VERSION ""

NS_ :

BS_:
BU_: Turbocharger OnBoardDataLogger OffBoardDiagnosticTool2 OffBoardDiagnosticTool1 FileServer ParkingBrakeController SeatControl2 FanDriveController SteeringColumnUnit CommunicationUnitRadio CommunicationUnitSatellite CommunicationUnitCellular PropulsionBatteryCharger ChassisController2 ChassisController1 EngineValveControl AuxiliaryHeater2 AuxiliaryHeater1 ClutchUnit RampControl InformationSystem1 SuspensionSystemController2 OilSensor VehicleDynamicStability ExhaustEmissionController TransmissionDisplay2 TransmissionDisplay1 ClimateControl2 WaterPumpController RearAxleSteeringController LightingOperatorControl SeatController1 IgnitionController2 IgnitionController1 TirePressureController CabController2 CabController1 PneumaticSystemController SuspensionSystemController1 HydraulicPumpController EnduranceBrakingSystem RetarderExhaustEngine2 OnBoardDiagnosticUnit HeadwayController RetarderExhaustEngine1 CabDisplay1 ManagementComputer VirtualTerminal OffVehicleGateway PowerTakeOffFront HitchControl AuxiliaryValveControl BodyController TractorTrailerBridge1 StarterSystem ElectricalSystem VehicleSecurity VehicleNavigation AerodynamicControl ElectricalChargingSystem ClimateControl1 TripRecorder InstrumentCluster SuspensionDriveAxle2 SuspensionDriveAxle1 SuspensionSteerAxle SteeringController FuelSystem CruiseControl RetarderDriveline RetarderEngine BrakesDriveAxle2 BrakesDriveAxle1 BrakesSystemController BrakesSteerAxle AxleDrive2 AxleDrive1 AxleSteering PowerTakeOff ShiftConsoleSecondary ShiftConsolePrimary Transmission2 Transmission1 Engine2 Engine1 Guidance Unnamed9933

BO_ 2566768382 CSA: 8 Vector__XXX
   SG_ EngStartEnableDevice2Config : 12|4@1+ (1,0) [0|15] "" Vector__XXX
   SG_ EngStartEnableDevice1Config : 8|4@1+ (1,0) [0|15] "" Vector__XXX
   SG_ EngStartEnableDevice2 : 2|2@1+ (1,0) [0|3] "" Vector__XXX
   SG_ EngStartEnableDevice1 : 0|2@1+ (1,0) [0|3] "" Vector__XXX

BO_ 2566811902 CVW: 8 Vector__XXX
   SG_ PoweredVehicleWeight : 0|16@1+ (10,0) [0|642550] "kg" Vector__XXX
   SG_ GrossCombinationVehicleWeight : 16|16@1+ (10,0) [0|642550] "kg" Vector__XXX

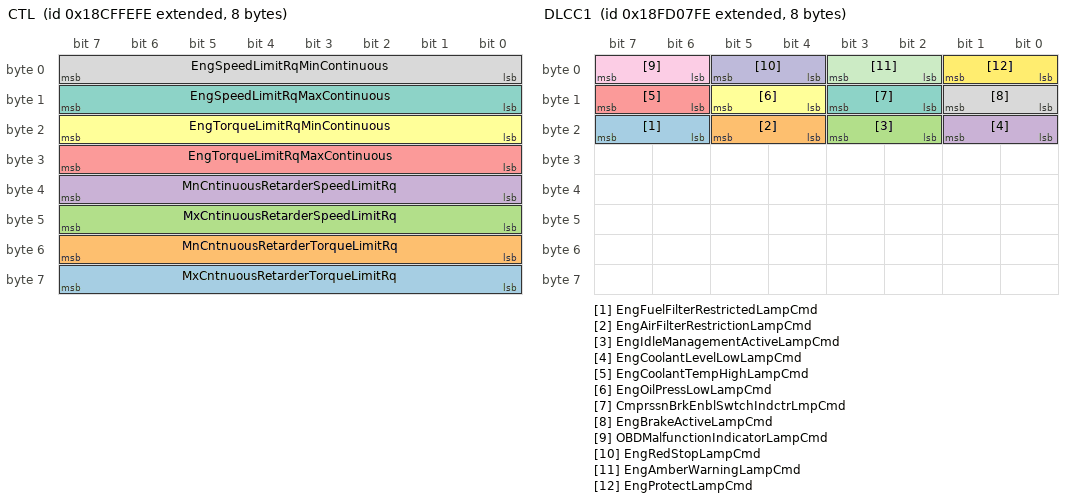
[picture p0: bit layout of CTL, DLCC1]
BO_ 2563768062 CTL: 8 Vector__XXX
   SG_ MxCntnuousRetarderTorqueLimitRq : 56|8@1+ (1,-125) [-125|125] "%" Vector__XXX
   SG_ MnCntnuousRetarderTorqueLimitRq : 48|8@1+ (1,-125) [-125|125] "%" Vector__XXX
   SG_ MxCntinuousRetarderSpeedLimitRq : 40|8@1+ (32,0) [0|8000] "rpm" Vector__XXX
   SG_ MnCntinuousRetarderSpeedLimitRq : 32|8@1+ (32,0) [0|8000] "rpm" Vector__XXX
   SG_ EngTorqueLimitRqMaxContinuous : 24|8@1+ (1,-125) [-125|125] "%" Vector__XXX
   SG_ EngTorqueLimitRqMinContinuous : 16|8@1+ (1,-125) [-125|125] "%" Vector__XXX
   SG_ EngSpeedLimitRqMaxContinuous : 8|8@1+ (32,0) [0|8000] "rpm" Vector__XXX
   SG_ EngSpeedLimitRqMinContinuous : 0|8@1+ (32,0) [0|8000] "rpm" Vector__XXX

BO_ 2633924862 CT6: 8 Vector__XXX
   SG_ EngAverageCombustionTime : 16|16@1+ (0.01,0) [0|642.55] "ms" Vector__XXX
   SG_ EngDesiredCombustionTime : 0|16@1+ (0.01,0) [0|642.55] "ms" Vector__XXX

BO_ 2633924606 CT5: 8 Vector__XXX
   SG_ EngCyl20CombustionTime : 48|16@1+ (0.01,0) [0|642.55] "ms" Vector__XXX
   SG_ EngCyl19CombustionTime : 32|16@1+ (0.01,0) [0|642.55] "ms" Vector__XXX
   SG_ EngCyl18CombustionTime : 16|16@1+ (0.01,0) [0|642.55] "ms" Vector__XXX
   SG_ EngCyl17CombustionTime : 0|16@1+ (0.01,0) [0|642.55] "ms" Vector__XXX

BO_ 2633924350 CT4: 8 Vector__XXX
   SG_ EngCyl16CombustionTime : 48|16@1+ (0.01,0) [0|642.55] "ms" Vector__XXX
   SG_ EngCyl15CombustionTime : 32|16@1+ (0.01,0) [0|642.55] "ms" Vector__XXX
   SG_ EngCyl14CombustionTime : 16|16@1+ (0.01,0) [0|642.55] "ms" Vector__XXX
   SG_ EngCyl13CombustionTime : 0|16@1+ (0.01,0) [0|642.55] "ms" Vector__XXX

BO_ 2633924094 CT3: 8 Vector__XXX
   SG_ EngCyl12CombustionTime : 48|16@1+ (0.01,0) [0|642.55] "ms" Vector__XXX
   SG_ EngCyl11CombustionTime : 32|16@1+ (0.01,0) [0|642.55] "ms" Vector__XXX
   SG_ EngCyl10CombustionTime : 16|16@1+ (0.01,0) [0|642.55] "ms" Vector__XXX
   SG_ EngCyl9CombustionTime : 0|16@1+ (0.01,0) [0|642.55] "ms" Vector__XXX

BO_ 2633923838 CT2: 8 Vector__XXX
   SG_ EngCyl8CombustionTime : 48|16@1+ (0.01,0) [0|642.55] "ms" Vector__XXX
   SG_ EngCyl7CombustionTime : 32|16@1+ (0.01,0) [0|642.55] "ms" Vector__XXX
   SG_ EngCyl6CombustionTime : 16|16@1+ (0.01,0) [0|642.55] "ms" Vector__XXX
   SG_ EngCyl5CombustionTime : 0|16@1+ (0.01,0) [0|642.55] "ms" Vector__XXX

BO_ 2633923582 CT1: 8 Vector__XXX
   SG_ EngCyl4CombustionTime : 48|16@1+ (0.01,0) [0|642.55] "ms" Vector__XXX
   SG_ EngCyl3CombustionTime : 32|16@1+ (0.01,0) [0|642.55] "ms" Vector__XXX
   SG_ EngCyl2CombustionTime : 16|16@1+ (0.01,0) [0|642.55] "ms" Vector__XXX
   SG_ EngCyl1CombustionTime : 0|16@1+ (0.01,0) [0|642.55] "ms" Vector__XXX

BO_ 2633878014 CMI: 8 Vector__XXX
   SG_ TotalCountOfConfigChangesMade : 0|16@1+ (1,0) [0|64255] "counts" Vector__XXX

BO_ 2566771966 CM3: 8 Vector__XXX
   SG_ TransOilLevelRq : 16|2@1+ (1,0) [0|3] "" Vector__XXX
   SG_ FifthWheelReleaseCtrl : 8|2@1+ (1,0) [0|3] "" Vector__XXX
   SG_ FfthWhlRlaseCtrlSecurityLockout : 10|2@1+ (1,0) [0|3] "" Vector__XXX
   SG_ TransferCaseSelectorSwitch : 0|3@1+ (1,0) [0|7] "" Vector__XXX

BO_ 2564882174 CM1: 8 Vector__XXX
   SG_ DslPrtcltFltrRgnrtonForceSwitch : 42|2@1+ (1,0) [0|3] "" Vector__XXX
   SG_ DslPrtcltFltrRgnrtnInhbitSwitch : 40|2@1+ (1,0) [0|3] "" Vector__XXX
   SG_ SelectedMaxVehicleSpeedLimit : 56|8@1+ (1,0) [0|250] "" Vector__XXX
   SG_ RqCabZoneHeating : 54|2@1+ (1,0) [0|3] "" Vector__XXX
   SG_ RqEngZoneHeating : 52|2@1+ (1,0) [0|3] "" Vector__XXX
   SG_ AuxHeaterModeRq : 48|4@1+ (1,0) [0|15] "" Vector__XXX
   SG_ EngAutomaticStartEnableSwitch : 46|2@1+ (1,0) [0|3] "" Vector__XXX
   SG_ AtmaticGearShiftingEnableSwitch : 44|2@1+ (1,0) [0|3] "" Vector__XXX
   SG_ VhclLmtngSpdGvernorEnableSwitch : 38|2@1+ (1,0) [0|3] "" Vector__XXX
   SG_ VhclLmtngSpdGvrnrIncrmentSwitch : 36|2@1+ (1,0) [0|3] "" Vector__XXX
   SG_ VhclLmtngSpdGvrnrDcrementSwitch : 34|2@1+ (1,0) [0|3] "" Vector__XXX
   SG_ SeatBeltSwitch : 30|2@1+ (1,0) [0|3] "" Vector__XXX
   SG_ OperatorSeatDirectionSwitch : 28|2@1+ (1,0) [0|3] "" Vector__XXX
   SG_ BatteryMainSwitchHoldRq : 26|2@1+ (1,0) [0|3] "" Vector__XXX
   SG_ AuxHeaterCoolantPumpRq : 24|2@1+ (1,0) [0|3] "" Vector__XXX
   SG_ CabInteriorTempCmd : 8|16@1+ (0.03125,-273) [-273|1734.97] "deg C" Vector__XXX
   SG_ RqedPercentFanSpeed : 0|8@1+ (0.4,0) [0|100] "%" Vector__XXX

BO_ 2563833598 CL: 8 Vector__XXX
   SG_ IlluminationBrightnessPercent : 0|8@1+ (0.4,0) [0|100] "%" Vector__XXX

BO_ 2566843390 CI: 8 Vector__XXX
   SG_ UnitNumber : 24|8@1+ (1,0) [0|255] "" Vector__XXX
   SG_ SerialNumber : 16|8@1+ (1,0) [0|255] "" Vector__XXX
   SG_ Model : 8|8@1+ (1,0) [0|255] "" Vector__XXX
   SG_ Make : 0|8@1+ (1,0) [0|255] "" Vector__XXX

BO_ 2566844926 CCVS: 8 Vector__XXX
   SG_ ParkBrakeReleaseInhibitRq : 6|2@1+ (1,0) [0|3] "" Vector__XXX
   SG_ PTOGovernorState : 48|5@1+ (1,0) [0|31] "" Vector__XXX
   SG_ EngShutdownOverrideSwitch : 62|2@1+ (1,0) [0|3] "" Vector__XXX
   SG_ EngTestModeSwitch : 60|2@1+ (1,0) [0|3] "" Vector__XXX
   SG_ EngIdleDecrementSwitch : 58|2@1+ (1,0) [0|3] "" Vector__XXX
   SG_ EngIdleIncrementSwitch : 56|2@1+ (1,0) [0|3] "" Vector__XXX
   SG_ CruiseCtrlStates : 53|3@1+ (1,0) [0|7] "" Vector__XXX
   SG_ CruiseCtrlSetSpeed : 40|8@1+ (1,0) [0|250] "km/h" Vector__XXX
   SG_ CruiseCtrlAccelerateSwitch : 38|2@1+ (1,0) [0|3] "" Vector__XXX
   SG_ CruiseCtrlResumeSwitch : 36|2@1+ (1,0) [0|3] "" Vector__XXX
   SG_ CruiseCtrlCoastSwitch : 34|2@1+ (1,0) [0|3] "" Vector__XXX
   SG_ CruiseCtrlSetSwitch : 32|2@1+ (1,0) [0|3] "" Vector__XXX
   SG_ ClutchSwitch : 30|2@1+ (1,0) [0|3] "" Vector__XXX
   SG_ BrakeSwitch : 28|2@1+ (1,0) [0|3] "" Vector__XXX
   SG_ CruiseCtrlEnableSwitch : 26|2@1+ (1,0) [0|3] "" Vector__XXX
   SG_ CruiseCtrlActive : 24|2@1+ (1,0) [0|3] "" Vector__XXX
   SG_ WheelBasedVehicleSpeed : 8|16@1+ (0.00390625,0) [0|250.996] "km/h" Vector__XXX
   SG_ CruiseCtrlPauseSwitch : 4|2@1+ (1,0) [0|3] "" Vector__XXX
   SG_ ParkingBrakeSwitch : 2|2@1+ (1,0) [0|3] "" Vector__XXX
   SG_ TwoSpeedAxleSwitch : 0|2@1+ (1,0) [0|3] "" Vector__XXX

BO_ 2566843902 CCSS: 8 Vector__XXX
   SG_ CruiseCtrlLowSetLimitSpeed : 16|8@1+ (1,0) [0|250] "km/h" Vector__XXX
   SG_ CruiseCtrlHighSetLimitSpeed : 8|8@1+ (1,0) [0|250] "km/h" Vector__XXX
   SG_ MaxVehicleSpeedLimit : 0|8@1+ (1,0) [0|250] "km/h" Vector__XXX

BO_ 2566809598 CCC: 8 Vector__XXX
   SG_ AuxHeaterMaxOutputPower : 0|16@1+ (2,0) [0|128510] "W" Vector__XXX

BO_ 2633940222 CBI: 16 Vector__XXX
   SG_ TripServiceBrakeApps : 96|32@1+ (1,0) [0|4.22786e+09] "appl" Vector__XXX
   SG_ TripServiceBrakeDistance : 64|32@1+ (0.125,0) [0|5.26385e+08] "km" Vector__XXX
   SG_ TripCompressionBrakeDistance : 32|32@1+ (0.125,0) [0|5.26385e+08] "km" Vector__XXX
   SG_ TotalCompressionBrakeDistance : 0|32@1+ (0.125,0) [0|5.26385e+08] "km" Vector__XXX

BO_ 2566775294 CACI: 8 Vector__XXX
   SG_ CbA_CRfrgrntCmprssorOutletPress : 0|8@1+ (16,0) [0|4000] "kPa" Vector__XXX

BO_ 2566803710 BT1: 8 Vector__XXX
   SG_ Battery2Temp : 8|8@1+ (1,-40) [-40|210] "deg C" Vector__XXX
   SG_ Battery1Temp : 0|8@1+ (1,-40) [-40|210] "deg C" Vector__XXX

BO_ 2566719486 DLCC1: 8 Vector__XXX
   SG_ EngFuelFilterRestrictedLampCmd : 22|2@1+ (1,0) [0|3] "" Vector__XXX
   SG_ EngAirFilterRestrictionLampCmd : 20|2@1+ (1,0) [0|3] "" Vector__XXX
   SG_ EngIdleManagementActiveLampCmd : 18|2@1+ (1,0) [0|3] "" Vector__XXX
   SG_ EngCoolantLevelLowLampCmd : 16|2@1+ (1,0) [0|3] "" Vector__XXX
   SG_ EngCoolantTempHighLampCmd : 14|2@1+ (1,0) [0|3] "" Vector__XXX
   SG_ EngOilPressLowLampCmd : 12|2@1+ (1,0) [0|3] "" Vector__XXX
   SG_ CmprssnBrkEnblSwtchIndctrLmpCmd : 10|2@1+ (1,0) [0|3] "" Vector__XXX
   SG_ EngBrakeActiveLampCmd : 8|2@1+ (1,0) [0|3] "" Vector__XXX
   SG_ OBDMalfunctionIndicatorLampCmd : 6|2@1+ (1,0) [0|3] "" Vector__XXX
   SG_ EngRedStopLampCmd : 4|2@1+ (1,0) [0|3] "" Vector__XXX
   SG_ EngAmberWarningLampCmd : 2|2@1+ (1,0) [0|3] "" Vector__XXX
   SG_ EngProtectLampCmd : 0|2@1+ (1,0) [0|3] "" Vector__XXX

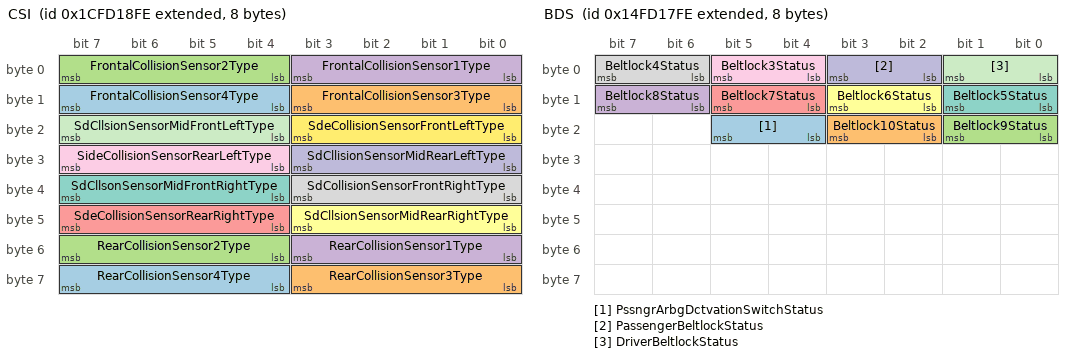
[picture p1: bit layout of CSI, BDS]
BO_ 2633832702 CSI: 8 Vector__XXX
   SG_ RearCollisionSensor4Type : 60|4@1+ (1,0) [0|15] "" Vector__XXX
   SG_ RearCollisionSensor3Type : 56|4@1+ (1,0) [0|15] "" Vector__XXX
   SG_ RearCollisionSensor2Type : 52|4@1+ (1,0) [0|15] "" Vector__XXX
   SG_ RearCollisionSensor1Type : 48|4@1+ (1,0) [0|15] "" Vector__XXX
   SG_ SdeCollisionSensorRearRightType : 44|4@1+ (1,0) [0|15] "" Vector__XXX
   SG_ SdCllsionSensorMidRearRightType : 40|4@1+ (1,0) [0|15] "" Vector__XXX
   SG_ SdCllsonSensorMidFrontRightType : 36|4@1+ (1,0) [0|15] "" Vector__XXX
   SG_ SdCollisionSensorFrontRightType : 32|4@1+ (1,0) [0|15] "" Vector__XXX
   SG_ SideCollisionSensorRearLeftType : 28|4@1+ (1,0) [0|15] "" Vector__XXX
   SG_ SdCllisionSensorMidRearLeftType : 24|4@1+ (1,0) [0|15] "" Vector__XXX
   SG_ SdCllsionSensorMidFrontLeftType : 20|4@1+ (1,0) [0|15] "" Vector__XXX
   SG_ SdeCollisionSensorFrontLeftType : 16|4@1+ (1,0) [0|15] "" Vector__XXX
   SG_ FrontalCollisionSensor4Type : 12|4@1+ (1,0) [0|15] "" Vector__XXX
   SG_ FrontalCollisionSensor3Type : 8|4@1+ (1,0) [0|15] "" Vector__XXX
   SG_ FrontalCollisionSensor2Type : 4|4@1+ (1,0) [0|15] "" Vector__XXX
   SG_ FrontalCollisionSensor1Type : 0|4@1+ (1,0) [0|15] "" Vector__XXX

BO_ 2163223550 CN: 8 Vector__XXX
   SG_ CrashChecksum : 60|4@1+ (1,0) [0|15] "" Vector__XXX
   SG_ CrashCounter : 56|4@1+ (1,0) [0|15] "" Vector__XXX
   SG_ CrashType : 0|5@1+ (5,0) [0|0] "" Vector__XXX

BO_ 2566714878 CAC2P: 8 Vector__XXX
   SG_ EngChrgArClr2PrcoolerEfficiency : 32|8@1+ (0.4,0) [0|100] "%" Vector__XXX
   SG_ EngChrgArClr2PrcoolerOutletTemp : 16|16@1+ (0.03125,-273) [-273|1734.97] "deg C" Vector__XXX
   SG_ EngChrgArClr2PrcoolerIntakeTemp : 0|16@1+ (0.03125,-273) [-273|1734.97] "deg C" Vector__XXX

BO_ 2566714622 CAC2: 8 Vector__XXX
   SG_ EngChargeAirCooler2Efficiency : 48|8@1+ (0.4,0) [0|100] "%" Vector__XXX
   SG_ EngChrgAirCooler2AmbientAirTemp : 32|16@1+ (0.03125,-273) [-273|1734.97] "deg C" Vector__XXX
   SG_ EngChargeAirCooler2OutletTemp : 16|16@1+ (0.03125,-273) [-273|1734.97] "deg C" Vector__XXX
   SG_ EngChargeAirCooler2IntakeTemp : 0|16@1+ (0.03125,-273) [-273|1734.97] "deg C" Vector__XXX

BO_ 2566715390 CAC1P: 8 Vector__XXX
   SG_ EngChrgArClr1PrcoolerEfficiency : 32|8@1+ (0.4,0) [0|100] "%" Vector__XXX
   SG_ EngChrgArClr1PrcoolerOutletTemp : 16|16@1+ (0.03125,-273) [-273|1734.97] "deg C" Vector__XXX
   SG_ EngChrgArClr1PrcoolerIntakeTemp : 0|16@1+ (0.03125,-273) [-273|1734.97] "deg C" Vector__XXX

BO_ 2566715134 CAC1: 8 Vector__XXX
   SG_ EngChargeAirCooler1Efficiency : 32|8@1+ (0.4,0) [0|100] "%" Vector__XXX
   SG_ EngChrgAirCooler1AmbientAirTemp : 16|16@1+ (0.03125,-273) [-273|1734.97] "deg C" Vector__XXX
   SG_ EngChargeAirCooler1IntakeTemp : 0|16@1+ (0.03125,-273) [-273|1734.97] "deg C" Vector__XXX

BO_ 2365400830 BJM9: 8 Vector__XXX
   SG_ Joystick9Button9PressedStatus : 62|2@1+ (1,0) [0|3] "" Vector__XXX
   SG_ Joystick9Button10PressedStatus : 60|2@1+ (1,0) [0|3] "" Vector__XXX
   SG_ Joystick9Button11PressedStatus : 58|2@1+ (1,0) [0|3] "" Vector__XXX
   SG_ Joystick9Button12PressedStatus : 56|2@1+ (1,0) [0|3] "" Vector__XXX
   SG_ Joystick9Button5PressedStatus : 54|2@1+ (1,0) [0|3] "" Vector__XXX
   SG_ Joystick9Button6PressedStatus : 52|2@1+ (1,0) [0|3] "" Vector__XXX
   SG_ Joystick9Button7PressedStatus : 50|2@1+ (1,0) [0|3] "" Vector__XXX
   SG_ Joystick9Button8PressedStatus : 48|2@1+ (1,0) [0|3] "" Vector__XXX
   SG_ Joystick9Button1PressedStatus : 46|2@1+ (1,0) [0|3] "" Vector__XXX
   SG_ Joystick9Button2PressedStatus : 44|2@1+ (1,0) [0|3] "" Vector__XXX
   SG_ Joystick9Button3PressedStatus : 42|2@1+ (1,0) [0|3] "" Vector__XXX
   SG_ Joystick9Button4PressedStatus : 40|2@1+ (1,0) [0|3] "" Vector__XXX
   SG_ Joystick9XAxisDetentPosStatus : 38|2@1+ (1,0) [0|3] "" Vector__XXX
   SG_ Joystick9YAxisDetentPosStatus : 36|2@1+ (1,0) [0|3] "" Vector__XXX
   SG_ Joystick9YAxisPos : 22|10@1+ (0.1,0) [0|102] "%" Vector__XXX
   SG_ Jystck9YAxsLvrFrwrdPstvPsStatus : 20|2@1+ (1,0) [0|3] "" Vector__XXX
   SG_ Jystck9YAxsLvrBckNgtvePosStatus : 18|2@1+ (1,0) [0|3] "" Vector__XXX
   SG_ Joystick9YAxisNeutralPosStatus : 16|2@1+ (1,0) [0|3] "" Vector__XXX
   SG_ Joystick9XAxisPos : 6|10@1+ (0.1,0) [0|102] "%" Vector__XXX
   SG_ Jystck9XAxsLvrRghtPstvPosStatus : 4|2@1+ (1,0) [0|3] "" Vector__XXX
   SG_ Jystck9XAxsLvrLftNgtvePosStatus : 2|2@1+ (1,0) [0|3] "" Vector__XXX
   SG_ Joystick9XAxisNeutralPosStatus : 0|2@1+ (1,0) [0|3] "" Vector__XXX

BO_ 2365401342 BJM8: 8 Vector__XXX
   SG_ Joystick8Button9PressedStatus : 62|2@1+ (1,0) [0|3] "" Vector__XXX
   SG_ Joystick8Button10PressedStatus : 60|2@1+ (1,0) [0|3] "" Vector__XXX
   SG_ Joystick8Button11PressedStatus : 58|2@1+ (1,0) [0|3] "" Vector__XXX
   SG_ Joystick8Button12PressedStatus : 56|2@1+ (1,0) [0|3] "" Vector__XXX
   SG_ Joystick8Button5PressedStatus : 54|2@1+ (1,0) [0|3] "" Vector__XXX
   SG_ Joystick8Button6PressedStatus : 52|2@1+ (1,0) [0|3] "" Vector__XXX
   SG_ Joystick8Button7PressedStatus : 50|2@1+ (1,0) [0|3] "" Vector__XXX
   SG_ Joystick8Button8PressedStatus : 48|2@1+ (1,0) [0|3] "" Vector__XXX
   SG_ Joystick8Button1PressedStatus : 46|2@1+ (1,0) [0|3] "" Vector__XXX
   SG_ Joystick8Button2PressedStatus : 44|2@1+ (1,0) [0|3] "" Vector__XXX
   SG_ Joystick8Button3PressedStatus : 42|2@1+ (1,0) [0|3] "" Vector__XXX
   SG_ Joystick8Button4PressedStatus : 40|2@1+ (1,0) [0|3] "" Vector__XXX
   SG_ Joystick8XAxisDetentPosStatus : 38|2@1+ (1,0) [0|3] "" Vector__XXX
   SG_ Joystick8YAxisDetentPosStatus : 36|2@1+ (1,0) [0|3] "" Vector__XXX
   SG_ Joystick8YAxisPos : 22|10@1+ (0.1,0) [0|102] "%" Vector__XXX
   SG_ Jystck8YAxsLvrFrwrdPstvPsStatus : 20|2@1+ (1,0) [0|3] "" Vector__XXX
   SG_ Jystck8YAxsLvrBckNgtvePosStatus : 18|2@1+ (1,0) [0|3] "" Vector__XXX
   SG_ Joystick8YAxisNeutralPosStatus : 16|2@1+ (1,0) [0|3] "" Vector__XXX
   SG_ Joystick8XAxisPos : 6|10@1+ (0.1,0) [0|102] "%" Vector__XXX
   SG_ Jystck8XAxsLvrRghtPstvPosStatus : 4|2@1+ (1,0) [0|3] "" Vector__XXX
   SG_ Jystck8XAxsLvrLftNgtvePosStatus : 2|2@1+ (1,0) [0|3] "" Vector__XXX
   SG_ Joystick8XAxisNeutralPosStatus : 0|2@1+ (1,0) [0|3] "" Vector__XXX

BO_ 2365401854 BJM7: 8 Vector__XXX
   SG_ Joystick7Button9PressedStatus : 62|2@1+ (1,0) [0|3] "" Vector__XXX
   SG_ Joystick7Button10PressedStatus : 60|2@1+ (1,0) [0|3] "" Vector__XXX
   SG_ Joystick7Button11PressedStatus : 58|2@1+ (1,0) [0|3] "" Vector__XXX
   SG_ Joystick7Button12PressedStatus : 56|2@1+ (1,0) [0|3] "" Vector__XXX
   SG_ Joystick7Button5PressedStatus : 54|2@1+ (1,0) [0|3] "" Vector__XXX
   SG_ Joystick7Button6PressedStatus : 52|2@1+ (1,0) [0|3] "" Vector__XXX
   SG_ Joystick7Button7PressedStatus : 50|2@1+ (1,0) [0|3] "" Vector__XXX
   SG_ Joystick7Button8PressedStatus : 48|2@1+ (1,0) [0|3] "" Vector__XXX
   SG_ Joystick7Button1PressedStatus : 46|2@1+ (1,0) [0|3] "" Vector__XXX
   SG_ Joystick7Button2PressedStatus : 44|2@1+ (1,0) [0|3] "" Vector__XXX
   SG_ Joystick7Button3PressedStatus : 42|2@1+ (1,0) [0|3] "" Vector__XXX
   SG_ Joystick7Button4PressedStatus : 40|2@1+ (1,0) [0|3] "" Vector__XXX
   SG_ Joystick7XAxisDetentPosStatus : 38|2@1+ (1,0) [0|3] "" Vector__XXX
   SG_ Joystick7YAxisDetentPosStatus : 36|2@1+ (1,0) [0|3] "" Vector__XXX
   SG_ Joystick7YAxisPos : 22|10@1+ (0.1,0) [0|102] "%" Vector__XXX
   SG_ Jystck7YAxsLvrFrwrdPstvPsStatus : 20|2@1+ (1,0) [0|3] "" Vector__XXX
   SG_ Jystck7YAxsLvrBckNgtvePosStatus : 18|2@1+ (1,0) [0|3] "" Vector__XXX
   SG_ Joystick7YAxisNeutralPosStatus : 16|2@1+ (1,0) [0|3] "" Vector__XXX
   SG_ Joystick7XAxisPos : 6|10@1+ (0.1,0) [0|102] "%" Vector__XXX
   SG_ Jystck7XAxsLvrRghtPstvPosStatus : 4|2@1+ (1,0) [0|3] "" Vector__XXX
   SG_ Jystck7XAxsLvrLftNgtvePosStatus : 2|2@1+ (1,0) [0|3] "" Vector__XXX
   SG_ Joystick7XAxisNeutralPosStatus : 0|2@1+ (1,0) [0|3] "" Vector__XXX

BO_ 2365402366 BJM6: 8 Vector__XXX
   SG_ Joystick6Button9PressedStatus : 62|2@1+ (1,0) [0|3] "" Vector__XXX
   SG_ Joystick6Button10PressedStatus : 60|2@1+ (1,0) [0|3] "" Vector__XXX
   SG_ Joystick6Button11PressedStatus : 58|2@1+ (1,0) [0|3] "" Vector__XXX
   SG_ Joystick6Button12PressedStatus : 56|2@1+ (1,0) [0|3] "" Vector__XXX
   SG_ Joystick6Button5PressedStatus : 54|2@1+ (1,0) [0|3] "" Vector__XXX
   SG_ Joystick6Button6PressedStatus : 52|2@1+ (1,0) [0|3] "" Vector__XXX
   SG_ Joystick6Button7PressedStatus : 50|2@1+ (1,0) [0|3] "" Vector__XXX
   SG_ Joystick6Button8PressedStatus : 48|2@1+ (1,0) [0|3] "" Vector__XXX
   SG_ Joystick6Button1PressedStatus : 46|2@1+ (1,0) [0|3] "" Vector__XXX
   SG_ Joystick6Button2PressedStatus : 44|2@1+ (1,0) [0|3] "" Vector__XXX
   SG_ Joystick6Button3PressedStatus : 42|2@1+ (1,0) [0|3] "" Vector__XXX
   SG_ Joystick6Button4PressedStatus : 40|2@1+ (1,0) [0|3] "" Vector__XXX
   SG_ Joystick6XAxisDetentPosStatus : 38|2@1+ (1,0) [0|3] "" Vector__XXX
   SG_ Joystick6YAxisDetentPosStatus : 36|2@1+ (1,0) [0|3] "" Vector__XXX
   SG_ Joystick6YAxisPos : 22|10@1+ (0.1,0) [0|102] "%" Vector__XXX
   SG_ Jystck6YAxsLvrFrwrdPstvPsStatus : 20|2@1+ (1,0) [0|3] "" Vector__XXX
   SG_ Jystck6YAxsLvrBckNgtvePosStatus : 18|2@1+ (1,0) [0|3] "" Vector__XXX
   SG_ Joystick6YAxisNeutralPosStatus : 16|2@1+ (1,0) [0|3] "" Vector__XXX
   SG_ Joystick6XAxisPos : 6|10@1+ (0.1,0) [0|102] "%" Vector__XXX
   SG_ Jystck6XAxsLvrRghtPstvPosStatus : 4|2@1+ (1,0) [0|3] "" Vector__XXX
   SG_ Jystck6XAxsLvrLftNgtvePosStatus : 2|2@1+ (1,0) [0|3] "" Vector__XXX
   SG_ Joystick6XAxisNeutralPosStatus : 0|2@1+ (1,0) [0|3] "" Vector__XXX

BO_ 2365402878 BJM5: 8 Vector__XXX
   SG_ Joystick5Button9PressedStatus : 62|2@1+ (1,0) [0|3] "" Vector__XXX
   SG_ Joystick5Button10PressedStatus : 60|2@1+ (1,0) [0|3] "" Vector__XXX
   SG_ Joystick5Button11PressedStatus : 58|2@1+ (1,0) [0|3] "" Vector__XXX
   SG_ Joystick5Button12PressedStatus : 56|2@1+ (1,0) [0|3] "" Vector__XXX
   SG_ Joystick5Button5PressedStatus : 54|2@1+ (1,0) [0|3] "" Vector__XXX
   SG_ Joystick5Button6PressedStatus : 52|2@1+ (1,0) [0|3] "" Vector__XXX
   SG_ Joystick5Button7PressedStatus : 50|2@1+ (1,0) [0|3] "" Vector__XXX
   SG_ Joystick5Button8PressedStatus : 48|2@1+ (1,0) [0|3] "" Vector__XXX
   SG_ Joystick5Button1PressedStatus : 46|2@1+ (1,0) [0|3] "" Vector__XXX
   SG_ Joystick5Button2PressedStatus : 44|2@1+ (1,0) [0|3] "" Vector__XXX
   SG_ Joystick5Button3PressedStatus : 42|2@1+ (1,0) [0|3] "" Vector__XXX
   SG_ Joystick5Button4PressedStatus : 40|2@1+ (1,0) [0|3] "" Vector__XXX
   SG_ Joystick5XAxisDetentPosStatus : 38|2@1+ (1,0) [0|3] "" Vector__XXX
   SG_ Joystick5YAxisDetentPosStatus : 36|2@1+ (1,0) [0|3] "" Vector__XXX
   SG_ Joystick5YAxisPos : 22|10@1+ (0.1,0) [0|102] "%" Vector__XXX
   SG_ Jystck5YAxsLvrFrwrdPstvPsStatus : 20|2@1+ (1,0) [0|3] "" Vector__XXX
   SG_ Jystck5YAxsLvrBckNgtvePosStatus : 18|2@1+ (1,0) [0|3] "" Vector__XXX
   SG_ Joystick5YAxisNeutralPosStatus : 16|2@1+ (1,0) [0|3] "" Vector__XXX
   SG_ Joystick5XAxisPos : 6|10@1+ (0.1,0) [0|102] "%" Vector__XXX
   SG_ Jystck5XAxsLvrRghtPstvPosStatus : 4|2@1+ (1,0) [0|3] "" Vector__XXX
   SG_ Jystck5XAxsLvrLftNgtvePosStatus : 2|2@1+ (1,0) [0|3] "" Vector__XXX
   SG_ Joystick5XAxisNeutralPosStatus : 0|2@1+ (1,0) [0|3] "" Vector__XXX

BO_ 2365403390 BJM4: 8 Vector__XXX
   SG_ Joystick4Button9PressedStatus : 62|2@1+ (1,0) [0|3] "" Vector__XXX
   SG_ Joystick4Button10PressedStatus : 60|2@1+ (1,0) [0|3] "" Vector__XXX
   SG_ Joystick4Button11PressedStatus : 58|2@1+ (1,0) [0|3] "" Vector__XXX
   SG_ Joystick4Button12PressedStatus : 56|2@1+ (1,0) [0|3] "" Vector__XXX
   SG_ Joystick4Button5PressedStatus : 54|2@1+ (1,0) [0|3] "" Vector__XXX
   SG_ Joystick4Button6PressedStatus : 52|2@1+ (1,0) [0|3] "" Vector__XXX
   SG_ Joystick4Button7PressedStatus : 50|2@1+ (1,0) [0|3] "" Vector__XXX
   SG_ Joystick4Button8PressedStatus : 48|2@1+ (1,0) [0|3] "" Vector__XXX
   SG_ Joystick4Button1PressedStatus : 46|2@1+ (1,0) [0|3] "" Vector__XXX
   SG_ Joystick4Button2PressedStatus : 44|2@1+ (1,0) [0|3] "" Vector__XXX
   SG_ Joystick4Button3PressedStatus : 42|2@1+ (1,0) [0|3] "" Vector__XXX
   SG_ Joystick4Button4PressedStatus : 40|2@1+ (1,0) [0|3] "" Vector__XXX
   SG_ Joystick4XAxisDetentPosStatus : 38|2@1+ (1,0) [0|3] "" Vector__XXX
   SG_ Joystick4YAxisDetentPosStatus : 36|2@1+ (1,0) [0|3] "" Vector__XXX
   SG_ Joystick4YAxisPos : 22|10@1+ (0.1,0) [0|102] "%" Vector__XXX
   SG_ Jystck4YAxsLvrFrwrdPstvPsStatus : 20|2@1+ (1,0) [0|3] "" Vector__XXX
   SG_ Jystck4YAxsLvrBckNgtvePosStatus : 18|2@1+ (1,0) [0|3] "" Vector__XXX
   SG_ Joystick4YAxisNeutralPosStatus : 16|2@1+ (1,0) [0|3] "" Vector__XXX
   SG_ Joystick4XAxisPos : 6|10@1+ (0.1,0) [0|102] "%" Vector__XXX
   SG_ Jystck4XAxsLvrRghtPstvPosStatus : 4|2@1+ (1,0) [0|3] "" Vector__XXX
   SG_ Jystck4XAxsLvrLftNgtvePosStatus : 2|2@1+ (1,0) [0|3] "" Vector__XXX
   SG_ Joystick4XAxisNeutralPosStatus : 0|2@1+ (1,0) [0|3] "" Vector__XXX

BO_ 2365400318 BJM10: 8 Vector__XXX
   SG_ Joystick10Button9PressedStatus : 62|2@1+ (1,0) [0|3] "" Vector__XXX
   SG_ Joystick10Button10PressedStatus : 60|2@1+ (1,0) [0|3] "" Vector__XXX
   SG_ Joystick10Button11PressedStatus : 58|2@1+ (1,0) [0|3] "" Vector__XXX
   SG_ Joystick10Button12PressedStatus : 56|2@1+ (1,0) [0|3] "" Vector__XXX
   SG_ Joystick10Button5PressedStatus : 54|2@1+ (1,0) [0|3] "" Vector__XXX
   SG_ Joystick10Button6PressedStatus : 52|2@1+ (1,0) [0|3] "" Vector__XXX
   SG_ Joystick10Button7PressedStatus : 50|2@1+ (1,0) [0|3] "" Vector__XXX
   SG_ Joystick10Button8PressedStatus : 48|2@1+ (1,0) [0|3] "" Vector__XXX
   SG_ Joystick10Button1PressedStatus : 46|2@1+ (1,0) [0|3] "" Vector__XXX
   SG_ Joystick10Button2PressedStatus : 44|2@1+ (1,0) [0|3] "" Vector__XXX
   SG_ Joystick10Button3PressedStatus : 42|2@1+ (1,0) [0|3] "" Vector__XXX
   SG_ Joystick10Button4PressedStatus : 40|2@1+ (1,0) [0|3] "" Vector__XXX
   SG_ Joystick10XAxisDetentPosStatus : 38|2@1+ (1,0) [0|3] "" Vector__XXX
   SG_ Joystick10YAxisDetentPosStatus : 36|2@1+ (1,0) [0|3] "" Vector__XXX
   SG_ Joystick10YAxisPos : 22|10@1+ (0.1,0) [0|102] "%" Vector__XXX
   SG_ Jystck10YAxsLvrFrwrdPstvPsSttus : 20|2@1+ (1,0) [0|3] "" Vector__XXX
   SG_ Jystck10YAxsLvrBckNgtvPosStatus : 18|2@1+ (1,0) [0|3] "" Vector__XXX
   SG_ Joystick10YAxisNeutralPosStatus : 16|2@1+ (1,0) [0|3] "" Vector__XXX
   SG_ Joystick10XAxisPos : 6|10@1+ (0.1,0) [0|102] "%" Vector__XXX
   SG_ Jystck10XAxsLvrRghtPstvPsStatus : 4|2@1+ (1,0) [0|3] "" Vector__XXX
   SG_ Jystck10XAxsLvrLftNgtvPosStatus : 2|2@1+ (1,0) [0|3] "" Vector__XXX
   SG_ Joystick10XAxisNeutralPosStatus : 0|2@1+ (1,0) [0|3] "" Vector__XXX

BO_ 2499614718 BDS: 8 Vector__XXX
   SG_ PssngrArbgDctvationSwitchStatus : 20|2@1+ (1,0) [0|3] "" Vector__XXX
   SG_ Beltlock10Status : 18|2@1+ (1,0) [0|3] "" Vector__XXX
   SG_ Beltlock9Status : 16|2@1+ (1,0) [0|3] "" Vector__XXX
   SG_ Beltlock8Status : 14|2@1+ (1,0) [0|3] "" Vector__XXX
   SG_ Beltlock7Status : 12|2@1+ (1,0) [0|3] "" Vector__XXX
   SG_ Beltlock6Status : 10|2@1+ (1,0) [0|3] "" Vector__XXX
   SG_ Beltlock5Status : 8|2@1+ (1,0) [0|3] "" Vector__XXX
   SG_ Beltlock4Status : 6|2@1+ (1,0) [0|3] "" Vector__XXX
   SG_ Beltlock3Status : 4|2@1+ (1,0) [0|3] "" Vector__XXX
   SG_ PassengerBeltlockStatus : 2|2@1+ (1,0) [0|3] "" Vector__XXX
   SG_ DriverBeltlockStatus : 0|2@1+ (1,0) [0|3] "" Vector__XXX

BO_ 2566722814 BCH2: 8 Vector__XXX
   SG_ BatteryCharger2OutputCurrent : 24|16@1+ (0.05,-1600) [-1600|1612.75] "A" Vector__XXX
   SG_ BatteryCharger2OutputVoltage : 8|16@1+ (0.05,0) [0|3212.75] "V" Vector__XXX
   SG_ BatteryCharger2PowerLineState : 4|2@1+ (1,0) [0|3] "" Vector__XXX
   SG_ BatteryCharger2State : 0|4@1+ (1,0) [0|15] "" Vector__XXX

BO_ 2566723070 BCH1: 8 Vector__XXX
   SG_ BatteryCharger1OutputCurrent : 24|16@1+ (0.05,-1600) [-1600|1612.75] "A" Vector__XXX
   SG_ BatteryCharger1OutputVoltage : 8|16@1+ (0.05,0) [0|3212.75] "V" Vector__XXX
   SG_ BatteryCharger1PowerLineState : 4|2@1+ (1,0) [0|3] "" Vector__XXX
   SG_ BatteryCharger1State : 0|4@1+ (1,0) [0|15] "" Vector__XXX

BO_ 2566725118 ATDT2: 8 Vector__XXX
   SG_ Aftrtrtmnt2ThrWyCtlystDffGsTemp : 16|16@1+ (0.03125,-273) [-273|1734.97] "deg C" Vector__XXX
   SG_ Aftrtrtmnt1ThrWyCtlystDffGsTemp : 0|16@1+ (0.03125,-273) [-273|1734.97] "deg C" Vector__XXX

BO_ 2566725374 ATDT1: 8 Vector__XXX
   SG_ Aftrtrtmnt2GsOxdtnCtlystDffGsTmp : 16|16@1+ (0.03125,-273) [-273|1734.97] "deg C" Vector__XXX
   SG_ Aftrtrtmnt1GsOxdtnCtlystDffGsTmp : 0|16@1+ (0.03125,-273) [-273|1734.97] "deg C" Vector__XXX

BO_ 2566712830 AT2WUDOC: 8 Vector__XXX
   SG_ Aftrtrtmnt2WrmUpDslOxdtnCtlystOt : 16|16@1+ (0.03125,-273) [-273|1734.97] "deg C" Vector__XXX
   SG_ Aftrtrtmnt2WrmUpDslOxdtnCtlystIn : 0|16@1+ (0.03125,-273) [-273|1734.97] "deg C" Vector__XXX

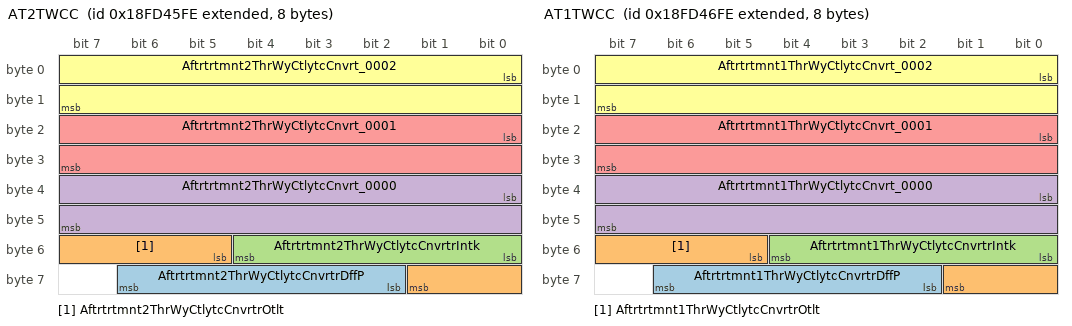
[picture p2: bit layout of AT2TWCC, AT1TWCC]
BO_ 2566735358 AT2TWCC: 8 Vector__XXX
   SG_ Aftrtrtmnt2ThrWyCtlytcCnvrtrDffP : 58|5@1+ (1,0) [0|31] "" Vector__XXX
   SG_ Aftrtrtmnt2ThrWyCtlytcCnvrtrOtlt : 53|5@1+ (1,0) [0|31] "" Vector__XXX
   SG_ Aftrtrtmnt2ThrWyCtlytcCnvrtrIntk : 48|5@1+ (1,0) [0|31] "" Vector__XXX
   SG_ Aftrtrtmnt2ThrWyCtlytcCnvrt_0000 : 32|16@1+ (0.1,0) [0|6425.5] "kPa" Vector__XXX
   SG_ Aftrtrtmnt2ThrWyCtlytcCnvrt_0001 : 16|16@1+ (0.03125,-273) [-273|1734.97] "deg C" Vector__XXX
   SG_ Aftrtrtmnt2ThrWyCtlytcCnvrt_0002 : 0|16@1+ (0.03125,-273) [-273|1734.97] "deg C" Vector__XXX

BO_ 2365393662 AT2OGC2: 8 Vector__XXX
   SG_ Aftrtrtmnt2OtltGsNOxSnsrNH3Crrct : 24|8@1+ (0.5,0) [0|125] "%" Vector__XXX
   SG_ Aftrtrtmnt2OtltGsNOxSnsrNO2Crrct : 16|8@1+ (0.5,0) [0|125] "%" Vector__XXX
   SG_ Aftrtrtmnt2OtltGsNOxSnsrCrrctnOf : 8|8@1+ (0.5,0) [0|125] "%/bar" Vector__XXX
   SG_ Aftrtrtmnt2OtltGsNOxSnsrCrr_0000 : 0|8@1+ (0.5,0) [0|125] "%/bar" Vector__XXX

BO_ 2365393918 AT2OGC1: 8 Vector__XXX
   SG_ Aftrtrtmnt2OtltGsNOxSnsrNwPrtDvt : 32|8@1+ (1,-125) [-125|125] "ppm" Vector__XXX
   SG_ Aftrtrtmnt2OtltGsNOxSnsrNwP_0000 : 16|16@1+ (0.1,-100) [-100|100] "%" Vector__XXX
   SG_ Aftrtrtmnt2OtltGsNOxSnsrHtrRtio : 0|16@1+ (0.001,0) [0|64.255] "" Vector__XXX

BO_ 2365394174 AT2IGC2: 8 Vector__XXX
   SG_ Aftrtrtmnt2IntkGsNOxSnsrNH3Crrct : 24|8@1+ (0.5,0) [0|125] "%" Vector__XXX
   SG_ Aftrtrtmnt2IntkGsNOxSnsrNO2Crrct : 16|8@1+ (0.5,0) [0|125] "%" Vector__XXX
   SG_ Aftrtrtmnt2IntkGsNOxSnsrCrrctnOf : 8|8@1+ (0.5,0) [0|125] "%/bar" Vector__XXX
   SG_ Aftrtrtmnt2IntkGsNOxSnsrCrr_0000 : 0|8@1+ (0.5,0) [0|125] "%/bar" Vector__XXX

BO_ 2365394430 AT2IGC1: 8 Vector__XXX
   SG_ Aftrtrtmnt2IntkGsNOxSnsrNwPrtDvt : 32|8@1+ (1,-125) [-125|125] "ppm" Vector__XXX
   SG_ Aftrtrtmnt2IntkGsNOxSnsrNwP_0000 : 16|16@1+ (0.1,-100) [-100|100] "%" Vector__XXX
   SG_ Aftrtrtmnt2IntkGsNOxSnsrHtrRtio : 0|16@1+ (0.001,0) [0|64.255] "" Vector__XXX

BO_ 2566735102 AT2FC2: 8 Vector__XXX
   SG_ Aftertreatment2FuelPress2Ctrl : 24|16@1+ (0.0025,0) [0|160.637] "%" Vector__XXX
   SG_ Aftrtrtmnt2FlFlwDvrterValveCtrl : 18|2@1+ (1,0) [0|3] "" Vector__XXX
   SG_ Aftrtreatment2FuelPumpRelayCtrl : 16|2@1+ (1,0) [0|3] "" Vector__XXX
   SG_ Aftertreatment2FuelPress2 : 0|16@1+ (0.1,0) [0|6425.5] "kPa" Vector__XXX

BO_ 2157313790 AT2DPFSSC: 8 Vector__XXX
   SG_ Aftrtrtmnt2DslPrtcltFltrStStndrd : 16|16@1+ (0.0025,0) [0|160.637] "%" Vector__XXX
   SG_ Aftrtrtmnt2DslPrtcltFltrStMnClbO : 0|16@1+ (0.0025,0) [0|160.637] "%" Vector__XXX

BO_ 2566724350 AT1WUDOC: 8 Vector__XXX
   SG_ Aftrtrtmnt1WrmUpDslOxdtnCtlystOt : 16|16@1+ (0.03125,-273) [-273|1734.97] "deg C" Vector__XXX
   SG_ Aftrtrtmnt1WrmUpDslOxdtnCtlystIn : 0|16@1+ (0.03125,-273) [-273|1734.97] "deg C" Vector__XXX

BO_ 2566735614 AT1TWCC: 8 Vector__XXX
   SG_ Aftrtrtmnt1ThrWyCtlytcCnvrtrDffP : 58|5@1+ (1,0) [0|31] "" Vector__XXX
   SG_ Aftrtrtmnt1ThrWyCtlytcCnvrtrOtlt : 53|5@1+ (1,0) [0|31] "" Vector__XXX
   SG_ Aftrtrtmnt1ThrWyCtlytcCnvrtrIntk : 48|5@1+ (1,0) [0|31] "" Vector__XXX
   SG_ Aftrtrtmnt1ThrWyCtlytcCnvrt_0000 : 32|16@1+ (0.1,0) [0|6425.5] "kPa" Vector__XXX
   SG_ Aftrtrtmnt1ThrWyCtlytcCnvrt_0001 : 16|16@1+ (0.03125,-273) [-273|1734.97] "deg C" Vector__XXX
   SG_ Aftrtrtmnt1ThrWyCtlytcCnvrt_0002 : 0|16@1+ (0.03125,-273) [-273|1734.97] "deg C" Vector__XXX

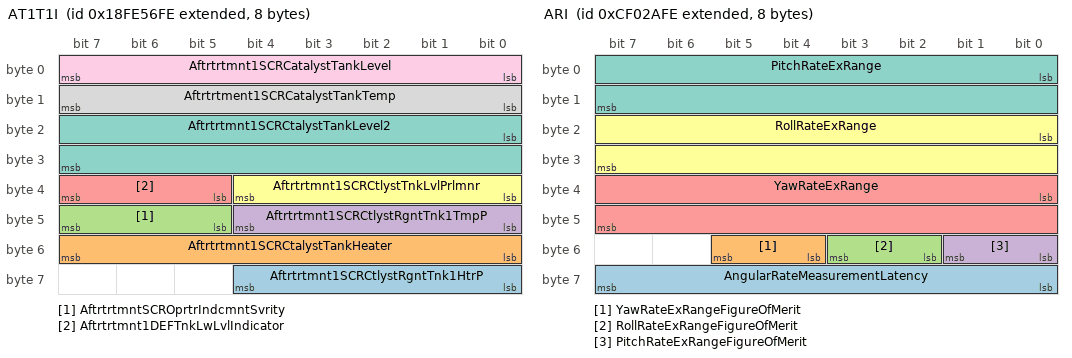
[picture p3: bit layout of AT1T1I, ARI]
BO_ 2566805246 AT1T1I: 8 Vector__XXX
   SG_ Aftrtrtmnt1SCRCtlystRgntTnk1HtrP : 56|5@1+ (1,0) [0|31] "" Vector__XXX
   SG_ Aftrtrtmnt1SCRCtalystTankHeater : 48|8@1+ (0.4,0) [0|100] "%" Vector__XXX
   SG_ AftrtrtmntSCROprtrIndcmntSvrity : 45|3@1+ (1,0) [0|7] "" Vector__XXX
   SG_ Aftrtrtmnt1SCRCtlystRgntTnk1TmpP : 40|5@1+ (1,0) [0|31] "" Vector__XXX
   SG_ Aftrtrtmnt1DEFTnkLwLvlIndicator : 37|3@1+ (1,0) [0|7] "" Vector__XXX
   SG_ Aftrtrtmnt1SCRCtlystTnkLvlPrlmnr : 32|5@1+ (1,0) [0|31] "" Vector__XXX
   SG_ Aftrtrtmnt1SCRCtalystTankLevel2 : 16|16@1+ (0.1,0) [0|6425.5] "mm" Vector__XXX
   SG_ Aftrtrtment1SCRCatalystTankTemp : 8|8@1+ (1,-40) [-40|210] "deg C" Vector__XXX
   SG_ Aftrtrtmnt1SCRCatalystTankLevel : 0|8@1+ (0.4,0) [0|100] "%" Vector__XXX

BO_ 2365394686 AT1OGC2: 8 Vector__XXX
   SG_ Aftrtrtmnt1OtltGsNOxSnsrNH3Crrct : 24|8@1+ (0.5,0) [0|125] "%" Vector__XXX
   SG_ Aftrtrtmnt1OtltGsNOxSnsrNO2Crrct : 16|8@1+ (0.5,0) [0|125] "%" Vector__XXX
   SG_ Aftrtrtmnt1OtltGsNOxSnsrCrrctnOf : 8|8@1+ (0.5,0) [0|125] "%/bar" Vector__XXX
   SG_ Aftrtrtmnt1OtltGsNOxSnsrCrr_0000 : 0|8@1+ (0.5,0) [0|125] "%/bar" Vector__XXX

BO_ 2365394942 AT1OGC1: 8 Vector__XXX
   SG_ Aftrtrtmnt1OtltGsNOxSnsrNwPrtDvt : 32|8@1+ (1,-125) [-125|125] "ppm" Vector__XXX
   SG_ Aftrtrtmnt1OtltGsNOxSnsrNwP_0000 : 16|16@1+ (0.1,-100) [-100|100] "%" Vector__XXX
   SG_ Aftrtrtmnt1OtltGsNOxSnsrHtrRtio : 0|16@1+ (0.001,0) [0|64.255] "" Vector__XXX

BO_ 2365395198 AT1IGC2: 8 Vector__XXX
   SG_ Aftrtrtmnt1IntkGsNOxSnsrNH3Crrct : 24|8@1+ (0.5,0) [0|125] "%" Vector__XXX
   SG_ Aftrtrtmnt1IntkGsNOxSnsrNO2Crrct : 16|8@1+ (0.5,0) [0|125] "%" Vector__XXX
   SG_ Aftrtrtmnt1IntkGsNOxSnsrCrrctnOf : 8|8@1+ (0.5,0) [0|125] "%/bar" Vector__XXX
   SG_ Aftrtrtmnt1IntkGsNOxSnsrCrr_0000 : 0|8@1+ (0.5,0) [0|125] "%/bar" Vector__XXX

BO_ 2365395454 AT1IGC1: 8 Vector__XXX
   SG_ Aftrtrtmnt1IntkGsNOxSnsrNwPrtDvt : 32|8@1+ (1,-125) [-125|125] "ppm" Vector__XXX
   SG_ Aftrtrtmnt1IntkGsNOxSnsrNwP_0000 : 16|16@1+ (0.1,-100) [-100|100] "%" Vector__XXX
   SG_ Aftrtrtmnt1IntkGsNOxSnsrHtrRtio : 0|16@1+ (0.001,0) [0|64.255] "" Vector__XXX

BO_ 2157248254 AT1DPFSSC: 8 Vector__XXX
   SG_ Aftrtrtmnt1DslPrtcltFltrStStndrd : 16|16@1+ (0.0025,0) [0|160.637] "%" Vector__XXX
   SG_ Aftrtrtmnt1DslPrtcltFltrStMnClbO : 0|16@1+ (0.0025,0) [0|160.637] "%" Vector__XXX

BO_ 2566711806 ARMSWIMC: 8 Vector__XXX
   SG_ ArmrestSwitchMatrix2Switch2 : 6|2@1+ (1,0) [0|3] "" Vector__XXX
   SG_ ArmrestSwitchMatrix2Switch1 : 4|2@1+ (1,0) [0|3] "" Vector__XXX
   SG_ ArmrestSwitchMatrixSwitch2 : 2|2@1+ (1,0) [0|3] "" Vector__XXX
   SG_ ArmrestSwitchMatrixSwitch1 : 0|2@1+ (1,0) [0|3] "" Vector__XXX

BO_ 2364549886 ARI: 8 Vector__XXX
   SG_ AngularRateMeasurementLatency : 56|8@1+ (0.5,0) [0|125] "ms" Vector__XXX
   SG_ YawRateExRangeFigureOfMerit : 52|2@1+ (1,0) [0|3] "" Vector__XXX
   SG_ RollRateExRangeFigureOfMerit : 50|2@1+ (1,0) [0|3] "" Vector__XXX
   SG_ PitchRateExRangeFigureOfMerit : 48|2@1+ (1,0) [0|3] "" Vector__XXX
   SG_ YawRateExRange : 32|16@1+ (0.0078125,-250) [-250|250.992] "deg/sec" Vector__XXX
   SG_ RollRateExRange : 16|16@1+ (0.0078125,-250) [-250|250.992] "deg/sec" Vector__XXX
   SG_ PitchRateExRange : 0|16@1+ (0.0078125,-250) [-250|250.992] "deg/sec" Vector__XXX

BO_ 2566712318 AFT2NAI: 8 Vector__XXX
   SG_ Aftrtrtmnt2NOxAdsrbrDSOxRgnrtnSt : 2|2@1+ (1,0) [0|3] "" Vector__XXX
   SG_ Aftrtrtmnt2NOxAdsrbrDNOxRgnrtnSt : 0|2@1+ (1,0) [0|3] "" Vector__XXX

BO_ 2566712574 AFT1NAI: 8 Vector__XXX
   SG_ Aftrtrtmnt1NOxAdsrbrDSOxRgnrtnSt : 2|2@1+ (1,0) [0|3] "" Vector__XXX
   SG_ Aftrtrtmnt1NOxAdsrbrDNOxRgnrtnSt : 0|2@1+ (1,0) [0|3] "" Vector__XXX

BO_ 2164078590 A2SCRSI: 8 Vector__XXX
   SG_ Aftrtrtmnt2SCRCtlystCnvrsnEffcnc : 32|8@1+ (0.4,0) [0|100] "%" Vector__XXX
   SG_ Aftrtrtmnt2SCRCmddCtlystRgntCnsm : 16|16@1+ (0.05,0) [0|3212.75] "L/h" Vector__XXX
   SG_ Aftrtrtmnt2SCRAvrgCtlystRgntCnsm : 0|16@1+ (0.05,0) [0|3212.75] "L/h" Vector__XXX

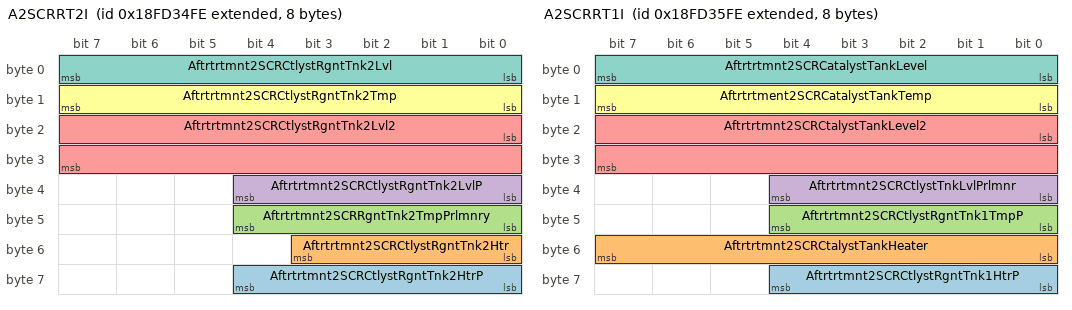
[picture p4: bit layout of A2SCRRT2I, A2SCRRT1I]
BO_ 2566731006 A2SCRRT2I: 8 Vector__XXX
   SG_ Aftrtrtmnt2SCRCtlystRgntTnk2HtrP : 56|5@1+ (1,0) [0|31] "" Vector__XXX
   SG_ Aftrtrtmnt2SCRCtlystRgntTnk2Htr : 48|4@1+ (1,0) [0|15] "" Vector__XXX
   SG_ Aftrtrtmnt2SCRRgntTnk2TmpPrlmnry : 40|5@1+ (1,0) [0|31] "" Vector__XXX
   SG_ Aftrtrtmnt2SCRCtlystRgntTnk2LvlP : 32|5@1+ (1,0) [0|31] "" Vector__XXX
   SG_ Aftrtrtmnt2SCRCtlystRgntTnk2Lvl2 : 16|16@1+ (0.1,0) [0|6425.5] "mm" Vector__XXX
   SG_ Aftrtrtmnt2SCRCtlystRgntTnk2Tmp : 8|8@1+ (1,-40) [-40|210] "deg C" Vector__XXX
   SG_ Aftrtrtmnt2SCRCtlystRgntTnk2Lvl : 0|8@1+ (0.4,0) [0|100] "%" Vector__XXX

BO_ 2566731262 A2SCRRT1I: 8 Vector__XXX
   SG_ Aftrtrtmnt2SCRCtlystRgntTnk1HtrP : 56|5@1+ (1,0) [0|31] "" Vector__XXX
   SG_ Aftrtrtmnt2SCRCtalystTankHeater : 48|8@1+ (0.4,0) [0|100] "%" Vector__XXX
   SG_ Aftrtrtmnt2SCRCtlystRgntTnk1TmpP : 40|5@1+ (1,0) [0|31] "" Vector__XXX
   SG_ Aftrtrtmnt2SCRCtlystTnkLvlPrlmnr : 32|5@1+ (1,0) [0|31] "" Vector__XXX
   SG_ Aftrtrtmnt2SCRCtalystTankLevel2 : 16|16@1+ (0.1,0) [0|6425.5] "mm" Vector__XXX
   SG_ Aftrtrtment2SCRCatalystTankTemp : 8|8@1+ (1,-40) [-40|210] "deg C" Vector__XXX
   SG_ Aftrtrtmnt2SCRCatalystTankLevel : 0|8@1+ (0.4,0) [0|100] "%" Vector__XXX

BO_ 2566730750 A2SCRRSI: 8 Vector__XXX
   SG_ Aftrtrtmnt2SCRCtlystRgntTnkDrnVl : 48|8@1+ (0.4,0) [0|100] "%" Vector__XXX
   SG_ Aftrtrtmnt2SCRCtlystRgntPmpStte : 40|2@1+ (1,0) [0|3] "" Vector__XXX
   SG_ Aftrtrtmnt2SCRCtlystRgntTnkFllVl : 32|8@1+ (0.4,0) [0|100] "%" Vector__XXX
   SG_ Aftrtrtmnt2SCRCtlystRgntRtrnVlv : 24|8@1+ (0.4,0) [0|100] "%" Vector__XXX
   SG_ Aftrtrtmnt2SCRCtlystRgntPmpDrvPr : 16|8@1+ (0.4,0) [0|100] "%" Vector__XXX
   SG_ Aftrtrtmnt2SCRCtlystRgntPmpMtrSp : 0|16@1+ (0.5,0) [0|32127.5] "rpm" Vector__XXX

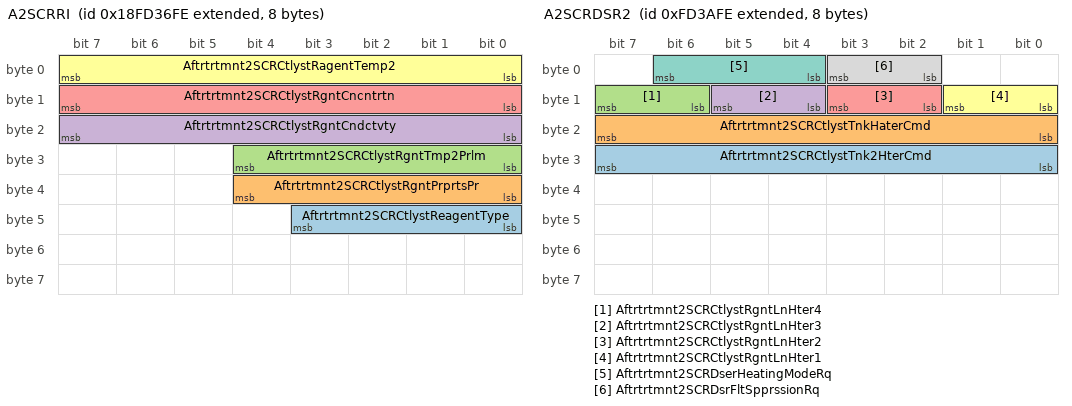
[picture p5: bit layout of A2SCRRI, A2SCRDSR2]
BO_ 2566731518 A2SCRRI: 8 Vector__XXX
   SG_ Aftrtrtmnt2SCRCtlystReagentType : 40|4@1+ (1,0) [0|15] "" Vector__XXX
   SG_ Aftrtrtmnt2SCRCtlystRgntPrprtsPr : 32|5@1+ (1,0) [0|31] "" Vector__XXX
   SG_ Aftrtrtmnt2SCRCtlystRgntTmp2Prlm : 24|5@1+ (1,0) [0|31] "" Vector__XXX
   SG_ Aftrtrtmnt2SCRCtlystRgntCndctvty : 16|8@1+ (5,0) [0|1250] "microSiemens/mm" Vector__XXX
   SG_ Aftrtrtmnt2SCRCtlystRgntCncntrtn : 8|8@1+ (0.25,0) [0|62.5] "%" Vector__XXX
   SG_ Aftrtrtmnt2SCRCtlystRagentTemp2 : 0|8@1+ (1,-40) [-40|210] "deg C" Vector__XXX

BO_ 2566732030 A2SCREGT: 8 Vector__XXX
   SG_ Aftrtrtmnt2SCRCtlystOtltGsTmpPrl : 40|5@1+ (1,0) [0|31] "" Vector__XXX
   SG_ Aftrtrtmnt2SCRCtlystOtltGasTemp : 24|16@1+ (0.03125,-273) [-273|1734.97] "deg C" Vector__XXX
   SG_ Aftrtrtmnt2SCRCtlystIntkGsTmpPrl : 16|5@1+ (1,0) [0|31] "" Vector__XXX
   SG_ Aftrtrtmnt2SCRCtlystIntkGasTemp : 0|16@1+ (0.03125,-273) [-273|1734.97] "deg C" Vector__XXX

BO_ 2566732286 A2SCREGP: 8 Vector__XXX
   SG_ Aftrtrtmnt2SCRCtlystExhstGsDffPr : 16|5@1+ (1,0) [0|31] "" Vector__XXX
   SG_ Aftrtrtmnt2SCRCtlystExhstGs_0000 : 0|16@1+ (0.1,0) [0|6425.5] "kPa" Vector__XXX

BO_ 2164079358 A2SCRDSR2: 8 Vector__XXX
   SG_ Aftrtrtmnt2SCRCtlystTnk2HterCmd : 24|8@1+ (0.4,0) [0|100] "%" Vector__XXX
   SG_ Aftrtrtmnt2SCRCtlystTnkHaterCmd : 16|8@1+ (0.4,0) [0|100] "%" Vector__XXX
   SG_ Aftrtrtmnt2SCRCtlystRgntLnHter4 : 14|2@1+ (1,0) [0|3] "" Vector__XXX
   SG_ Aftrtrtmnt2SCRCtlystRgntLnHter3 : 12|2@1+ (1,0) [0|3] "" Vector__XXX
   SG_ Aftrtrtmnt2SCRCtlystRgntLnHter2 : 10|2@1+ (1,0) [0|3] "" Vector__XXX
   SG_ Aftrtrtmnt2SCRCtlystRgntLnHter1 : 8|2@1+ (1,0) [0|3] "" Vector__XXX
   SG_ Aftrtrtmnt2SCRDserHeatingModeRq : 4|3@1+ (1,0) [0|7] "" Vector__XXX
   SG_ Aftrtrtmnt2SCRDsrFltSpprssionRq : 2|2@1+ (1,0) [0|3] "" Vector__XXX

BO_ 2364549118 A2SCRDSR1: 8 Vector__XXX
   SG_ Aftrtrtmnt2SCRRqdRgntQnttyFrIntg : 24|16@1+ (0.1,0) [0|6425.5] "g" Vector__XXX
   SG_ Aftrtratment2SCRSystemRqedState : 16|4@1+ (1,0) [0|15] "" Vector__XXX
   SG_ Aftrtrtmnt2SCRRqdDsngRgntQntity : 0|16@1+ (0.3,0) [0|19276.5] "g/h" Vector__XXX

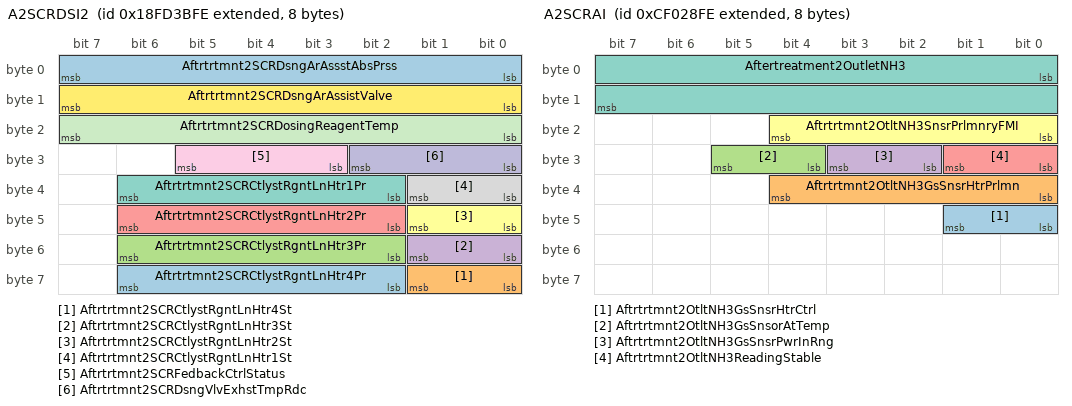
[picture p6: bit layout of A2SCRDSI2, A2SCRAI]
BO_ 2566732798 A2SCRDSI2: 8 Vector__XXX
   SG_ Aftrtrtmnt2SCRCtlystRgntLnHtr4Pr : 58|5@1+ (1,0) [0|31] "" Vector__XXX
   SG_ Aftrtrtmnt2SCRCtlystRgntLnHtr4St : 56|2@1+ (1,0) [0|3] "" Vector__XXX
   SG_ Aftrtrtmnt2SCRCtlystRgntLnHtr3Pr : 50|5@1+ (1,0) [0|31] "" Vector__XXX
   SG_ Aftrtrtmnt2SCRCtlystRgntLnHtr3St : 48|2@1+ (1,0) [0|3] "" Vector__XXX
   SG_ Aftrtrtmnt2SCRCtlystRgntLnHtr2Pr : 42|5@1+ (1,0) [0|31] "" Vector__XXX
   SG_ Aftrtrtmnt2SCRCtlystRgntLnHtr2St : 40|2@1+ (1,0) [0|3] "" Vector__XXX
   SG_ Aftrtrtmnt2SCRCtlystRgntLnHtr1Pr : 34|5@1+ (1,0) [0|31] "" Vector__XXX
   SG_ Aftrtrtmnt2SCRCtlystRgntLnHtr1St : 32|2@1+ (1,0) [0|3] "" Vector__XXX
   SG_ Aftrtrtmnt2SCRFedbackCtrlStatus : 27|3@1+ (1,0) [0|7] "" Vector__XXX
   SG_ Aftrtrtmnt2SCRDsngVlvExhstTmpRdc : 24|3@1+ (1,0) [0|7] "" Vector__XXX
   SG_ Aftrtrtmnt2SCRDosingReagentTemp : 16|8@1+ (1,-40) [-40|210] "deg C" Vector__XXX
   SG_ Aftrtrtmnt2SCRDsngArAssistValve : 8|8@1+ (0.4,0) [0|100] "%" Vector__XXX
   SG_ Aftrtrtmnt2SCRDsngArAssstAbsPrss : 0|8@1+ (8,0) [0|2000] "kPa" Vector__XXX

BO_ 2364548862 A2SCRDSI1: 8 Vector__XXX
   SG_ Aftrtrtmnt2SCRDsngRgentAbsPress : 40|8@1+ (8,0) [0|2000] "kPa" Vector__XXX
   SG_ Aftrtrtmnt2SCRActlRgntQnttyOfInt : 24|16@1+ (0.1,0) [0|6425.5] "g" Vector__XXX
   SG_ Aftertreatment2SCRSystemState : 16|4@1+ (1,0) [0|15] "" Vector__XXX
   SG_ Aftrtrtmnt2SCRActlDsngRgntQntty : 0|16@1+ (0.3,0) [0|19276.5] "g/h" Vector__XXX

BO_ 2364549374 A2SCRAI: 8 Vector__XXX
   SG_ Aftrtrtmnt2OtltNH3GsSnsrHtrCtrl : 40|2@1+ (1,0) [0|3] "" Vector__XXX
   SG_ Aftrtrtmnt2OtltNH3GsSnsrHtrPrlmn : 32|5@1+ (1,0) [0|31] "" Vector__XXX
   SG_ Aftrtrtmnt2OtltNH3GsSnsorAtTemp : 28|2@1+ (1,0) [0|3] "" Vector__XXX
   SG_ Aftrtrtmnt2OtltNH3GsSnsrPwrInRng : 26|2@1+ (1,0) [0|3] "" Vector__XXX
   SG_ Aftrtrtmnt2OtltNH3ReadingStable : 24|2@1+ (1,0) [0|3] "" Vector__XXX
   SG_ Aftrtrtmnt2OtltNH3SnsrPrlmnryFMI : 16|5@1+ (1,0) [0|31] "" Vector__XXX
   SG_ Aftertreatment2OutletNH3 : 0|16@1+ (0.3,0) [0|19276.5] "g/h" Vector__XXX

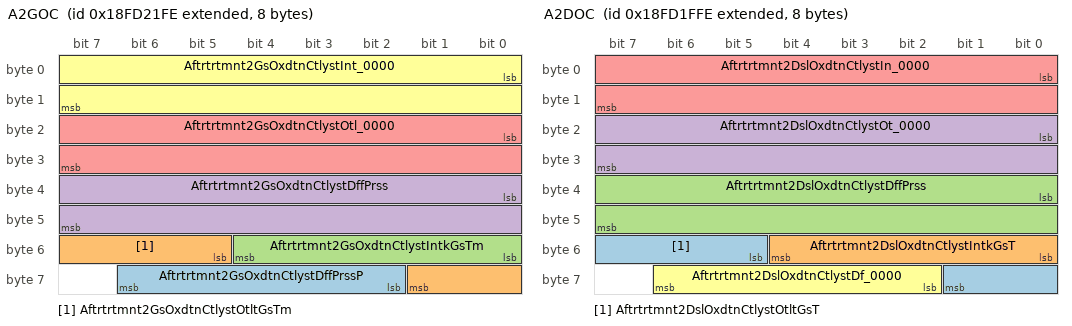
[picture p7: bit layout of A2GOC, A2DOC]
BO_ 2566726142 A2GOC: 8 Vector__XXX
   SG_ Aftrtrtmnt2GsOxdtnCtlystDffPrssP : 58|5@1+ (1,0) [0|31] "" Vector__XXX
   SG_ Aftrtrtmnt2GsOxdtnCtlystOtltGsTm : 53|5@1+ (1,0) [0|31] "" Vector__XXX
   SG_ Aftrtrtmnt2GsOxdtnCtlystIntkGsTm : 48|5@1+ (1,0) [0|31] "" Vector__XXX
   SG_ Aftrtrtmnt2GsOxdtnCtlystDffPrss : 32|16@1+ (0.1,0) [0|6425.5] "kPa" Vector__XXX
   SG_ Aftrtrtmnt2GsOxdtnCtlystOtl_0000 : 16|16@1+ (0.03125,-273) [-273|1734.97] "deg C" Vector__XXX
   SG_ Aftrtrtmnt2GsOxdtnCtlystInt_0000 : 0|16@1+ (0.03125,-273) [-273|1734.97] "deg C" Vector__XXX

BO_ 2566725630 A2DOC: 8 Vector__XXX
   SG_ Aftrtrtmnt2DslOxdtnCtlystOtltGsT : 53|5@1+ (1,0) [0|31] "" Vector__XXX
   SG_ Aftrtrtmnt2DslOxdtnCtlystIntkGsT : 48|5@1+ (1,0) [0|31] "" Vector__XXX
   SG_ Aftrtrtmnt2DslOxdtnCtlystDffPrss : 32|16@1+ (0.5,0) [0|32127.5] "kPa" Vector__XXX
   SG_ Aftrtrtmnt2DslOxdtnCtlystOt_0000 : 16|16@1+ (0.03125,-273) [-273|1734.97] "deg C" Vector__XXX
   SG_ Aftrtrtmnt2DslOxdtnCtlystIn_0000 : 0|16@1+ (0.03125,-273) [-273|1734.97] "deg C" Vector__XXX
   SG_ Aftrtrtmnt2DslOxdtnCtlystDf_0000 : 58|5@1+ (1,0) [0|31] "" Vector__XXX

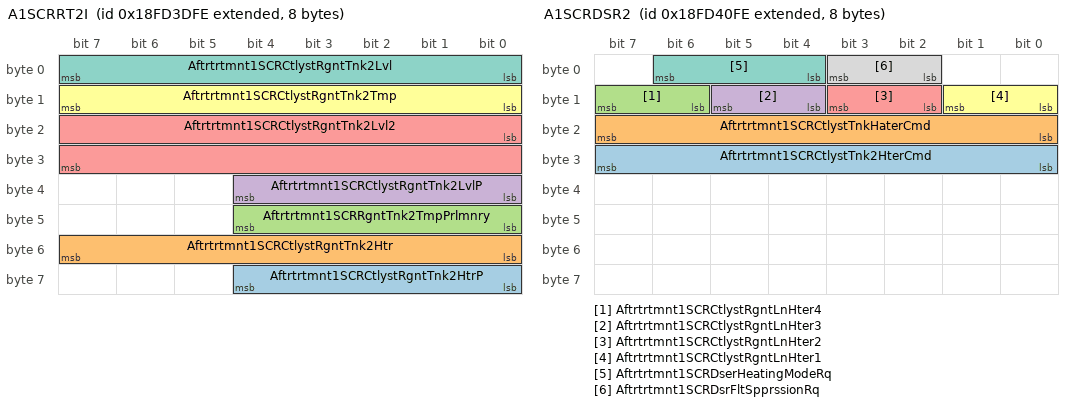
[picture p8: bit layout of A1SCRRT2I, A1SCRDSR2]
BO_ 2566733310 A1SCRRT2I: 8 Vector__XXX
   SG_ Aftrtrtmnt1SCRCtlystRgntTnk2HtrP : 56|5@1+ (1,0) [0|31] "" Vector__XXX
   SG_ Aftrtrtmnt1SCRCtlystRgntTnk2Htr : 48|8@1+ (0.4,0) [0|100] "%" Vector__XXX
   SG_ Aftrtrtmnt1SCRRgntTnk2TmpPrlmnry : 40|5@1+ (1,0) [0|31] "" Vector__XXX
   SG_ Aftrtrtmnt1SCRCtlystRgntTnk2LvlP : 32|5@1+ (1,0) [0|31] "" Vector__XXX
   SG_ Aftrtrtmnt1SCRCtlystRgntTnk2Lvl2 : 16|16@1+ (0.1,0) [0|6425.5] "mm" Vector__XXX
   SG_ Aftrtrtmnt1SCRCtlystRgntTnk2Tmp : 8|8@1+ (1,-40) [-40|210] "deg C" Vector__XXX
   SG_ Aftrtrtmnt1SCRCtlystRgntTnk2Lvl : 0|8@1+ (0.4,0) [0|100] "%" Vector__XXX

BO_ 2566733054 A1SCRRSI: 8 Vector__XXX
   SG_ Aftrtrtmnt1SCRCtlystRgntTnkDrnVl : 48|8@1+ (0.4,0) [0|100] "%" Vector__XXX
   SG_ Aftrtrtmnt1SCRCtlystRgntPmpStte : 40|2@1+ (1,0) [0|3] "" Vector__XXX
   SG_ Aftrtrtmnt1SCRCtlystRgntTnkFllVl : 32|8@1+ (0.4,0) [0|100] "%" Vector__XXX
   SG_ Aftrtrtmnt1SCRCtlystRgntRtrnVlv : 24|8@1+ (0.4,0) [0|100] "%" Vector__XXX
   SG_ Aftrtrtmnt1SCRCtlystRgntPmpDrvPr : 16|8@1+ (0.4,0) [0|100] "%" Vector__XXX
   SG_ Aftrtrtmnt1SCRCtlystRgntPmpMtrSp : 0|16@1+ (0.5,0) [0|32127.5] "rpm" Vector__XXX

BO_ 2499624702 A1SCREGT: 8 Vector__XXX
   SG_ Aftrtrtmnt1SCRCtlystOtltGsTmpPrl : 40|5@1+ (1,0) [0|31] "" Vector__XXX
   SG_ Aftrtrtmnt1SCRCtlystOtltGasTemp : 24|16@1+ (0.03125,-273) [-273|1734.97] "deg C" Vector__XXX
   SG_ Aftrtrtmnt1SCRCtlystIntkGsTmpPrl : 16|5@1+ (1,0) [0|31] "" Vector__XXX
   SG_ Aftrtrtmnt1SCRCtlystIntkGasTemp : 0|16@1+ (0.03125,-273) [-273|1734.97] "deg C" Vector__XXX

BO_ 2566733822 A1SCREGP: 8 Vector__XXX
   SG_ Aftrtrtmnt1SCRCtlystExhstGsDffPr : 16|5@1+ (1,0) [0|31] "" Vector__XXX
   SG_ Aftrtrtmnt1SCRCtlystExhstGs_0000 : 0|16@1+ (0.1,0) [0|6425.5] "kPa" Vector__XXX

BO_ 2566734078 A1SCRDSR2: 8 Vector__XXX
   SG_ Aftrtrtmnt1SCRCtlystTnk2HterCmd : 24|8@1+ (0.4,0) [0|100] "%" Vector__XXX
   SG_ Aftrtrtmnt1SCRCtlystTnkHaterCmd : 16|8@1+ (0.4,0) [0|100] "%" Vector__XXX
   SG_ Aftrtrtmnt1SCRCtlystRgntLnHter4 : 14|2@1+ (1,0) [0|3] "" Vector__XXX
   SG_ Aftrtrtmnt1SCRCtlystRgntLnHter3 : 12|2@1+ (1,0) [0|3] "" Vector__XXX
   SG_ Aftrtrtmnt1SCRCtlystRgntLnHter2 : 10|2@1+ (1,0) [0|3] "" Vector__XXX
   SG_ Aftrtrtmnt1SCRCtlystRgntLnHter1 : 8|2@1+ (1,0) [0|3] "" Vector__XXX
   SG_ Aftrtrtmnt1SCRDserHeatingModeRq : 4|3@1+ (1,0) [0|7] "" Vector__XXX
   SG_ Aftrtrtmnt1SCRDsrFltSpprssionRq : 2|2@1+ (1,0) [0|3] "" Vector__XXX

BO_ 2364548350 A1SCRDSR1: 8 Vector__XXX
   SG_ Aftrtrtmnt1SCRRqdRgntQnttyFrIntg : 24|16@1+ (0.1,0) [0|6425.5] "g" Vector__XXX
   SG_ Aftrtratment1SCRSystemRqedState : 16|4@1+ (1,0) [0|15] "" Vector__XXX
   SG_ Aftrtrtmnt1SCRRqdDsngRgntQntity : 0|16@1+ (0.3,0) [0|19276.5] "g/h" Vector__XXX

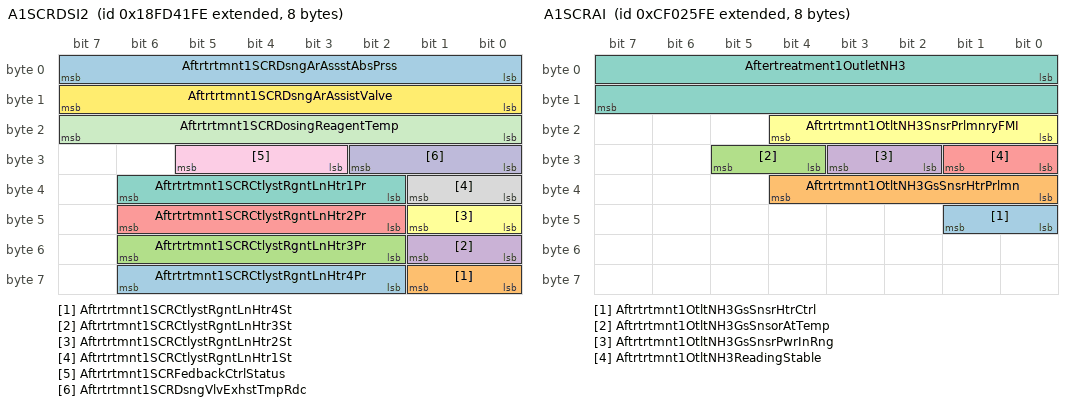
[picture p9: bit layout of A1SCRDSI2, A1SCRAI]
BO_ 2566734334 A1SCRDSI2: 8 Vector__XXX
   SG_ Aftrtrtmnt1SCRCtlystRgntLnHtr4Pr : 58|5@1+ (1,0) [0|31] "" Vector__XXX
   SG_ Aftrtrtmnt1SCRCtlystRgntLnHtr4St : 56|2@1+ (1,0) [0|3] "" Vector__XXX
   SG_ Aftrtrtmnt1SCRCtlystRgntLnHtr3Pr : 50|5@1+ (1,0) [0|31] "" Vector__XXX
   SG_ Aftrtrtmnt1SCRCtlystRgntLnHtr3St : 48|2@1+ (1,0) [0|3] "" Vector__XXX
   SG_ Aftrtrtmnt1SCRCtlystRgntLnHtr2Pr : 42|5@1+ (1,0) [0|31] "" Vector__XXX
   SG_ Aftrtrtmnt1SCRCtlystRgntLnHtr2St : 40|2@1+ (1,0) [0|3] "" Vector__XXX
   SG_ Aftrtrtmnt1SCRCtlystRgntLnHtr1Pr : 34|5@1+ (1,0) [0|31] "" Vector__XXX
   SG_ Aftrtrtmnt1SCRCtlystRgntLnHtr1St : 32|2@1+ (1,0) [0|3] "" Vector__XXX
   SG_ Aftrtrtmnt1SCRFedbackCtrlStatus : 27|3@1+ (1,0) [0|7] "" Vector__XXX
   SG_ Aftrtrtmnt1SCRDsngVlvExhstTmpRdc : 24|3@1+ (1,0) [0|7] "" Vector__XXX
   SG_ Aftrtrtmnt1SCRDosingReagentTemp : 16|8@1+ (1,-40) [-40|210] "deg C" Vector__XXX
   SG_ Aftrtrtmnt1SCRDsngArAssistValve : 8|8@1+ (0.4,0) [0|100] "%" Vector__XXX
   SG_ Aftrtrtmnt1SCRDsngArAssstAbsPrss : 0|8@1+ (8,0) [0|2000] "kPa" Vector__XXX

BO_ 2364548094 A1SCRDSI1: 8 Vector__XXX
   SG_ Aftrtrtmnt1SCRDsngRgentAbsPress : 40|8@1+ (8,0) [0|2000] "kPa" Vector__XXX
   SG_ Aftrtrtmnt1SCRActlRgntQnttyOfInt : 24|16@1+ (0.1,0) [0|6425.5] "g" Vector__XXX
   SG_ Aftertreatment1SCRSystemState : 16|4@1+ (1,0) [0|15] "" Vector__XXX
   SG_ Aftrtrtmnt1SCRActlDsngRgntQntty : 0|16@1+ (0.3,0) [0|19276.5] "g/h" Vector__XXX

BO_ 2364548606 A1SCRAI: 8 Vector__XXX
   SG_ Aftrtrtmnt1OtltNH3GsSnsrHtrCtrl : 40|2@1+ (1,0) [0|3] "" Vector__XXX
   SG_ Aftrtrtmnt1OtltNH3GsSnsrHtrPrlmn : 32|5@1+ (1,0) [0|31] "" Vector__XXX
   SG_ Aftrtrtmnt1OtltNH3GsSnsorAtTemp : 28|2@1+ (1,0) [0|3] "" Vector__XXX
   SG_ Aftrtrtmnt1OtltNH3GsSnsrPwrInRng : 26|2@1+ (1,0) [0|3] "" Vector__XXX
   SG_ Aftrtrtmnt1OtltNH3ReadingStable : 24|2@1+ (1,0) [0|3] "" Vector__XXX
   SG_ Aftrtrtmnt1OtltNH3SnsrPrlmnryFMI : 16|5@1+ (1,0) [0|31] "" Vector__XXX
   SG_ Aftertreatment1OutletNH3 : 0|16@1+ (0.3,0) [0|19276.5] "g/h" Vector__XXX

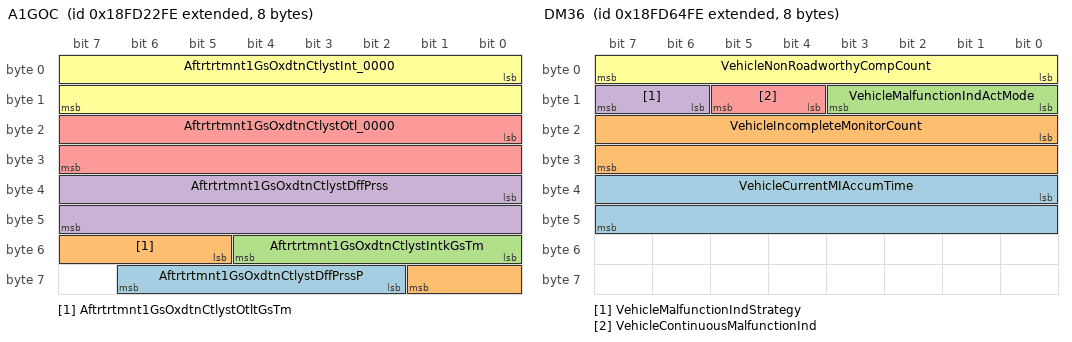
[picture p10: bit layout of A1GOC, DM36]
BO_ 2566726398 A1GOC: 8 Vector__XXX
   SG_ Aftrtrtmnt1GsOxdtnCtlystDffPrssP : 58|5@1+ (1,0) [0|31] "" Vector__XXX
   SG_ Aftrtrtmnt1GsOxdtnCtlystOtltGsTm : 53|5@1+ (1,0) [0|31] "" Vector__XXX
   SG_ Aftrtrtmnt1GsOxdtnCtlystIntkGsTm : 48|5@1+ (1,0) [0|31] "" Vector__XXX
   SG_ Aftrtrtmnt1GsOxdtnCtlystDffPrss : 32|16@1+ (0.1,0) [0|6425.5] "kPa" Vector__XXX
   SG_ Aftrtrtmnt1GsOxdtnCtlystOtl_0000 : 16|16@1+ (0.03125,-273) [-273|1734.97] "deg C" Vector__XXX
   SG_ Aftrtrtmnt1GsOxdtnCtlystInt_0000 : 0|16@1+ (0.03125,-273) [-273|1734.97] "deg C" Vector__XXX

BO_ 2566742270 DM40: 8 Vector__XXX
   SG_ FailureSpecificB1Counter : 24|16@1+ (0.1,0) [0|6425.5] "hr" Vector__XXX
   SG_ FailureModeIdentifier1 : 16|5@1+ (1,0) [0|0] "" Vector__XXX
   SG_ SPN1High : 21|3@1+ (1,0) [0|7] "" Vector__XXX
   SG_ SPN1 : 0|16@1+ (1,0) [0|65536] "" Vector__XXX

BO_ 2566742526 DM39: 8 Vector__XXX
   SG_ SysGreatestB1Counter : 32|16@1+ (0.1,0) [0|6425.5] "hr" Vector__XXX
   SG_ SysCumulativeContinuousMITime : 0|32@1+ (0.05,0) [0|2.10554e+08] "hr" Vector__XXX

BO_ 2566742782 DM38: 8 Vector__XXX
   SG_ RegulationDescription : 0|8@1+ (1,0) [0|255] "" Vector__XXX

BO_ 2566743038 DM37: 8 Vector__XXX
   SG_ SysIncompleteMonitorCount : 16|16@1+ (1,0) [0|64512] "" Vector__XXX
   SG_ SysMalIndActivationMode : 8|4@1+ (1,0) [0|15] "" Vector__XXX
   SG_ SysMalIndDisplayStrategy : 12|2@1+ (1,0) [0|3] "" Vector__XXX
   SG_ SysContinuousMalfunctionInd : 14|2@1+ (1,0) [0|3] "" Vector__XXX
   SG_ SysNonRoadworthyCompCount : 0|8@1+ (1,0) [0|250] "" Vector__XXX

BO_ 2566743294 DM36: 8 Vector__XXX
   SG_ VehicleCurrentMIAccumTime : 32|16@1+ (1,0) [0|64255] "min" Vector__XXX
   SG_ VehicleIncompleteMonitorCount : 16|16@1+ (1,0) [0|64255] "" Vector__XXX
   SG_ VehicleMalfunctionIndActMode : 8|4@1+ (1,0) [0|15] "" Vector__XXX
   SG_ VehicleMalfunctionIndStrategy : 14|2@1+ (1,0) [0|3] "" Vector__XXX
   SG_ VehicleContinuousMalfunctionInd : 12|2@1+ (1,0) [0|3] "" Vector__XXX
   SG_ VehicleNonRoadworthyCompCount : 0|8@1+ (1,0) [0|250] "" Vector__XXX

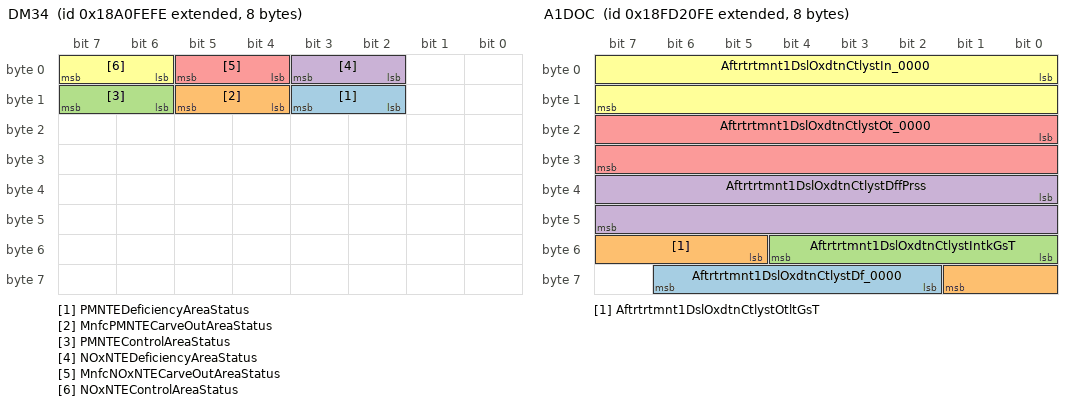
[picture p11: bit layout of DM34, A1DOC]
BO_ 2560687870 DM34: 8 Vector__XXX
   SG_ PMNTEDeficiencyAreaStatus : 10|2@1+ (1,0) [0|3] "" Vector__XXX
   SG_ MnfcPMNTECarveOutAreaStatus : 12|2@1+ (1,0) [0|3] "" Vector__XXX
   SG_ PMNTEControlAreaStatus : 14|2@1+ (1,0) [0|3] "" Vector__XXX
   SG_ NOxNTEDeficiencyAreaStatus : 2|2@1+ (1,0) [0|3] "" Vector__XXX
   SG_ MnfcNOxNTECarveOutAreaStatus : 4|2@1+ (1,0) [0|3] "" Vector__XXX
   SG_ NOxNTEControlAreaStatus : 6|2@1+ (1,0) [0|3] "" Vector__XXX

BO_ 2292317950 DM33: 9 Vector__XXX
   SG_ AECDEngineHours1Timer2 : 40|32@1+ (1,0) [0|4.29497e+09] "min" Vector__XXX
   SG_ AECDEngineHours1Timer1 : 8|32@1+ (1,0) [0|4.29497e+09] "min" Vector__XXX
   SG_ AECDNumber1 : 0|8@1+ (1,0) [0|250] "" Vector__XXX

BO_ 2566809342 BM: 8 Vector__XXX
   SG_ BatteryMainSwitchHoldState : 0|2@1+ (1,0) [0|3] "" Vector__XXX

BO_ 2365446910 BJM3: 8 Vector__XXX
   SG_ Joystick3XAxisDetentPosStatus : 38|2@1+ (1,0) [0|3] "" Vector__XXX
   SG_ Joystick3Button9PressedStatus : 62|2@1+ (1,0) [0|3] "" Vector__XXX
   SG_ Joystick3Button10PressedStatus : 60|2@1+ (1,0) [0|3] "" Vector__XXX
   SG_ Joystick3Button11PressedStatus : 58|2@1+ (1,0) [0|3] "" Vector__XXX
   SG_ Joystick3Button12PressedStatus : 56|2@1+ (1,0) [0|3] "" Vector__XXX
   SG_ Joystick3YAxisDetentPosStatus : 36|2@1+ (1,0) [0|3] "" Vector__XXX
   SG_ Joystick3YAxisPos : 22|10@1+ (0.1,0) [0|102] "%" Vector__XXX
   SG_ Jystck3YAxsLvrFrwrdPstvPsStatus : 20|2@1+ (1,0) [0|3] "" Vector__XXX
   SG_ Jystck3YAxsLvrBckNgtvePosStatus : 18|2@1+ (1,0) [0|3] "" Vector__XXX
   SG_ Joystick3YAxisNeutralPosStatus : 16|2@1+ (1,0) [0|3] "" Vector__XXX
   SG_ Joystick3XAxisPos : 6|10@1+ (0.1,0) [0|102] "%" Vector__XXX
   SG_ Jystck3XAxsLvrRghtPstvPosStatus : 4|2@1+ (1,0) [0|3] "" Vector__XXX
   SG_ Jystck3XAxsLvrLftNgtvePosStatus : 2|2@1+ (1,0) [0|3] "" Vector__XXX
   SG_ Joystick3XAxisNeutralPosStatus : 0|2@1+ (1,0) [0|3] "" Vector__XXX
   SG_ Joystick3Button5PressedStatus : 54|2@1+ (1,0) [0|3] "" Vector__XXX
   SG_ Joystick3Button6PressedStatus : 52|2@1+ (1,0) [0|3] "" Vector__XXX
   SG_ Joystick3Button7PressedStatus : 50|2@1+ (1,0) [0|3] "" Vector__XXX
   SG_ Joystick3Button8PressedStatus : 48|2@1+ (1,0) [0|3] "" Vector__XXX
   SG_ Joystick3Button1PressedStatus : 46|2@1+ (1,0) [0|3] "" Vector__XXX
   SG_ Joystick3Button2PressedStatus : 44|2@1+ (1,0) [0|3] "" Vector__XXX
   SG_ Joystick3Button3PressedStatus : 42|2@1+ (1,0) [0|3] "" Vector__XXX
   SG_ Joystick3Button4PressedStatus : 40|2@1+ (1,0) [0|3] "" Vector__XXX

BO_ 2365446398 BJM2: 8 Vector__XXX
   SG_ Joystick2XAxisDetentPosStatus : 38|2@1+ (1,0) [0|3] "" Vector__XXX
   SG_ Joystick2YAxisDetentPosStatus : 36|2@1+ (1,0) [0|3] "" Vector__XXX
   SG_ Joystick2YAxisPos : 22|10@1+ (0.1,0) [0|102] "%" Vector__XXX
   SG_ Jystck2YAxsLvrFrwrdPstvPsStatus : 20|2@1+ (1,0) [0|3] "" Vector__XXX
   SG_ Jystck2YAxsLvrBckNgtvePosStatus : 18|2@1+ (1,0) [0|3] "" Vector__XXX
   SG_ Joystick2YAxisNeutralPosStatus : 16|2@1+ (1,0) [0|3] "" Vector__XXX
   SG_ Joystick2XAxisPos : 6|10@1+ (0.1,0) [0|102] "%" Vector__XXX
   SG_ Jystck2XAxsLvrRghtPstvPosStatus : 4|2@1+ (1,0) [0|3] "" Vector__XXX
   SG_ Jystck2XAxsLvrLftNgtvePosStatus : 2|2@1+ (1,0) [0|3] "" Vector__XXX
   SG_ Joystick2XAxisNeutralPosStatus : 0|2@1+ (1,0) [0|3] "" Vector__XXX
   SG_ Joystick2Button9PressedStatus : 62|2@1+ (1,0) [0|3] "" Vector__XXX
   SG_ Joystick2Button10PressedStatus : 60|2@1+ (1,0) [0|3] "" Vector__XXX
   SG_ Joystick2Button11PressedStatus : 58|2@1+ (1,0) [0|3] "" Vector__XXX
   SG_ Joystick2Button12PressedStatus : 56|2@1+ (1,0) [0|3] "" Vector__XXX
   SG_ Joystick2Button5PressedStatus : 54|2@1+ (1,0) [0|3] "" Vector__XXX
   SG_ Joystick2Button6PressedStatus : 52|2@1+ (1,0) [0|3] "" Vector__XXX
   SG_ Joystick2Button7PressedStatus : 50|2@1+ (1,0) [0|3] "" Vector__XXX
   SG_ Joystick2Button8PressedStatus : 48|2@1+ (1,0) [0|3] "" Vector__XXX
   SG_ Joystick2Button1PressedStatus : 46|2@1+ (1,0) [0|3] "" Vector__XXX
   SG_ Joystick2Button2PressedStatus : 44|2@1+ (1,0) [0|3] "" Vector__XXX
   SG_ Joystick2Button3PressedStatus : 42|2@1+ (1,0) [0|3] "" Vector__XXX
   SG_ Joystick2Button4PressedStatus : 40|2@1+ (1,0) [0|3] "" Vector__XXX

BO_ 2365445886 BJM1: 8 Vector__XXX
   SG_ Joystick1XAxisDetentPosStatus : 38|2@1+ (1,0) [0|3] "" Vector__XXX
   SG_ Joystick1YAxisDetentPosStatus : 36|2@1+ (1,0) [0|3] "" Vector__XXX
   SG_ Joystick1YAxisPos : 22|10@1+ (0.1,0) [0|102] "%" Vector__XXX
   SG_ Jystck1YAxsLvrFrwrdPstvPsStatus : 20|2@1+ (1,0) [0|3] "" Vector__XXX
   SG_ Jystck1YAxsLvrBckNgtvePosStatus : 18|2@1+ (1,0) [0|3] "" Vector__XXX
   SG_ Joystick1YAxisNeutralPosStatus : 16|2@1+ (1,0) [0|3] "" Vector__XXX
   SG_ Joystick1XAxisPos : 6|10@1+ (0.1,0) [0|102] "%" Vector__XXX
   SG_ Joystick1Button9PressedStatus : 62|2@1+ (1,0) [0|3] "" Vector__XXX
   SG_ Joystick1Button10PressedStatus : 60|2@1+ (1,0) [0|3] "" Vector__XXX
   SG_ Joystick1Button11PressedStatus : 58|2@1+ (1,0) [0|3] "" Vector__XXX
   SG_ Joystick1Button12PressedStatus : 56|2@1+ (1,0) [0|3] "" Vector__XXX
   SG_ Joystick1Button5PressedStatus : 54|2@1+ (1,0) [0|3] "" Vector__XXX
   SG_ Joystick1Button6PressedStatus : 52|2@1+ (1,0) [0|3] "" Vector__XXX
   SG_ Joystick1Button7PressedStatus : 50|2@1+ (1,0) [0|3] "" Vector__XXX
   SG_ Joystick1Button8PressedStatus : 48|2@1+ (1,0) [0|3] "" Vector__XXX
   SG_ Joystick1Button1PressedStatus : 46|2@1+ (1,0) [0|3] "" Vector__XXX
   SG_ Joystick1Button2PressedStatus : 44|2@1+ (1,0) [0|3] "" Vector__XXX
   SG_ Joystick1Button3PressedStatus : 42|2@1+ (1,0) [0|3] "" Vector__XXX
   SG_ Joystick1Button4PressedStatus : 40|2@1+ (1,0) [0|3] "" Vector__XXX
   SG_ Jystck1XAxsLvrRghtPstvPosStatus : 4|2@1+ (1,0) [0|3] "" Vector__XXX
   SG_ Jystck1XAxsLvrLftNgtvePosStatus : 2|2@1+ (1,0) [0|3] "" Vector__XXX
   SG_ Joystick1XAxisNeutralPosStatus : 0|2@1+ (1,0) [0|3] "" Vector__XXX

BO_ 2566847230 B: 8 Vector__XXX
   SG_ ParkingBrakeRedWarningSignal : 26|2@1+ (1,0) [0|3] "" Vector__XXX
   SG_ ParkBrakeReleaseInhibitStatus : 28|2@1+ (1,0) [0|3] "" Vector__XXX
   SG_ ParkingBrakeActuator : 24|2@1+ (1,0) [0|3] "" Vector__XXX
   SG_ BrakeSecondPress : 16|8@1+ (4,0) [0|1000] "kPa" Vector__XXX
   SG_ BrakePrimaryPress : 8|8@1+ (4,0) [0|1000] "kPa" Vector__XXX
   SG_ BrakeAppPress : 0|8@1+ (4,0) [0|1000] "kPa" Vector__XXX

BO_ 2566848254 AWPP: 8 Vector__XXX
   SG_ AuxPumpPress : 0|8@1+ (16,0) [0|4000] "kPa" Vector__XXX

BO_ 2566725886 A1DOC: 8 Vector__XXX
   SG_ Aftrtrtmnt1DslOxdtnCtlystDf_0000 : 58|5@1+ (1,0) [0|31] "" Vector__XXX
   SG_ Aftrtrtmnt1DslOxdtnCtlystOtltGsT : 53|5@1+ (1,0) [0|31] "" Vector__XXX
   SG_ Aftrtrtmnt1DslOxdtnCtlystIntkGsT : 48|5@1+ (1,0) [0|31] "" Vector__XXX
   SG_ Aftrtrtmnt1DslOxdtnCtlystDffPrss : 32|16@1+ (0.1,0) [0|6425.5] "kPa" Vector__XXX
   SG_ Aftrtrtmnt1DslOxdtnCtlystOt_0000 : 16|16@1+ (0.03125,-273) [-273|1734.97] "deg C" Vector__XXX
   SG_ Aftrtrtmnt1DslOxdtnCtlystIn_0000 : 0|16@1+ (0.03125,-273) [-273|1734.97] "deg C" Vector__XXX

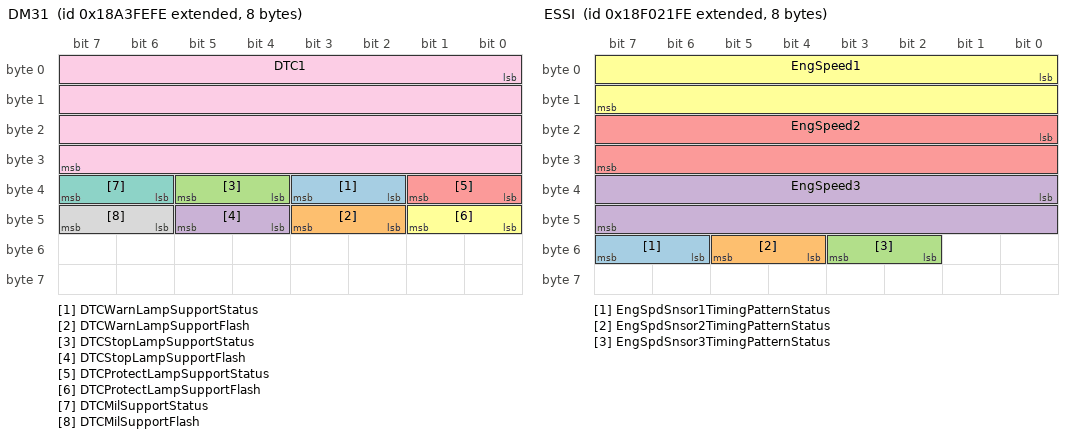
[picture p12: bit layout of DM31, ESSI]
BO_ 2560884478 DM31: 8 Vector__XXX
   SG_ DTCWarnLampSupportStatus : 34|2@1+ (1,0) [0|3] "" Vector__XXX
   SG_ DTCWarnLampSupportFlash : 42|2@1+ (1,0) [0|3] "" Vector__XXX
   SG_ DTCStopLampSupportStatus : 36|2@1+ (1,0) [0|3] "" Vector__XXX
   SG_ DTCStopLampSupportFlash : 44|2@1+ (1,0) [0|3] "" Vector__XXX
   SG_ DTCProtectLampSupportStatus : 32|2@1+ (1,0) [0|3] "" Vector__XXX
   SG_ DTCProtectLampSupportFlash : 40|2@1+ (1,0) [0|3] "" Vector__XXX
   SG_ DTCMilSupportStatus : 38|2@1+ (1,0) [0|3] "" Vector__XXX
   SG_ DTCMilSupportFlash : 46|2@1+ (1,0) [0|3] "" Vector__XXX
   SG_ DTC1 : 0|32@1+ (1,0) [0|4.29497e+09] "" Vector__XXX

BO_ 2633844734 TML: 8 Vector__XXX

BO_ 2560360190 PMI: 8 Vector__XXX
   SG_ DataDictionaryMethod : 11|21@1+ (1,0) [0|2.09715e+06] "" Vector__XXX
   SG_ DataDictionaryManufacturerCode : 0|11@1+ (1,0) [0|2047] "" Vector__XXX

BO_ 2566736126 O2FT2: 8 Vector__XXX
   SG_ ShorttermFuelTrimBank2 : 16|16@1+ (0.1,-100) [-100|100] "%" Vector__XXX
   SG_ LongtermFuelTrimBank2 : 0|16@1+ (0.1,-100) [-100|100] "%" Vector__XXX
   SG_ EngExhstGsOxygnSnsrClsdLpOprtnBn : 32|4@1+ (1,0) [0|15] "" Vector__XXX

BO_ 2566736382 O2FT1: 8 Vector__XXX
   SG_ ShorttermFuelTrimBank1 : 16|16@1+ (0.1,-100) [-100|100] "%" Vector__XXX
   SG_ LongtermFuelTrimBank1 : 0|16@1+ (0.1,-100) [-100|100] "%" Vector__XXX
   SG_ EngExhstGsOxygnSnsrClsdLpOp_0000 : 32|4@1+ (1,0) [0|15] "" Vector__XXX

BO_ 2565874174 ESSI: 8 Vector__XXX
   SG_ EngSpdSnsor1TimingPatternStatus : 54|2@1+ (1,0) [0|3] "" Vector__XXX
   SG_ EngSpdSnsor2TimingPatternStatus : 52|2@1+ (1,0) [0|3] "" Vector__XXX
   SG_ EngSpdSnsor3TimingPatternStatus : 50|2@1+ (1,0) [0|3] "" Vector__XXX
   SG_ EngSpeed3 : 32|16@1+ (0.5,0) [0|32127.5] "rpm" Vector__XXX
   SG_ EngSpeed2 : 16|16@1+ (0.5,0) [0|32127.5] "rpm" Vector__XXX
   SG_ EngSpeed1 : 0|16@1+ (0.5,0) [0|32127.5] "rpm" Vector__XXX

BO_ 2432520958 ECCVC: 8 Vector__XXX
   SG_ DsrdEngCoolantThermostatOpening : 16|8@1+ (0.4,0) [0|100] "%" Vector__XXX
   SG_ DesiredEngCoolantPumpOutletTemp : 8|8@1+ (1,-40) [-40|210] "deg C" Vector__XXX
   SG_ EngCoolantThermostatMode : 0|2@1+ (1,0) [0|3] "" Vector__XXX

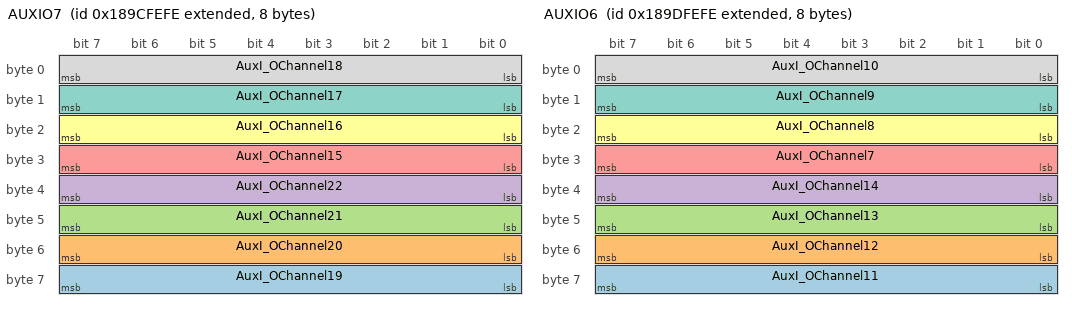
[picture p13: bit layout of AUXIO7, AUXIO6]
BO_ 2560425726 AUXIO7: 8 Vector__XXX
   SG_ AuxI_OChannel19 : 56|8@1+ (1,0) [0|250] "" Vector__XXX
   SG_ AuxI_OChannel20 : 48|8@1+ (1,0) [0|250] "" Vector__XXX
   SG_ AuxI_OChannel21 : 40|8@1+ (1,0) [0|250] "" Vector__XXX
   SG_ AuxI_OChannel22 : 32|8@1+ (1,0) [0|250] "" Vector__XXX
   SG_ AuxI_OChannel15 : 24|8@1+ (1,0) [0|250] "" Vector__XXX
   SG_ AuxI_OChannel16 : 16|8@1+ (1,0) [0|250] "" Vector__XXX
   SG_ AuxI_OChannel17 : 8|8@1+ (1,0) [0|250] "" Vector__XXX
   SG_ AuxI_OChannel18 : 0|8@1+ (1,0) [0|250] "" Vector__XXX

BO_ 2560491262 AUXIO6: 8 Vector__XXX
   SG_ AuxI_OChannel11 : 56|8@1+ (1,0) [0|250] "" Vector__XXX
   SG_ AuxI_OChannel12 : 48|8@1+ (1,0) [0|250] "" Vector__XXX
   SG_ AuxI_OChannel13 : 40|8@1+ (1,0) [0|250] "" Vector__XXX
   SG_ AuxI_OChannel14 : 32|8@1+ (1,0) [0|250] "" Vector__XXX
   SG_ AuxI_OChannel7 : 24|8@1+ (1,0) [0|250] "" Vector__XXX
   SG_ AuxI_OChannel8 : 16|8@1+ (1,0) [0|250] "" Vector__XXX
   SG_ AuxI_OChannel9 : 8|8@1+ (1,0) [0|250] "" Vector__XXX
   SG_ AuxI_OChannel10 : 0|8@1+ (1,0) [0|250] "" Vector__XXX

BO_ 2349399806 AUXIO5: 8 Vector__XXX
   SG_ AuxI_OChannel3 : 48|16@1+ (1,0) [0|64255] "counts" Vector__XXX
   SG_ AuxI_OChannel4 : 32|16@1+ (1,0) [0|64255] "counts" Vector__XXX
   SG_ AuxI_OChannel5 : 16|16@1+ (1,0) [0|64255] "counts" Vector__XXX
   SG_ AuxI_OChannel6 : 0|16@1+ (1,0) [0|64255] "counts" Vector__XXX

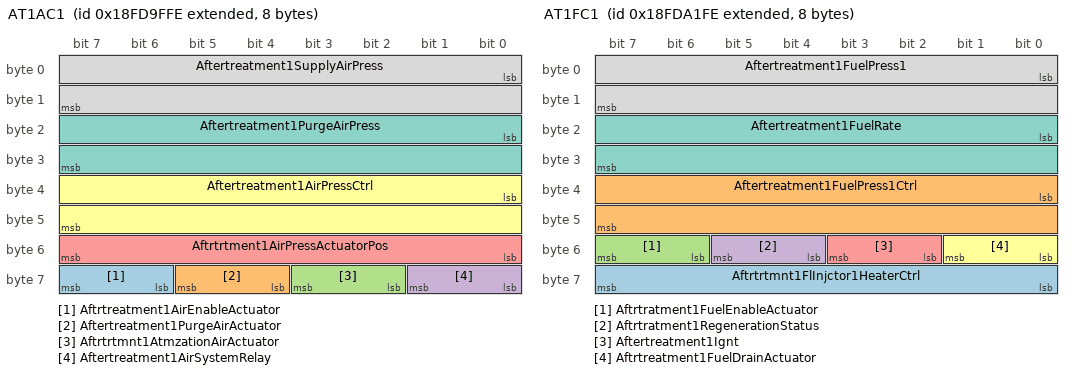
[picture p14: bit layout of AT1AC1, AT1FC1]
BO_ 2566758398 AT1AC1: 8 Vector__XXX
   SG_ Aftrtreatment1AirEnableActuator : 62|2@1+ (1,0) [0|3] "" Vector__XXX
   SG_ Aftertreatment1PurgeAirActuator : 60|2@1+ (1,0) [0|3] "" Vector__XXX
   SG_ Aftrtrtmnt1AtmzationAirActuator : 58|2@1+ (1,0) [0|3] "" Vector__XXX
   SG_ Aftertreatment1AirSystemRelay : 56|2@1+ (1,0) [0|3] "" Vector__XXX
   SG_ Aftrtrtment1AirPressActuatorPos : 48|8@1+ (0.4,0) [0|100] "%" Vector__XXX
   SG_ Aftertreatment1AirPressCtrl : 32|16@1+ (0.0025,0) [0|160.637] "%" Vector__XXX
   SG_ Aftertreatment1PurgeAirPress : 16|16@1+ (0.1,0) [0|6425.5] "kPa" Vector__XXX
   SG_ Aftertreatment1SupplyAirPress : 0|16@1+ (0.1,0) [0|6425.5] "kPa" Vector__XXX

BO_ 2566745598 AT1AC2: 8 Vector__XXX
   SG_ Aftertreatment1SecondAirPress : 48|16@1+ (0.1,0) [0|6425.5] "kPa" Vector__XXX
   SG_ Aftrtreatment1SecondAirMassFlow : 32|16@1+ (0.2,0) [0|12851] "kg/h" Vector__XXX
   SG_ Aftertreatment1SecondAirTemp : 16|16@1+ (0.03125,-273) [-273|1734.97] "deg C" Vector__XXX
   SG_ Aftrtratment1SecondAirDiffPress : 0|16@1+ (0.0078125,-250) [-250|251.99] "kPa" Vector__XXX

BO_ 2566758910 AT1FC1: 8 Vector__XXX
   SG_ Aftrtrtmnt1FlInjctor1HeaterCtrl : 56|8@1+ (0.4,0) [0|100] "%" Vector__XXX
   SG_ Aftertreatment1FuelPress1Ctrl : 32|16@1+ (0.0025,0) [0|160.637] "%" Vector__XXX
   SG_ Aftrtratment1FuelEnableActuator : 54|2@1+ (1,0) [0|3] "" Vector__XXX
   SG_ Aftrtratment1RegenerationStatus : 52|2@1+ (1,0) [0|3] "" Vector__XXX
   SG_ Aftertreatment1Ignt : 50|2@1+ (1,0) [0|3] "" Vector__XXX
   SG_ Aftrtreatment1FuelDrainActuator : 48|2@1+ (1,0) [0|3] "" Vector__XXX
   SG_ Aftertreatment1FuelRate : 16|16@1+ (0.05,0) [0|3212.75] "L/h" Vector__XXX
   SG_ Aftertreatment1FuelPress1 : 0|16@1+ (0.1,0) [0|6425.5] "kPa" Vector__XXX

BO_ 2566743550 AT1FC2: 8 Vector__XXX
   SG_ Aftrtrtmnt1HydrcrbnDsrIntkFlTmp : 40|8@1+ (1,-40) [-40|210] "deg C" Vector__XXX
   SG_ Aftrtrtmnt1FlPress2ActuatorCtrl : 24|16@1+ (0.0025,0) [0|160.637] "%" Vector__XXX
   SG_ Aftrtrtmnt1FlFlwDvrterValveCtrl : 18|2@1+ (1,0) [0|3] "" Vector__XXX
   SG_ Aftrtreatment1FuelPumpRelayCtrl : 16|2@1+ (1,0) [0|3] "" Vector__XXX
   SG_ Aftertreatment1FuelPress2 : 0|16@1+ (0.1,0) [0|6425.5] "kPa" Vector__XXX

BO_ 2566753534 AT1GP: 8 Vector__XXX
   SG_ DslPrticulateFilterOutletPress1 : 16|16@1+ (0.1,0) [0|6425.5] "kPa" Vector__XXX
   SG_ DslPrticulateFilterIntakePress1 : 0|16@1+ (0.1,0) [0|6425.5] "kPa" Vector__XXX

BO_ 2566756606 AT1HI: 36 Vector__XXX
   SG_ Aftrtrtmnt1TtlNmbrOfActvRgnrtnMn : 224|32@1+ (1,0) [0|4.29497e+09] "counts" Vector__XXX
   SG_ Aftrtrtmnt1TtlNmbrOfActvRgnrtnIn : 192|32@1+ (1,0) [0|4.29497e+09] "counts" Vector__XXX
   SG_ Aftrtrtmnt1AvrgTmBtwnActvRgnrtns : 256|32@1+ (1,0) [0|4.21108e+09] "s" Vector__XXX
   SG_ Aftrtrtmnt1TtlNmbrOfPssvRgnrtns : 160|32@1+ (1,0) [0|4.29497e+09] "counts" Vector__XXX
   SG_ Aftrtrtmnt1TtlPssvRgnrationTime : 128|32@1+ (1,0) [0|4.21108e+09] "s" Vector__XXX
   SG_ Aftrtrtmnt1TtlNmbrOfActvRgnrtns : 96|32@1+ (1,0) [0|4.29497e+09] "counts" Vector__XXX
   SG_ Aftrtreatment1TotalDisabledTime : 64|32@1+ (1,0) [0|4.21108e+09] "s" Vector__XXX
   SG_ Aftrtrtmnt1TtalRegenerationTime : 32|32@1+ (1,0) [0|4.21108e+09] "s" Vector__XXX
   SG_ Aftertreatment1TotalFuelUsed : 0|32@1+ (0.5,0) [0|2.10554e+09] "L" Vector__XXX

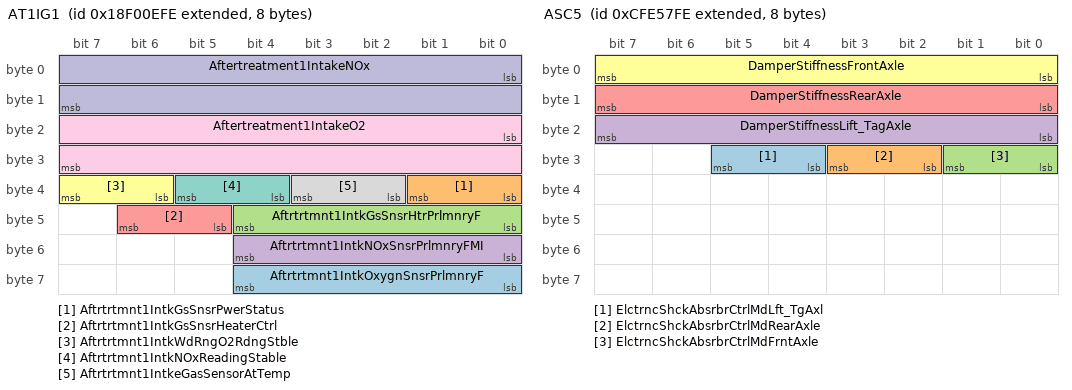
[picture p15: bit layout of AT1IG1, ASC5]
BO_ 2565869310 AT1IG1: 8 Vector__XXX
   SG_ Aftrtrtmnt1IntkOxygnSnsrPrlmnryF : 56|5@1+ (1,0) [0|31] "" Vector__XXX
   SG_ Aftrtrtmnt1IntkGsSnsrPwerStatus : 32|2@1+ (1,0) [0|3] "" Vector__XXX
   SG_ Aftrtrtmnt1IntkGsSnsrHtrPrlmnryF : 40|5@1+ (1,0) [0|31] "" Vector__XXX
   SG_ Aftrtrtmnt1IntkNOxSnsrPrlmnryFMI : 48|5@1+ (1,0) [0|31] "" Vector__XXX
   SG_ Aftrtrtmnt1IntkGsSnsrHeaterCtrl : 45|2@1+ (1,0) [0|3] "" Vector__XXX
   SG_ Aftrtrtmnt1IntkWdRngO2RdngStble : 38|2@1+ (1,0) [0|3] "" Vector__XXX
   SG_ Aftrtrtmnt1IntkNOxReadingStable : 36|2@1+ (1,0) [0|3] "" Vector__XXX
   SG_ Aftrtrtmnt1IntkeGasSensorAtTemp : 34|2@1+ (1,0) [0|3] "" Vector__XXX
   SG_ Aftertreatment1IntakeO2 : 16|16@1+ (0.000514,-12) [-12|21] "%" Vector__XXX
   SG_ Aftertreatment1IntakeNOx : 0|16@1+ (0.05,-200) [-200|3012.75] "ppm" Vector__XXX

BO_ 2566763774 AT1IG2: 8 Vector__XXX
   SG_ Aftrtrtmnt1DslPrtcltFltrIntkGsTm : 40|5@1+ (1,0) [0|31] "" Vector__XXX
   SG_ Aftrtrtmnt1ExhstGsTmp1PrlmnryFMI : 32|5@1+ (1,0) [0|31] "" Vector__XXX
   SG_ Aftertreatment1ExhaustGasTemp1 : 0|16@1+ (0.03125,-273) [-273|1734.97] "deg C" Vector__XXX
   SG_ Aftrtrtmnt1DslPrtcltFltrInt_0000 : 16|16@1+ (0.03125,-273) [-273|1734.97] "deg C" Vector__XXX

BO_ 2631728894 ATS: 8 Vector__XXX
   SG_ AntitheftRandomNumber : 8|56@1+ (1,0) [0|255] "" Vector__XXX
   SG_ AntitheftComponentStatusStates : 4|2@1+ (1,0) [0|3] "" Vector__XXX
   SG_ AntthftEncryptnSdPrsntIndicator : 0|2@1+ (1,0) [0|3] "" Vector__XXX
   SG_ AntitheftModifyPwdStates : 6|2@1+ (1,0) [0|3] "" Vector__XXX
   SG_ AntitheftPwdValidIndicator : 2|2@1+ (1,0) [0|3] "" Vector__XXX

BO_ 2631794430 ATR: 8 Vector__XXX
   SG_ AntitheftPasswordRepresentation : 8|56@1+ (1,0) [0|255] "" Vector__XXX
   SG_ AntitheftCmdStates : 5|3@1+ (1,0) [0|7] "" Vector__XXX
   SG_ AntitheftDesiredExitModeStates : 3|2@1+ (1,0) [0|3] "" Vector__XXX
   SG_ AntthftEncryptonIndicatorStates : 1|2@1+ (1,0) [0|3] "" Vector__XXX

BO_ 2633934846 AT: 8 Vector__XXX
   SG_ EngAltWinding3Temp : 32|8@1+ (1,-40) [-40|210] "deg C" Vector__XXX
   SG_ EngAltWinding2Temp : 24|8@1+ (1,-40) [-40|210] "deg C" Vector__XXX
   SG_ EngAltWinding1Temp : 16|8@1+ (1,-40) [-40|210] "deg C" Vector__XXX
   SG_ EngAltBearing2Temp : 8|8@1+ (1,-40) [-40|210] "deg C" Vector__XXX
   SG_ EngAltBearing1Temp : 0|8@1+ (1,-40) [-40|210] "deg C" Vector__XXX

BO_ 2362572542 ASC6: 8 Vector__XXX
   SG_ LevelPresetRearAxleRight : 48|16@1+ (0.1,-3200) [-3200|3225.5] "mm" Vector__XXX
   SG_ LevelPresetRearAxleLeft : 32|16@1+ (0.1,-3200) [-3200|3225.5] "mm" Vector__XXX
   SG_ LevelPresetFrontAxleRight : 16|16@1+ (0.1,-3200) [-3200|3225.5] "mm" Vector__XXX
   SG_ LevelPresetFrontAxleLeft : 0|16@1+ (0.1,-3200) [-3200|3225.5] "mm" Vector__XXX

BO_ 2365478910 ASC5: 8 Vector__XXX
   SG_ ElctrncShckAbsrbrCtrlMdLft_TgAxl : 28|2@1+ (1,0) [0|3] "" Vector__XXX
   SG_ ElctrncShckAbsrbrCtrlMdRearAxle : 26|2@1+ (1,0) [0|3] "" Vector__XXX
   SG_ ElctrncShckAbsrbrCtrlMdFrntAxle : 24|2@1+ (1,0) [0|3] "" Vector__XXX
   SG_ DamperStiffnessLift_TagAxle : 16|8@1+ (0.4,0) [0|100] "%" Vector__XXX
   SG_ DamperStiffnessRearAxle : 8|8@1+ (0.4,0) [0|100] "%" Vector__XXX
   SG_ DamperStiffnessFrontAxle : 0|8@1+ (0.4,0) [0|100] "%" Vector__XXX

BO_ 2560950014 DM30: 12 Vector__XXX
   SG_ TestLimitMinimum : 80|16@1+ (1,0) [0|64255] "" Vector__XXX
   SG_ TestLimitMaximum : 64|16@1+ (1,0) [0|64255] "" Vector__XXX
   SG_ TestValue : 48|16@1+ (1,0) [0|64255] "" Vector__XXX
   SG_ SlotId : 32|16@1+ (1,0) [0|64255] "" Vector__XXX
   SG_ TestIdentifier : 0|8@1+ (1,0) [0|255] "" Vector__XXX
   SG_ FailureModeIdentifier1 : 24|5@1+ (1,0) [0|0] "" Vector__XXX
   SG_ SPN1High : 29|3@1+ (1,0) [0|7] "" Vector__XXX
   SG_ SPN1 : 8|16@1+ (1,0) [0|65536] "" Vector__XXX

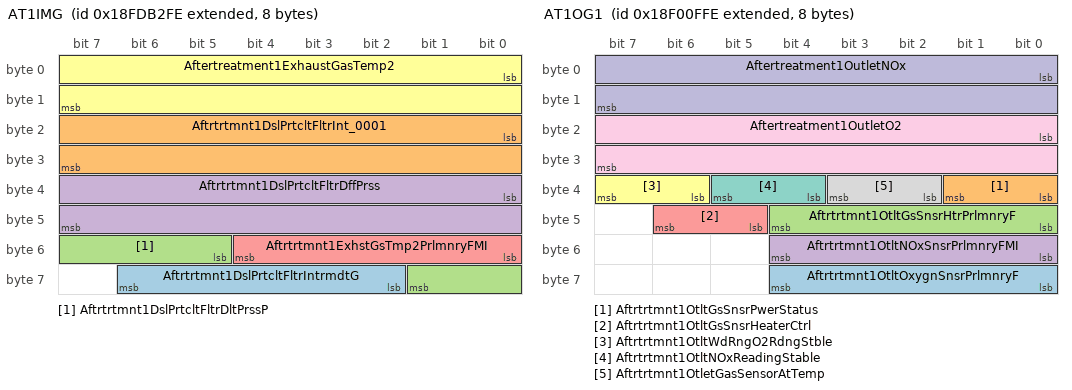
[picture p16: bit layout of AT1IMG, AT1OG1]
BO_ 2566763262 AT1IMG: 8 Vector__XXX
   SG_ Aftrtrtmnt1DslPrtcltFltrIntrmdtG : 58|5@1+ (1,0) [0|31] "" Vector__XXX
   SG_ Aftrtrtmnt1DslPrtcltFltrInt_0001 : 16|16@1+ (0.03125,-273) [-273|1734.97] "deg C" Vector__XXX
   SG_ Aftrtrtmnt1DslPrtcltFltrDltPrssP : 53|5@1+ (1,0) [0|31] "" Vector__XXX
   SG_ Aftrtrtmnt1DslPrtcltFltrDffPrss : 32|16@1+ (0.1,0) [0|6425.5] "kPa" Vector__XXX
   SG_ Aftrtrtmnt1ExhstGsTmp2PrlmnryFMI : 48|5@1+ (1,0) [0|31] "" Vector__XXX
   SG_ Aftertreatment1ExhaustGasTemp2 : 0|16@1+ (0.03125,-273) [-273|1734.97] "deg C" Vector__XXX

BO_ 2565869566 AT1OG1: 8 Vector__XXX
   SG_ Aftrtrtmnt1OtltOxygnSnsrPrlmnryF : 56|5@1+ (1,0) [0|31] "" Vector__XXX
   SG_ Aftrtrtmnt1OtltGsSnsrPwerStatus : 32|2@1+ (1,0) [0|3] "" Vector__XXX
   SG_ Aftrtrtmnt1OtltGsSnsrHtrPrlmnryF : 40|5@1+ (1,0) [0|31] "" Vector__XXX
   SG_ Aftrtrtmnt1OtltNOxSnsrPrlmnryFMI : 48|5@1+ (1,0) [0|31] "" Vector__XXX
   SG_ Aftrtrtmnt1OtltGsSnsrHeaterCtrl : 45|2@1+ (1,0) [0|3] "" Vector__XXX
   SG_ Aftrtrtmnt1OtltWdRngO2RdngStble : 38|2@1+ (1,0) [0|3] "" Vector__XXX
   SG_ Aftrtrtmnt1OtltNOxReadingStable : 36|2@1+ (1,0) [0|3] "" Vector__XXX
   SG_ Aftrtrtmnt1OtletGasSensorAtTemp : 34|2@1+ (1,0) [0|3] "" Vector__XXX
   SG_ Aftertreatment1OutletO2 : 16|16@1+ (0.000514,-12) [-12|21] "%" Vector__XXX
   SG_ Aftertreatment1OutletNOx : 0|16@1+ (0.05,-200) [-200|3012.75] "ppm" Vector__XXX

BO_ 2566763518 AT1OG2: 8 Vector__XXX
   SG_ Aftrtrtmnt1DslPrtcltFltrOtltGsTm : 16|16@1+ (0.03125,-273) [-273|1734.97] "deg C" Vector__XXX
   SG_ Aftrtrtmnt1DslPrtcltFltrOtltExhs : 40|5@1+ (1,0) [0|31] "" Vector__XXX
   SG_ Aftrtrtmnt1ExhstGsTmp3PrlmnryFMI : 32|5@1+ (1,0) [0|31] "" Vector__XXX
   SG_ Aftertreatment1ExhaustGasTemp3 : 0|16@1+ (0.03125,-273) [-273|1734.97] "deg C" Vector__XXX

BO_ 2566749182 AT1S: 8 Vector__XXX
   SG_ DslPrtclteFilter1AshLoadPercent : 8|8@1+ (1,0) [0|250] "%" Vector__XXX
   SG_ DslPrtcltFltr1TmSncLstActvRgnrtn : 16|32@1+ (1,0) [0|4.21108e+09] "s" Vector__XXX
   SG_ DslPrtcltFilter1SootLoadPercent : 0|8@1+ (1,0) [0|250] "%" Vector__XXX
   SG_ Aftrtrtmnt1DslPrtcltFltrStLdRgnr : 48|16@1+ (0.0025,0) [0|160.637] "%" Vector__XXX

BO_ 2566748670 AT1TI: 32 Vector__XXX
   SG_ Aftrtrtmnt1TrpNmbrOfActvRgnrtnMn : 224|32@1+ (1,0) [0|4.29497e+09] "counts" Vector__XXX
   SG_ Aftrtrtmnt1TrpNmbrOfActvRgnrtnIn : 192|32@1+ (1,0) [0|4.29497e+09] "counts" Vector__XXX
   SG_ Aftrtrtmnt1TrpNmbrOfPssvRgnrtns : 160|32@1+ (1,0) [0|4.29497e+09] "counts" Vector__XXX
   SG_ Aftrtrtmnt1TrpPssvRgnrationTime : 128|32@1+ (1,0) [0|4.21108e+09] "s" Vector__XXX
   SG_ Aftrtrtmnt1TrpNmbrOfActvRgnrtns : 96|32@1+ (1,0) [0|4.29497e+09] "counts" Vector__XXX
   SG_ Aftertreatment1TripDisabledTime : 64|32@1+ (1,0) [0|4.21108e+09] "s" Vector__XXX
   SG_ Aftrtrtmnt1TrpActvRgnrationTime : 32|32@1+ (1,0) [0|4.21108e+09] "s" Vector__XXX
   SG_ Aftertreatment1TripFuelUsed : 0|32@1+ (0.5,0) [0|2.10554e+09] "L" Vector__XXX

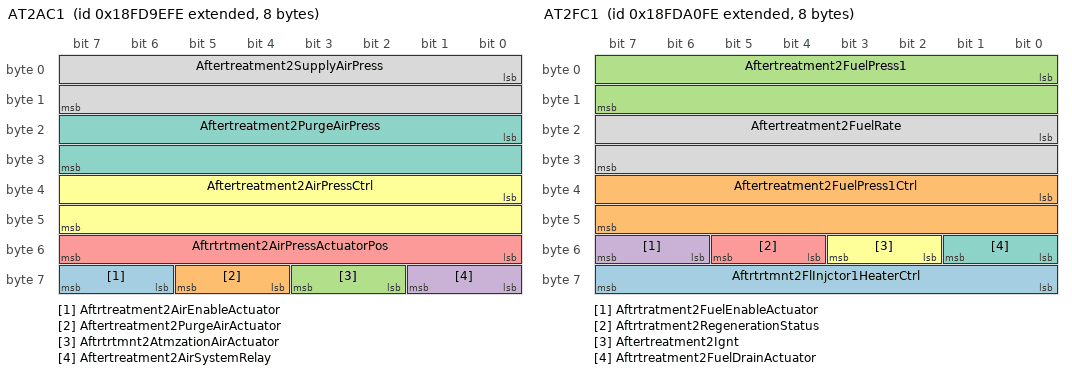
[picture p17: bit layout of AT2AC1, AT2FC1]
BO_ 2566758142 AT2AC1: 8 Vector__XXX
   SG_ Aftrtreatment2AirEnableActuator : 62|2@1+ (1,0) [0|3] "" Vector__XXX
   SG_ Aftertreatment2PurgeAirActuator : 60|2@1+ (1,0) [0|3] "" Vector__XXX
   SG_ Aftrtrtmnt2AtmzationAirActuator : 58|2@1+ (1,0) [0|3] "" Vector__XXX
   SG_ Aftertreatment2AirSystemRelay : 56|2@1+ (1,0) [0|3] "" Vector__XXX
   SG_ Aftrtrtment2AirPressActuatorPos : 48|8@1+ (0.4,0) [0|100] "%" Vector__XXX
   SG_ Aftertreatment2AirPressCtrl : 32|16@1+ (0.0025,0) [0|160.637] "%" Vector__XXX
   SG_ Aftertreatment2PurgeAirPress : 16|16@1+ (0.1,0) [0|6425.5] "kPa" Vector__XXX
   SG_ Aftertreatment2SupplyAirPress : 0|16@1+ (0.1,0) [0|6425.5] "kPa" Vector__XXX

BO_ 2566745342 AT2AC2: 8 Vector__XXX
   SG_ Aftertreatment2SecondAirPress : 48|16@1+ (0.1,0) [0|6425.5] "kPa" Vector__XXX
   SG_ Aftrtreatment2SecondAirMassFlow : 32|16@1+ (0.2,0) [0|12851] "kg/h" Vector__XXX
   SG_ Aftertreatment2SecondAirTemp : 16|16@1+ (0.03125,-273) [-273|1734.97] "deg C" Vector__XXX
   SG_ Aftrtratment2SecondAirDiffPress : 0|16@1+ (0.0078125,-250) [-250|251.99] "kPa" Vector__XXX

BO_ 2566758654 AT2FC1: 8 Vector__XXX
   SG_ Aftrtrtmnt2FlInjctor1HeaterCtrl : 56|8@1+ (0.4,0) [0|100] "%" Vector__XXX
   SG_ Aftertreatment2FuelPress1Ctrl : 32|16@1+ (0.0025,0) [0|160.637] "%" Vector__XXX
   SG_ Aftertreatment2FuelPress1 : 0|16@1+ (0.1,0) [0|6425.5] "kPa" Vector__XXX
   SG_ Aftrtratment2FuelEnableActuator : 54|2@1+ (1,0) [0|3] "" Vector__XXX
   SG_ Aftrtratment2RegenerationStatus : 52|2@1+ (1,0) [0|3] "" Vector__XXX
   SG_ Aftertreatment2Ignt : 50|2@1+ (1,0) [0|3] "" Vector__XXX
   SG_ Aftrtreatment2FuelDrainActuator : 48|2@1+ (1,0) [0|3] "" Vector__XXX
   SG_ Aftertreatment2FuelRate : 16|16@1+ (0.05,0) [0|3212.75] "L/h" Vector__XXX

BO_ 2566753278 AT2GP: 8 Vector__XXX
   SG_ DslPrticulateFilterOutletPress2 : 16|16@1+ (0.1,0) [0|6425.5] "kPa" Vector__XXX
   SG_ DslPrticulateFilterIntakePress2 : 0|16@1+ (0.1,0) [0|6425.5] "kPa" Vector__XXX

BO_ 2566756862 AT2HI: 36 Vector__XXX
   SG_ Aftrtrtmnt2TtlNmbrOfActvRgnrtnMn : 224|32@1+ (1,0) [0|4.29497e+09] "counts" Vector__XXX
   SG_ Aftrtrtmnt2TtlNmbrOfActvRgnrtnIn : 192|32@1+ (1,0) [0|4.29497e+09] "counts" Vector__XXX
   SG_ Aftrtrtmnt2AvrgTmBtwnActvRgnrtns : 256|32@1+ (1,0) [0|4.21108e+09] "s" Vector__XXX
   SG_ Aftrtrtmnt2TtlNmbrOfPssvRgnrtns : 160|32@1+ (1,0) [0|4.29497e+09] "counts" Vector__XXX
   SG_ Aftrtrtmnt2TtlPssvRgnrationTime : 128|32@1+ (1,0) [0|4.21108e+09] "s" Vector__XXX
   SG_ Aftrtrtmnt2TtlNmbrOfActvRgnrtns : 96|32@1+ (1,0) [0|4.29497e+09] "counts" Vector__XXX
   SG_ Aftrtreatment2TotalDisabledTime : 64|32@1+ (1,0) [0|4.21108e+09] "s" Vector__XXX
   SG_ Aftrtrtmnt2TtalRegenerationTime : 32|32@1+ (1,0) [0|4.21108e+09] "s" Vector__XXX
   SG_ Aftertreatment2TotalFuelUsed : 0|32@1+ (0.5,0) [0|2.10554e+09] "L" Vector__XXX

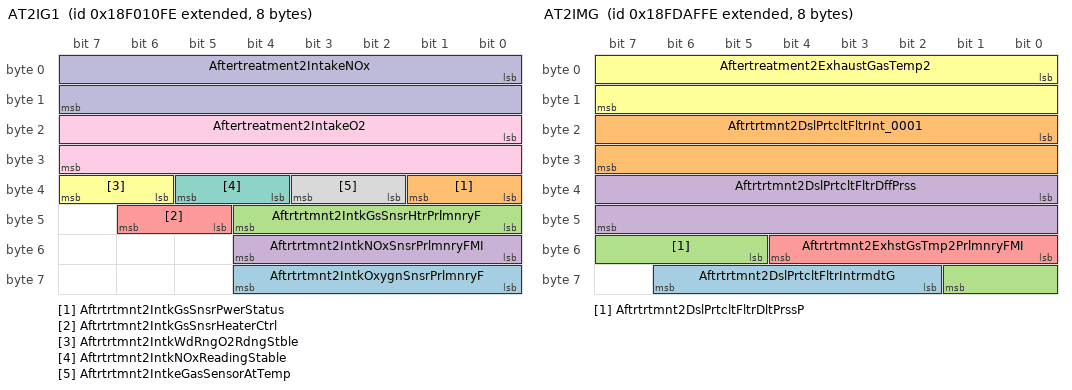
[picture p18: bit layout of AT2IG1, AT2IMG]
BO_ 2565869822 AT2IG1: 8 Vector__XXX
   SG_ Aftrtrtmnt2IntkOxygnSnsrPrlmnryF : 56|5@1+ (1,0) [0|31] "" Vector__XXX
   SG_ Aftrtrtmnt2IntkGsSnsrPwerStatus : 32|2@1+ (1,0) [0|3] "" Vector__XXX
   SG_ Aftrtrtmnt2IntkGsSnsrHtrPrlmnryF : 40|5@1+ (1,0) [0|31] "" Vector__XXX
   SG_ Aftrtrtmnt2IntkNOxSnsrPrlmnryFMI : 48|5@1+ (1,0) [0|31] "" Vector__XXX
   SG_ Aftrtrtmnt2IntkGsSnsrHeaterCtrl : 45|2@1+ (1,0) [0|3] "" Vector__XXX
   SG_ Aftrtrtmnt2IntkWdRngO2RdngStble : 38|2@1+ (1,0) [0|3] "" Vector__XXX
   SG_ Aftrtrtmnt2IntkNOxReadingStable : 36|2@1+ (1,0) [0|3] "" Vector__XXX
   SG_ Aftrtrtmnt2IntkeGasSensorAtTemp : 34|2@1+ (1,0) [0|3] "" Vector__XXX
   SG_ Aftertreatment2IntakeO2 : 16|16@1+ (0.000514,-12) [-12|21] "%" Vector__XXX
   SG_ Aftertreatment2IntakeNOx : 0|16@1+ (0.05,-200) [-200|3012.75] "ppm" Vector__XXX

BO_ 2566763006 AT2IG2: 8 Vector__XXX
   SG_ Aftrtrtmnt2DslPrtcltFltrIntkGsTm : 40|5@1+ (1,0) [0|31] "" Vector__XXX
   SG_ Aftrtrtmnt2ExhstGsTmp1PrlmnryFMI : 32|5@1+ (1,0) [0|31] "" Vector__XXX
   SG_ Aftertreatment2ExhaustGasTemp1 : 0|16@1+ (0.03125,-273) [-273|1734.97] "deg C" Vector__XXX
   SG_ Aftrtrtmnt2DslPrtcltFltrInt_0000 : 16|16@1+ (0.03125,-273) [-273|1734.97] "deg C" Vector__XXX

BO_ 2566762494 AT2IMG: 8 Vector__XXX
   SG_ Aftrtrtmnt2DslPrtcltFltrIntrmdtG : 58|5@1+ (1,0) [0|31] "" Vector__XXX
   SG_ Aftrtrtmnt2DslPrtcltFltrInt_0001 : 16|16@1+ (0.03125,-273) [-273|1734.97] "deg C" Vector__XXX
   SG_ Aftrtrtmnt2DslPrtcltFltrDltPrssP : 53|5@1+ (1,0) [0|31] "" Vector__XXX
   SG_ Aftrtrtmnt2DslPrtcltFltrDffPrss : 32|16@1+ (0.1,0) [0|6425.5] "kPa" Vector__XXX
   SG_ Aftrtrtmnt2ExhstGsTmp2PrlmnryFMI : 48|5@1+ (1,0) [0|31] "" Vector__XXX
   SG_ Aftertreatment2ExhaustGasTemp2 : 0|16@1+ (0.03125,-273) [-273|1734.97] "deg C" Vector__XXX

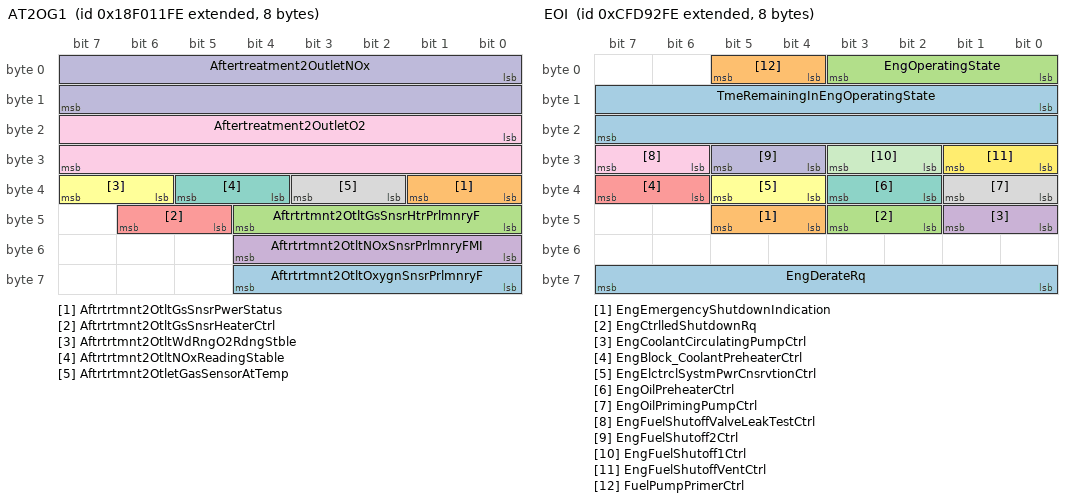
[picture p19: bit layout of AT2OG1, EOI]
BO_ 2565870078 AT2OG1: 8 Vector__XXX
   SG_ Aftrtrtmnt2OtltOxygnSnsrPrlmnryF : 56|5@1+ (1,0) [0|31] "" Vector__XXX
   SG_ Aftrtrtmnt2OtltGsSnsrPwerStatus : 32|2@1+ (1,0) [0|3] "" Vector__XXX
   SG_ Aftrtrtmnt2OtltGsSnsrHtrPrlmnryF : 40|5@1+ (1,0) [0|31] "" Vector__XXX
   SG_ Aftrtrtmnt2OtltNOxSnsrPrlmnryFMI : 48|5@1+ (1,0) [0|31] "" Vector__XXX
   SG_ Aftrtrtmnt2OtltGsSnsrHeaterCtrl : 45|2@1+ (1,0) [0|3] "" Vector__XXX
   SG_ Aftrtrtmnt2OtltWdRngO2RdngStble : 38|2@1+ (1,0) [0|3] "" Vector__XXX
   SG_ Aftrtrtmnt2OtltNOxReadingStable : 36|2@1+ (1,0) [0|3] "" Vector__XXX
   SG_ Aftrtrtmnt2OtletGasSensorAtTemp : 34|2@1+ (1,0) [0|3] "" Vector__XXX
   SG_ Aftertreatment2OutletO2 : 16|16@1+ (0.000514,-12) [-12|21] "%" Vector__XXX
   SG_ Aftertreatment2OutletNOx : 0|16@1+ (0.05,-200) [-200|3012.75] "ppm" Vector__XXX

BO_ 2566762750 AT2OG2: 8 Vector__XXX
   SG_ Aftrtrtmnt2DslPrtcltFltrOtltGsTm : 16|16@1+ (0.03125,-273) [-273|1734.97] "deg C" Vector__XXX
   SG_ Aftrtrtmnt2DslPrtcltFltrExhstGsT : 40|5@1+ (1,0) [0|31] "" Vector__XXX
   SG_ Aftrtrtmnt2ExhstGsTmp3PrlmnryFMI : 32|5@1+ (1,0) [0|31] "" Vector__XXX
   SG_ Aftertreatment2ExhaustGasTemp3 : 0|16@1+ (0.03125,-273) [-273|1734.97] "deg C" Vector__XXX

BO_ 2566748926 AT2S: 8 Vector__XXX
   SG_ DslPrtclteFilter2AshLoadPercent : 8|8@1+ (1,0) [0|250] "%" Vector__XXX
   SG_ DslPrtcltFltr2TmSncLstActvRgnrtn : 16|32@1+ (1,0) [0|4.21108e+09] "s" Vector__XXX
   SG_ DslPrtcltFilter2SootLoadPercent : 0|8@1+ (1,0) [0|250] "%" Vector__XXX
   SG_ Aftrtrtmnt2DslPrtcltFltrStLdRgnr : 48|16@1+ (0.0025,0) [0|160.637] "%" Vector__XXX

BO_ 2566748414 AT2TI: 32 Vector__XXX
   SG_ Aftrtrtmnt2TrpNmbrOfActvRgnrtnMn : 224|32@1+ (1,0) [0|4.29497e+09] "counts" Vector__XXX
   SG_ Aftrtrtmnt2TrpNmbrOfActvRgnrtnIn : 192|32@1+ (1,0) [0|4.29497e+09] "counts" Vector__XXX
   SG_ Aftrtrtmnt2TrpNmbrOfPssvRgnrtns : 160|32@1+ (1,0) [0|4.29497e+09] "counts" Vector__XXX
   SG_ Aftrtrtmnt2TrpPssvRgnrationTime : 128|32@1+ (1,0) [0|4.21108e+09] "s" Vector__XXX
   SG_ Aftrtrtmnt2TrpNmbrOfActvRgnrtns : 96|32@1+ (1,0) [0|4.29497e+09] "counts" Vector__XXX
   SG_ Aftertreatment2TripDisabledTime : 64|32@1+ (1,0) [0|4.21108e+09] "s" Vector__XXX
   SG_ Aftrtrtmnt2TrpActvRgnrationTime : 32|32@1+ (1,0) [0|4.21108e+09] "s" Vector__XXX
   SG_ Aftertreatment2TripFuelUsed : 0|32@1+ (0.5,0) [0|2.10554e+09] "L" Vector__XXX

BO_ 2365428478 EOI: 8 Vector__XXX
   SG_ EngDerateRq : 56|8@1+ (0.4,0) [0|100] "%" Vector__XXX
   SG_ EngEmergencyShutdownIndication : 44|2@1+ (1,0) [0|3] "" Vector__XXX
   SG_ EngCtrlledShutdownRq : 42|2@1+ (1,0) [0|3] "" Vector__XXX
   SG_ EngCoolantCirculatingPumpCtrl : 40|2@1+ (1,0) [0|3] "" Vector__XXX
   SG_ EngBlock_CoolantPreheaterCtrl : 38|2@1+ (1,0) [0|3] "" Vector__XXX
   SG_ EngElctrclSystmPwrCnsrvtionCtrl : 36|2@1+ (1,0) [0|3] "" Vector__XXX
   SG_ EngOilPreheaterCtrl : 34|2@1+ (1,0) [0|3] "" Vector__XXX
   SG_ EngOilPrimingPumpCtrl : 32|2@1+ (1,0) [0|3] "" Vector__XXX
   SG_ EngFuelShutoffValveLeakTestCtrl : 30|2@1+ (1,0) [0|3] "" Vector__XXX
   SG_ EngFuelShutoff2Ctrl : 28|2@1+ (1,0) [0|3] "" Vector__XXX
   SG_ EngFuelShutoff1Ctrl : 26|2@1+ (1,0) [0|3] "" Vector__XXX
   SG_ EngFuelShutoffVentCtrl : 24|2@1+ (1,0) [0|3] "" Vector__XXX
   SG_ TmeRemainingInEngOperatingState : 8|16@1+ (1,0) [0|64255] "s" Vector__XXX
   SG_ FuelPumpPrimerCtrl : 4|2@1+ (1,0) [0|3] "" Vector__XXX
   SG_ EngOperatingState : 0|4@1+ (1,0) [0|15] "" Vector__XXX

BO_ 2566743806 ET4: 8 Vector__XXX
   SG_ EngExhstVlvActtionSystemOilTemp : 24|16@1+ (0.03125,-273) [-273|1734.97] "deg C" Vector__XXX
   SG_ EngExhstGsRcrcltn1MxrIntakeTemp : 40|16@1+ (0.03125,-273) [-273|1734.97] "deg C" Vector__XXX
   SG_ EngCoolantThermostatOpening : 16|8@1+ (0.4,0) [0|100] "%" Vector__XXX
   SG_ EngCoolantPumpOutletTemp : 8|8@1+ (1,-40) [-40|210] "deg C" Vector__XXX
   SG_ EngCoolantTemp2 : 0|8@1+ (1,-40) [-40|210] "deg C" Vector__XXX

BO_ 2499635454 GCVW: 8 Vector__XXX
   SG_ NetVehicleWeightChange : 24|24@1+ (2,-1.64495e+07) [-1.64495e+07|1.64495e+07] "kg" Vector__XXX
   SG_ GrossCombinationWeight : 0|24@1+ (2,0) [0|3.28991e+07] "kg" Vector__XXX

BO_ 2550660862 GPV4: 8 Vector__XXX
   SG_ ValveAssemblySupplyPress : 40|16@1+ (5,0) [0|321275] "kPa" Vector__XXX
   SG_ ValveAssemblyLoadSensePress : 24|16@1+ (5,0) [0|321275] "kPa" Vector__XXX
   SG_ ValvePilotPress : 16|8@1+ (16,0) [0|4000] "kPa" Vector__XXX
   SG_ ValveLoadSensePress : 0|16@1+ (5,0) [0|321275] "kPa" Vector__XXX

BA_DEF_ SG_ "SigType" ENUM "Default","Range","RangeSigned","ASCII","Discrete","Control","ReferencePGN","DTC","StringDelimiter","StringLength","StringLengthControl";
BA_DEF_ SG_ "GenSigStartValue" INT 0 10000;
BA_DEF_ SG_ "GenSigSendType" ENUM "Default","Range","RangeSigned","ASCII","Discrete","Control","ReferencePGN","DTC","StringDelimiter","StringLength","StringLengthControl","Default","Range","RangeSigned","ASCII","Discrete","Control","ReferencePGN","DTC","StringDelimiter","StringLength","StringLengthControl","Cyclic","OnWrite","reserved","OnChange","reserved","reserved","reserved","NoSigSendType";
BA_DEF_ SG_ "GenSigILSupport" ENUM "Default","Range","RangeSigned","ASCII","Discrete","Control","ReferencePGN","DTC","StringDelimiter","StringLength","StringLengthControl","Default","Range","RangeSigned","ASCII","Discrete","Control","ReferencePGN","DTC","StringDelimiter","StringLength","StringLengthControl","Cyclic","OnWrite","reserved","OnChange","reserved","reserved","reserved","NoSigSendType","Default","Range","RangeSigned","ASCII","Discrete","Control","ReferencePGN","DTC","StringDelimiter","StringLength","StringLengthControl","Cyclic","OnWrite","reserved","OnChange","reserved","reserved","reserved","NoSigSendType","Yes","No";
BA_DEF_ SG_ "GenSigEVName" STRING ;
BA_DEF_ SG_ "SPN" INT 0 524287;
BA_DEF_ BO_ "GenMsgStartDelayTime" INT 0 100000;
BA_DEF_ BO_ "GenMsgILSupport" ENUM "Default","Range","RangeSigned","ASCII","Discrete","Control","ReferencePGN","DTC","StringDelimiter","StringLength","StringLengthControl","Default","Range","RangeSigned","ASCII","Discrete","Control","ReferencePGN","DTC","StringDelimiter","StringLength","StringLengthControl","Cyclic","OnWrite","reserved","OnChange","reserved","reserved","reserved","NoSigSendType","Default","Range","RangeSigned","ASCII","Discrete","Control","ReferencePGN","DTC","StringDelimiter","StringLength","StringLengthControl","Cyclic","OnWrite","reserved","OnChange","reserved","reserved","reserved","NoSigSendType","Yes","No","Default","Range","RangeSigned","ASCII","Discrete","Control","ReferencePGN","DTC","StringDelimiter","StringLength","StringLengthControl","Cyclic","OnWrite","reserved","OnChange","reserved","reserved","reserved","NoSigSendType","Yes","No","Yes","No";
BA_DEF_ BO_ "GenMsgRequestable" INT 0 1;
BA_DEF_ BO_ "GenMsgSendType" ENUM "Default","Range","RangeSigned","ASCII","Discrete","Control","ReferencePGN","DTC","StringDelimiter","StringLength","StringLengthControl","Default","Range","RangeSigned","ASCII","Discrete","Control","ReferencePGN","DTC","StringDelimiter","StringLength","StringLengthControl","Cyclic","OnWrite","reserved","OnChange","reserved","reserved","reserved","NoSigSendType","Default","Range","RangeSigned","ASCII","Discrete","Control","ReferencePGN","DTC","StringDelimiter","StringLength","StringLengthControl","Cyclic","OnWrite","reserved","OnChange","reserved","reserved","reserved","NoSigSendType","Yes","No","Default","Range","RangeSigned","ASCII","Discrete","Control","ReferencePGN","DTC","StringDelimiter","StringLength","StringLengthControl","Cyclic","OnWrite","reserved","OnChange","reserved","reserved","reserved","NoSigSendType","Yes","No","Yes","No","Default","Range","RangeSigned","ASCII","Discrete","Control","ReferencePGN","DTC","StringDelimiter","StringLength","StringLengthControl","Cyclic","OnWrite","reserved","OnChange","reserved","reserved","reserved","NoSigSendType","Yes","No","Yes","No","cyclic","reserved","cyclicIfActive","reserved","reserved","reserved","reserved","reserved","noMsgSendType";
BA_DEF_ BO_ "VFrameFormat" ENUM "Default","Range","RangeSigned","ASCII","Discrete","Control","ReferencePGN","DTC","StringDelimiter","StringLength","StringLengthControl","Default","Range","RangeSigned","ASCII","Discrete","Control","ReferencePGN","DTC","StringDelimiter","StringLength","StringLengthControl","Cyclic","OnWrite","reserved","OnChange","reserved","reserved","reserved","NoSigSendType","Default","Range","RangeSigned","ASCII","Discrete","Control","ReferencePGN","DTC","StringDelimiter","StringLength","StringLengthControl","Cyclic","OnWrite","reserved","OnChange","reserved","reserved","reserved","NoSigSendType","Yes","No","Default","Range","RangeSigned","ASCII","Discrete","Control","ReferencePGN","DTC","StringDelimiter","StringLength","StringLengthControl","Cyclic","OnWrite","reserved","OnChange","reserved","reserved","reserved","NoSigSendType","Yes","No","Yes","No","Default","Range","RangeSigned","ASCII","Discrete","Control","ReferencePGN","DTC","StringDelimiter","StringLength","StringLengthControl","Cyclic","OnWrite","reserved","OnChange","reserved","reserved","reserved","NoSigSendType","Yes","No","Yes","No","cyclic","reserved","cyclicIfActive","reserved","reserved","reserved","reserved","reserved","noMsgSendType","Default","Range","RangeSigned","ASCII","Discrete","Control","ReferencePGN","DTC","StringDelimiter","StringLength","StringLengthControl","Cyclic","OnWrite","reserved","OnChange","reserved","reserved","reserved","NoSigSendType","Yes","No","Yes","No","cyclic","reserved","cyclicIfActive","reserved","reserved","reserved","reserved","reserved","noMsgSendType","StandardCAN","ExtendedCAN","reserved","J1939PG";
BA_DEF_ BO_ "GenMsgCycleTime" INT 0 3;
BA_DEF_ SG_ "SystemSignalLongSymbol" STRING ;
BA_DEF_ BO_ "GenMsgBackgroundColor" STRING ;
BA_DEF_ BO_ "GenMsgForegroundColor" STRING ;
BA_DEF_ BO_ "matchingcriteria" INT 0 0;
BA_DEF_ BO_ "filterlabeling" INT 0 0;
BA_DEF_ BO_ "matchingcriteria" INT 0 0;
BA_DEF_ BO_ "filterlabeling" INT 0 0;
BA_DEF_DEF_ "SigType" "Default";
BA_DEF_DEF_ "GenSigStartValue" 0;
BA_DEF_DEF_ "GenSigSendType" "NoSigSendType";
BA_DEF_DEF_ "GenSigILSupport" "Yes";
BA_DEF_DEF_ "GenSigEVName" "Env";
BA_DEF_DEF_ "SPN" 0;
BA_DEF_DEF_ "GenMsgStartDelayTime" 0;
BA_DEF_DEF_ "GenMsgILSupport" "Yes";
BA_DEF_DEF_ "GenMsgRequestable" 1;
BA_DEF_DEF_ "GenMsgSendType" "noMsgSendType";
BA_DEF_DEF_ "VFrameFormat" "J1939PG";
BA_DEF_DEF_ "GenMsgCycleTime" 0;
BA_DEF_DEF_ "SystemSignalLongSymbol" "";
BA_DEF_DEF_ "GenMsgBackgroundColor" "#ffffff";
BA_DEF_DEF_ "GenMsgForegroundColor" "#000000";
BA_DEF_DEF_ "matchingcriteria" 1;
BA_DEF_DEF_ "filterlabeling" 0;
BA_DEF_DEF_ "matchingcriteria" 1;
BA_DEF_DEF_ "filterlabeling" 1;
BA_ "GenMsgSendType" BO_ 2566768382 8;
BA_ "VFrameFormat" BO_ 2566768382 3;
BA_ "GenMsgSendType" BO_ 2566811902 8;
BA_ "VFrameFormat" BO_ 2566811902 3;
BA_ "GenMsgCycleTime" BO_ 2563768062 5000;
BA_ "GenMsgSendType" BO_ 2563768062 0;
BA_ "VFrameFormat" BO_ 2563768062 3;
BA_ "GenMsgSendType" BO_ 2633924862 8;
BA_ "VFrameFormat" BO_ 2633924862 3;
BA_ "GenMsgSendType" BO_ 2633924606 8;
BA_ "VFrameFormat" BO_ 2633924606 3;
BA_ "GenMsgSendType" BO_ 2633924350 8;
BA_ "VFrameFormat" BO_ 2633924350 3;
BA_ "GenMsgSendType" BO_ 2633924094 8;
BA_ "VFrameFormat" BO_ 2633924094 3;
BA_ "GenMsgSendType" BO_ 2633923838 8;
BA_ "VFrameFormat" BO_ 2633923838 3;
BA_ "GenMsgSendType" BO_ 2633923582 8;
BA_ "VFrameFormat" BO_ 2633923582 3;
BA_ "GenMsgSendType" BO_ 2633878014 8;
BA_ "VFrameFormat" BO_ 2633878014 3;
BA_ "GenMsgSendType" BO_ 2566771966 8;
BA_ "VFrameFormat" BO_ 2566771966 3;
BA_ "GenMsgCycleTime" BO_ 2564882174 1000;
BA_ "GenMsgSendType" BO_ 2564882174 0;
BA_ "VFrameFormat" BO_ 2564882174 3;
BA_ "GenMsgSendType" BO_ 2563833598 8;
BA_ "VFrameFormat" BO_ 2563833598 3;
BA_ "GenMsgSendType" BO_ 2566843390 8;
BA_ "VFrameFormat" BO_ 2566843390 3;
BA_ "GenMsgCycleTime" BO_ 2566844926 100;
BA_ "GenMsgSendType" BO_ 2566844926 0;
BA_ "VFrameFormat" BO_ 2566844926 3;
BA_ "GenMsgSendType" BO_ 2566843902 8;
BA_ "VFrameFormat" BO_ 2566843902 3;
BA_ "GenMsgSendType" BO_ 2566809598 8;
BA_ "VFrameFormat" BO_ 2566809598 3;
BA_ "GenMsgSendType" BO_ 2633940222 8;
BA_ "VFrameFormat" BO_ 2633940222 3;
BA_ "GenMsgCycleTime" BO_ 2566775294 1000;
BA_ "GenMsgSendType" BO_ 2566775294 0;
BA_ "VFrameFormat" BO_ 2566775294 3;
BA_ "GenMsgCycleTime" BO_ 2566803710 1000;
BA_ "GenMsgSendType" BO_ 2566803710 0;
BA_ "VFrameFormat" BO_ 2566803710 3;
BA_ "VFrameFormat" BO_ 2566719486 3;
BA_ "VFrameFormat" BO_ 2633832702 3;
BA_ "VFrameFormat" BO_ 2163223550 3;
BA_ "GenMsgCycleTime" BO_ 2566714878 1000;
BA_ "GenMsgSendType" BO_ 2566714878 0;
BA_ "VFrameFormat" BO_ 2566714878 3;
BA_ "GenMsgCycleTime" BO_ 2566714622 1000;
BA_ "GenMsgSendType" BO_ 2566714622 0;
BA_ "VFrameFormat" BO_ 2566714622 3;
BA_ "GenMsgCycleTime" BO_ 2566715390 1000;
BA_ "GenMsgSendType" BO_ 2566715390 0;
BA_ "VFrameFormat" BO_ 2566715390 3;
BA_ "GenMsgCycleTime" BO_ 2566715134 1000;
BA_ "GenMsgSendType" BO_ 2566715134 0;
BA_ "VFrameFormat" BO_ 2566715134 3;
BA_ "VFrameFormat" BO_ 2365400830 3;
BA_ "VFrameFormat" BO_ 2365401342 3;
BA_ "VFrameFormat" BO_ 2365401854 3;
BA_ "VFrameFormat" BO_ 2365402366 3;
BA_ "VFrameFormat" BO_ 2365402878 3;
BA_ "VFrameFormat" BO_ 2365403390 3;
BA_ "VFrameFormat" BO_ 2365400318 3;
BA_ "GenMsgCycleTime" BO_ 2499614718 250;
BA_ "GenMsgSendType" BO_ 2499614718 0;
BA_ "VFrameFormat" BO_ 2499614718 3;
BA_ "GenMsgCycleTime" BO_ 2566722814 1000;
BA_ "GenMsgSendType" BO_ 2566722814 0;
BA_ "VFrameFormat" BO_ 2566722814 3;
BA_ "GenMsgCycleTime" BO_ 2566723070 1000;
BA_ "GenMsgSendType" BO_ 2566723070 0;
BA_ "VFrameFormat" BO_ 2566723070 3;
BA_ "VFrameFormat" BO_ 2566725118 3;
BA_ "VFrameFormat" BO_ 2566725374 3;
BA_ "GenMsgCycleTime" BO_ 2566712830 500;
BA_ "GenMsgSendType" BO_ 2566712830 0;
BA_ "VFrameFormat" BO_ 2566712830 3;
BA_ "SystemSignalLongSymbol" SG_ 2566712830 Aftrtrtmnt2WrmUpDslOxdtnCtlystOt "Aftrtrtmnt2WrmUpDslOxdtnCtlystOt";
BA_ "SystemSignalLongSymbol" SG_ 2566712830 Aftrtrtmnt2WrmUpDslOxdtnCtlystIn "Aftrtrtmnt2WrmUpDslOxdtnCtlystIn";
BA_ "GenMsgCycleTime" BO_ 2566735358 500;
BA_ "GenMsgSendType" BO_ 2566735358 0;
BA_ "VFrameFormat" BO_ 2566735358 3;
BA_ "SystemSignalLongSymbol" SG_ 2566735358 Aftrtrtmnt2ThrWyCtlytcCnvrtrDffP "Aftrtrtmnt2ThrWyCtlytcCnvrtrDffP";
BA_ "SystemSignalLongSymbol" SG_ 2566735358 Aftrtrtmnt2ThrWyCtlytcCnvrtrOtlt "Aftrtrtmnt2ThrWyCtlytcCnvrtrOtlt";
BA_ "SystemSignalLongSymbol" SG_ 2566735358 Aftrtrtmnt2ThrWyCtlytcCnvrtrIntk "Aftrtrtmnt2ThrWyCtlytcCnvrtrIntk";
BA_ "SystemSignalLongSymbol" SG_ 2566735358 Aftrtrtmnt2ThrWyCtlytcCnvrt_0000 "Aftrtrtmnt2ThrWyCtlytcCnvrt_0000";
BA_ "SystemSignalLongSymbol" SG_ 2566735358 Aftrtrtmnt2ThrWyCtlytcCnvrt_0001 "Aftrtrtmnt2ThrWyCtlytcCnvrt_0001";
BA_ "SystemSignalLongSymbol" SG_ 2566735358 Aftrtrtmnt2ThrWyCtlytcCnvrt_0002 "Aftrtrtmnt2ThrWyCtlytcCnvrt_0002";
BA_ "VFrameFormat" BO_ 2365393662 3;
BA_ "SystemSignalLongSymbol" SG_ 2365393662 Aftrtrtmnt2OtltGsNOxSnsrNH3Crrct "Aftrtrtmnt2OtltGsNOxSnsrNH3Crrct";
BA_ "SystemSignalLongSymbol" SG_ 2365393662 Aftrtrtmnt2OtltGsNOxSnsrNO2Crrct "Aftrtrtmnt2OtltGsNOxSnsrNO2Crrct";
BA_ "SystemSignalLongSymbol" SG_ 2365393662 Aftrtrtmnt2OtltGsNOxSnsrCrrctnOf "Aftrtrtmnt2OtltGsNOxSnsrCrrctnOf";
BA_ "SystemSignalLongSymbol" SG_ 2365393662 Aftrtrtmnt2OtltGsNOxSnsrCrr_0000 "Aftrtrtmnt2OtltGsNOxSnsrCrr_0000";
BA_ "VFrameFormat" BO_ 2365393918 3;
BA_ "SystemSignalLongSymbol" SG_ 2365393918 Aftrtrtmnt2OtltGsNOxSnsrNwPrtDvt "Aftrtrtmnt2OtltGsNOxSnsrNwPrtDvt";
BA_ "SystemSignalLongSymbol" SG_ 2365393918 Aftrtrtmnt2OtltGsNOxSnsrNwP_0000 "Aftrtrtmnt2OtltGsNOxSnsrNwP_0000";
BA_ "VFrameFormat" BO_ 2365394174 3;
BA_ "SystemSignalLongSymbol" SG_ 2365394174 Aftrtrtmnt2IntkGsNOxSnsrNH3Crrct "Aftrtrtmnt2IntkGsNOxSnsrNH3Crrct";
BA_ "SystemSignalLongSymbol" SG_ 2365394174 Aftrtrtmnt2IntkGsNOxSnsrNO2Crrct "Aftrtrtmnt2IntkGsNOxSnsrNO2Crrct";
BA_ "SystemSignalLongSymbol" SG_ 2365394174 Aftrtrtmnt2IntkGsNOxSnsrCrrctnOf "Aftrtrtmnt2IntkGsNOxSnsrCrrctnOf";
BA_ "SystemSignalLongSymbol" SG_ 2365394174 Aftrtrtmnt2IntkGsNOxSnsrCrr_0000 "Aftrtrtmnt2IntkGsNOxSnsrCrr_0000";
BA_ "VFrameFormat" BO_ 2365394430 3;
BA_ "SystemSignalLongSymbol" SG_ 2365394430 Aftrtrtmnt2IntkGsNOxSnsrNwPrtDvt "Aftrtrtmnt2IntkGsNOxSnsrNwPrtDvt";
BA_ "SystemSignalLongSymbol" SG_ 2365394430 Aftrtrtmnt2IntkGsNOxSnsrNwP_0000 "Aftrtrtmnt2IntkGsNOxSnsrNwP_0000";
BA_ "GenMsgCycleTime" BO_ 2566735102 500;
BA_ "GenMsgSendType" BO_ 2566735102 0;
BA_ "VFrameFormat" BO_ 2566735102 3;
BA_ "VFrameFormat" BO_ 2157313790 3;
BA_ "SystemSignalLongSymbol" SG_ 2157313790 Aftrtrtmnt2DslPrtcltFltrStStndrd "Aftrtrtmnt2DslPrtcltFltrStStndrd";
BA_ "SystemSignalLongSymbol" SG_ 2157313790 Aftrtrtmnt2DslPrtcltFltrStMnClbO "Aftrtrtmnt2DslPrtcltFltrStMnClbO";
BA_ "GenMsgCycleTime" BO_ 2566724350 500;
BA_ "GenMsgSendType" BO_ 2566724350 0;
BA_ "VFrameFormat" BO_ 2566724350 3;
BA_ "SystemSignalLongSymbol" SG_ 2566724350 Aftrtrtmnt1WrmUpDslOxdtnCtlystOt "Aftrtrtmnt1WrmUpDslOxdtnCtlystOt";
BA_ "SystemSignalLongSymbol" SG_ 2566724350 Aftrtrtmnt1WrmUpDslOxdtnCtlystIn "Aftrtrtmnt1WrmUpDslOxdtnCtlystIn";
BA_ "GenMsgCycleTime" BO_ 2566735614 500;
BA_ "GenMsgSendType" BO_ 2566735614 0;
BA_ "VFrameFormat" BO_ 2566735614 3;
BA_ "SystemSignalLongSymbol" SG_ 2566735614 Aftrtrtmnt1ThrWyCtlytcCnvrtrDffP "Aftrtrtmnt1ThrWyCtlytcCnvrtrDffP";
BA_ "SystemSignalLongSymbol" SG_ 2566735614 Aftrtrtmnt1ThrWyCtlytcCnvrtrOtlt "Aftrtrtmnt1ThrWyCtlytcCnvrtrOtlt";
BA_ "SystemSignalLongSymbol" SG_ 2566735614 Aftrtrtmnt1ThrWyCtlytcCnvrtrIntk "Aftrtrtmnt1ThrWyCtlytcCnvrtrIntk";
BA_ "SystemSignalLongSymbol" SG_ 2566735614 Aftrtrtmnt1ThrWyCtlytcCnvrt_0000 "Aftrtrtmnt1ThrWyCtlytcCnvrt_0000";
BA_ "SystemSignalLongSymbol" SG_ 2566735614 Aftrtrtmnt1ThrWyCtlytcCnvrt_0001 "Aftrtrtmnt1ThrWyCtlytcCnvrt_0001";
BA_ "SystemSignalLongSymbol" SG_ 2566735614 Aftrtrtmnt1ThrWyCtlytcCnvrt_0002 "Aftrtrtmnt1ThrWyCtlytcCnvrt_0002";
BA_ "GenMsgCycleTime" BO_ 2566805246 1000;
BA_ "GenMsgSendType" BO_ 2566805246 0;
BA_ "VFrameFormat" BO_ 2566805246 3;
BA_ "SystemSignalLongSymbol" SG_ 2566805246 Aftrtrtmnt1SCRCtlystRgntTnk1HtrP "Aftrtrtmnt1SCRCtlystRgntTnk1HtrP";
BA_ "SystemSignalLongSymbol" SG_ 2566805246 Aftrtrtmnt1SCRCtlystRgntTnk1TmpP "Aftrtrtmnt1SCRCtlystRgntTnk1TmpP";
BA_ "SystemSignalLongSymbol" SG_ 2566805246 Aftrtrtmnt1SCRCtlystTnkLvlPrlmnr "Aftrtrtmnt1SCRCtlystTnkLvlPrlmnr";
BA_ "VFrameFormat" BO_ 2365394686 3;
BA_ "SystemSignalLongSymbol" SG_ 2365394686 Aftrtrtmnt1OtltGsNOxSnsrNH3Crrct "Aftrtrtmnt1OtltGsNOxSnsrNH3Crrct";
BA_ "SystemSignalLongSymbol" SG_ 2365394686 Aftrtrtmnt1OtltGsNOxSnsrNO2Crrct "Aftrtrtmnt1OtltGsNOxSnsrNO2Crrct";
BA_ "SystemSignalLongSymbol" SG_ 2365394686 Aftrtrtmnt1OtltGsNOxSnsrCrrctnOf "Aftrtrtmnt1OtltGsNOxSnsrCrrctnOf";
BA_ "SystemSignalLongSymbol" SG_ 2365394686 Aftrtrtmnt1OtltGsNOxSnsrCrr_0000 "Aftrtrtmnt1OtltGsNOxSnsrCrr_0000";
BA_ "VFrameFormat" BO_ 2365394942 3;
BA_ "SystemSignalLongSymbol" SG_ 2365394942 Aftrtrtmnt1OtltGsNOxSnsrNwPrtDvt "Aftrtrtmnt1OtltGsNOxSnsrNwPrtDvt";
BA_ "SystemSignalLongSymbol" SG_ 2365394942 Aftrtrtmnt1OtltGsNOxSnsrNwP_0000 "Aftrtrtmnt1OtltGsNOxSnsrNwP_0000";
BA_ "VFrameFormat" BO_ 2365395198 3;
BA_ "SystemSignalLongSymbol" SG_ 2365395198 Aftrtrtmnt1IntkGsNOxSnsrNH3Crrct "Aftrtrtmnt1IntkGsNOxSnsrNH3Crrct";
BA_ "SystemSignalLongSymbol" SG_ 2365395198 Aftrtrtmnt1IntkGsNOxSnsrNO2Crrct "Aftrtrtmnt1IntkGsNOxSnsrNO2Crrct";
BA_ "SystemSignalLongSymbol" SG_ 2365395198 Aftrtrtmnt1IntkGsNOxSnsrCrrctnOf "Aftrtrtmnt1IntkGsNOxSnsrCrrctnOf";
BA_ "SystemSignalLongSymbol" SG_ 2365395198 Aftrtrtmnt1IntkGsNOxSnsrCrr_0000 "Aftrtrtmnt1IntkGsNOxSnsrCrr_0000";
BA_ "VFrameFormat" BO_ 2365395454 3;
BA_ "SystemSignalLongSymbol" SG_ 2365395454 Aftrtrtmnt1IntkGsNOxSnsrNwPrtDvt "Aftrtrtmnt1IntkGsNOxSnsrNwPrtDvt";
BA_ "SystemSignalLongSymbol" SG_ 2365395454 Aftrtrtmnt1IntkGsNOxSnsrNwP_0000 "Aftrtrtmnt1IntkGsNOxSnsrNwP_0000";
BA_ "VFrameFormat" BO_ 2157248254 3;
BA_ "SystemSignalLongSymbol" SG_ 2157248254 Aftrtrtmnt1DslPrtcltFltrStStndrd "Aftrtrtmnt1DslPrtcltFltrStStndrd";
BA_ "SystemSignalLongSymbol" SG_ 2157248254 Aftrtrtmnt1DslPrtcltFltrStMnClbO "Aftrtrtmnt1DslPrtcltFltrStMnClbO";
BA_ "GenMsgCycleTime" BO_ 2566711806 100;
BA_ "GenMsgSendType" BO_ 2566711806 0;
BA_ "VFrameFormat" BO_ 2566711806 3;
BA_ "GenMsgCycleTime" BO_ 2364549886 10;
BA_ "GenMsgSendType" BO_ 2364549886 0;
BA_ "VFrameFormat" BO_ 2364549886 3;
BA_ "GenMsgCycleTime" BO_ 2566712318 1000;
BA_ "GenMsgSendType" BO_ 2566712318 0;
BA_ "VFrameFormat" BO_ 2566712318 3;
BA_ "SystemSignalLongSymbol" SG_ 2566712318 Aftrtrtmnt2NOxAdsrbrDSOxRgnrtnSt "Aftrtrtmnt2NOxAdsrbrDSOxRgnrtnSt";
BA_ "SystemSignalLongSymbol" SG_ 2566712318 Aftrtrtmnt2NOxAdsrbrDNOxRgnrtnSt "Aftrtrtmnt2NOxAdsrbrDNOxRgnrtnSt";
BA_ "GenMsgCycleTime" BO_ 2566712574 1000;
BA_ "GenMsgSendType" BO_ 2566712574 0;
BA_ "VFrameFormat" BO_ 2566712574 3;
BA_ "SystemSignalLongSymbol" SG_ 2566712574 Aftrtrtmnt1NOxAdsrbrDSOxRgnrtnSt "Aftrtrtmnt1NOxAdsrbrDSOxRgnrtnSt";
BA_ "SystemSignalLongSymbol" SG_ 2566712574 Aftrtrtmnt1NOxAdsrbrDNOxRgnrtnSt "Aftrtrtmnt1NOxAdsrbrDNOxRgnrtnSt";
BA_ "VFrameFormat" BO_ 2164078590 3;
BA_ "SystemSignalLongSymbol" SG_ 2164078590 Aftrtrtmnt2SCRCtlystCnvrsnEffcnc "Aftrtrtmnt2SCRCtlystCnvrsnEffcnc";
BA_ "SystemSignalLongSymbol" SG_ 2164078590 Aftrtrtmnt2SCRCmddCtlystRgntCnsm "Aftrtrtmnt2SCRCmddCtlystRgntCnsm";
BA_ "SystemSignalLongSymbol" SG_ 2164078590 Aftrtrtmnt2SCRAvrgCtlystRgntCnsm "Aftrtrtmnt2SCRAvrgCtlystRgntCnsm";
BA_ "GenMsgCycleTime" BO_ 2566731006 1000;
BA_ "GenMsgSendType" BO_ 2566731006 0;
BA_ "VFrameFormat" BO_ 2566731006 3;
BA_ "SystemSignalLongSymbol" SG_ 2566731006 Aftrtrtmnt2SCRCtlystRgntTnk2HtrP "Aftrtrtmnt2SCRCtlystRgntTnk2HtrP";
BA_ "SystemSignalLongSymbol" SG_ 2566731006 Aftrtrtmnt2SCRRgntTnk2TmpPrlmnry "Aftrtrtmnt2SCRRgntTnk2TmpPrlmnry";
BA_ "SystemSignalLongSymbol" SG_ 2566731006 Aftrtrtmnt2SCRCtlystRgntTnk2LvlP "Aftrtrtmnt2SCRCtlystRgntTnk2LvlP";
BA_ "GenMsgCycleTime" BO_ 2566731262 1000;
BA_ "GenMsgSendType" BO_ 2566731262 0;
BA_ "VFrameFormat" BO_ 2566731262 3;
BA_ "SystemSignalLongSymbol" SG_ 2566731262 Aftrtrtmnt2SCRCtlystRgntTnk1HtrP "Aftrtrtmnt2SCRCtlystRgntTnk1HtrP";
BA_ "SystemSignalLongSymbol" SG_ 2566731262 Aftrtrtmnt2SCRCtlystRgntTnk1TmpP "Aftrtrtmnt2SCRCtlystRgntTnk1TmpP";
BA_ "SystemSignalLongSymbol" SG_ 2566731262 Aftrtrtmnt2SCRCtlystTnkLvlPrlmnr "Aftrtrtmnt2SCRCtlystTnkLvlPrlmnr";
BA_ "GenMsgCycleTime" BO_ 2566730750 1000;
BA_ "GenMsgSendType" BO_ 2566730750 0;
BA_ "VFrameFormat" BO_ 2566730750 3;
BA_ "SystemSignalLongSymbol" SG_ 2566730750 Aftrtrtmnt2SCRCtlystRgntTnkDrnVl "Aftrtrtmnt2SCRCtlystRgntTnkDrnVl";
BA_ "SystemSignalLongSymbol" SG_ 2566730750 Aftrtrtmnt2SCRCtlystRgntTnkFllVl "Aftrtrtmnt2SCRCtlystRgntTnkFllVl";
BA_ "SystemSignalLongSymbol" SG_ 2566730750 Aftrtrtmnt2SCRCtlystRgntPmpDrvPr "Aftrtrtmnt2SCRCtlystRgntPmpDrvPr";
BA_ "SystemSignalLongSymbol" SG_ 2566730750 Aftrtrtmnt2SCRCtlystRgntPmpMtrSp "Aftrtrtmnt2SCRCtlystRgntPmpMtrSp";
BA_ "GenMsgCycleTime" BO_ 2566731518 1000;
BA_ "GenMsgSendType" BO_ 2566731518 0;
BA_ "VFrameFormat" BO_ 2566731518 3;
BA_ "SystemSignalLongSymbol" SG_ 2566731518 Aftrtrtmnt2SCRCtlystRgntPrprtsPr "Aftrtrtmnt2SCRCtlystRgntPrprtsPr";
BA_ "SystemSignalLongSymbol" SG_ 2566731518 Aftrtrtmnt2SCRCtlystRgntTmp2Prlm "Aftrtrtmnt2SCRCtlystRgntTmp2Prlm";
BA_ "GenMsgCycleTime" BO_ 2566732030 500;
BA_ "GenMsgSendType" BO_ 2566732030 0;
BA_ "VFrameFormat" BO_ 2566732030 3;
BA_ "SystemSignalLongSymbol" SG_ 2566732030 Aftrtrtmnt2SCRCtlystOtltGsTmpPrl "Aftrtrtmnt2SCRCtlystOtltGsTmpPrl";
BA_ "SystemSignalLongSymbol" SG_ 2566732030 Aftrtrtmnt2SCRCtlystIntkGsTmpPrl "Aftrtrtmnt2SCRCtlystIntkGsTmpPrl";
BA_ "GenMsgCycleTime" BO_ 2566732286 500;
BA_ "GenMsgSendType" BO_ 2566732286 0;
BA_ "VFrameFormat" BO_ 2566732286 3;
BA_ "SystemSignalLongSymbol" SG_ 2566732286 Aftrtrtmnt2SCRCtlystExhstGsDffPr "Aftrtrtmnt2SCRCtlystExhstGsDffPr";
BA_ "SystemSignalLongSymbol" SG_ 2566732286 Aftrtrtmnt2SCRCtlystExhstGs_0000 "Aftrtrtmnt2SCRCtlystExhstGs_0000";
BA_ "GenMsgCycleTime" BO_ 2164079358 500;
BA_ "GenMsgSendType" BO_ 2164079358 0;
BA_ "VFrameFormat" BO_ 2164079358 3;
BA_ "GenMsgCycleTime" BO_ 2364549118 50;
BA_ "GenMsgSendType" BO_ 2364549118 0;
BA_ "VFrameFormat" BO_ 2364549118 3;
BA_ "SystemSignalLongSymbol" SG_ 2364549118 Aftrtrtmnt2SCRRqdRgntQnttyFrIntg "Aftrtrtmnt2SCRRqdRgntQnttyFrIntg";
BA_ "GenMsgCycleTime" BO_ 2566732798 500;
BA_ "GenMsgSendType" BO_ 2566732798 0;
BA_ "VFrameFormat" BO_ 2566732798 3;
BA_ "SystemSignalLongSymbol" SG_ 2566732798 Aftrtrtmnt2SCRCtlystRgntLnHtr4Pr "Aftrtrtmnt2SCRCtlystRgntLnHtr4Pr";
BA_ "SystemSignalLongSymbol" SG_ 2566732798 Aftrtrtmnt2SCRCtlystRgntLnHtr4St "Aftrtrtmnt2SCRCtlystRgntLnHtr4St";
BA_ "SystemSignalLongSymbol" SG_ 2566732798 Aftrtrtmnt2SCRCtlystRgntLnHtr3Pr "Aftrtrtmnt2SCRCtlystRgntLnHtr3Pr";
BA_ "SystemSignalLongSymbol" SG_ 2566732798 Aftrtrtmnt2SCRCtlystRgntLnHtr3St "Aftrtrtmnt2SCRCtlystRgntLnHtr3St";
BA_ "SystemSignalLongSymbol" SG_ 2566732798 Aftrtrtmnt2SCRCtlystRgntLnHtr2Pr "Aftrtrtmnt2SCRCtlystRgntLnHtr2Pr";
BA_ "SystemSignalLongSymbol" SG_ 2566732798 Aftrtrtmnt2SCRCtlystRgntLnHtr2St "Aftrtrtmnt2SCRCtlystRgntLnHtr2St";
BA_ "SystemSignalLongSymbol" SG_ 2566732798 Aftrtrtmnt2SCRCtlystRgntLnHtr1Pr "Aftrtrtmnt2SCRCtlystRgntLnHtr1Pr";
BA_ "SystemSignalLongSymbol" SG_ 2566732798 Aftrtrtmnt2SCRCtlystRgntLnHtr1St "Aftrtrtmnt2SCRCtlystRgntLnHtr1St";
BA_ "SystemSignalLongSymbol" SG_ 2566732798 Aftrtrtmnt2SCRDsngVlvExhstTmpRdc "Aftrtrtmnt2SCRDsngVlvExhstTmpRdc";
BA_ "GenMsgCycleTime" BO_ 2364548862 50;
BA_ "GenMsgSendType" BO_ 2364548862 0;
BA_ "VFrameFormat" BO_ 2364548862 3;
BA_ "SystemSignalLongSymbol" SG_ 2364548862 Aftrtrtmnt2SCRActlRgntQnttyOfInt "Aftrtrtmnt2SCRActlRgntQnttyOfInt";
BA_ "GenMsgCycleTime" BO_ 2364549374 50;
BA_ "GenMsgSendType" BO_ 2364549374 0;
BA_ "VFrameFormat" BO_ 2364549374 3;
BA_ "SystemSignalLongSymbol" SG_ 2364549374 Aftrtrtmnt2OtltNH3GsSnsrHtrPrlmn "Aftrtrtmnt2OtltNH3GsSnsrHtrPrlmn";
BA_ "GenMsgCycleTime" BO_ 2566726142 500;
BA_ "GenMsgSendType" BO_ 2566726142 0;
BA_ "VFrameFormat" BO_ 2566726142 3;
BA_ "SystemSignalLongSymbol" SG_ 2566726142 Aftrtrtmnt2GsOxdtnCtlystDffPrssP "Aftrtrtmnt2GsOxdtnCtlystDffPrssP";
BA_ "SystemSignalLongSymbol" SG_ 2566726142 Aftrtrtmnt2GsOxdtnCtlystOtltGsTm "Aftrtrtmnt2GsOxdtnCtlystOtltGsTm";
BA_ "SystemSignalLongSymbol" SG_ 2566726142 Aftrtrtmnt2GsOxdtnCtlystIntkGsTm "Aftrtrtmnt2GsOxdtnCtlystIntkGsTm";
BA_ "SystemSignalLongSymbol" SG_ 2566726142 Aftrtrtmnt2GsOxdtnCtlystOtl_0000 "Aftrtrtmnt2GsOxdtnCtlystOtl_0000";
BA_ "SystemSignalLongSymbol" SG_ 2566726142 Aftrtrtmnt2GsOxdtnCtlystInt_0000 "Aftrtrtmnt2GsOxdtnCtlystInt_0000";
BA_ "GenMsgCycleTime" BO_ 2566725630 500;
BA_ "GenMsgSendType" BO_ 2566725630 0;
BA_ "VFrameFormat" BO_ 2566725630 3;
BA_ "SystemSignalLongSymbol" SG_ 2566725630 Aftrtrtmnt2DslOxdtnCtlystOtltGsT "Aftrtrtmnt2DslOxdtnCtlystOtltGsT";
BA_ "SystemSignalLongSymbol" SG_ 2566725630 Aftrtrtmnt2DslOxdtnCtlystIntkGsT "Aftrtrtmnt2DslOxdtnCtlystIntkGsT";
BA_ "SystemSignalLongSymbol" SG_ 2566725630 Aftrtrtmnt2DslOxdtnCtlystOt_0000 "Aftrtrtmnt2DslOxdtnCtlystOt_0000";
BA_ "SystemSignalLongSymbol" SG_ 2566725630 Aftrtrtmnt2DslOxdtnCtlystIn_0000 "Aftrtrtmnt2DslOxdtnCtlystIn_0000";
BA_ "SystemSignalLongSymbol" SG_ 2566725630 Aftrtrtmnt2DslOxdtnCtlystDf_0000 "Aftrtrtmnt2DslOxdtnCtlystDf_0000";
BA_ "GenMsgCycleTime" BO_ 2566733310 1000;
BA_ "GenMsgSendType" BO_ 2566733310 0;
BA_ "VFrameFormat" BO_ 2566733310 3;
BA_ "SystemSignalLongSymbol" SG_ 2566733310 Aftrtrtmnt1SCRCtlystRgntTnk2HtrP "Aftrtrtmnt1SCRCtlystRgntTnk2HtrP";
BA_ "SystemSignalLongSymbol" SG_ 2566733310 Aftrtrtmnt1SCRRgntTnk2TmpPrlmnry "Aftrtrtmnt1SCRRgntTnk2TmpPrlmnry";
BA_ "SystemSignalLongSymbol" SG_ 2566733310 Aftrtrtmnt1SCRCtlystRgntTnk2LvlP "Aftrtrtmnt1SCRCtlystRgntTnk2LvlP";
BA_ "GenMsgCycleTime" BO_ 2566733054 1000;
BA_ "GenMsgSendType" BO_ 2566733054 0;
BA_ "VFrameFormat" BO_ 2566733054 3;
BA_ "SystemSignalLongSymbol" SG_ 2566733054 Aftrtrtmnt1SCRCtlystRgntTnkDrnVl "Aftrtrtmnt1SCRCtlystRgntTnkDrnVl";
BA_ "SystemSignalLongSymbol" SG_ 2566733054 Aftrtrtmnt1SCRCtlystRgntTnkFllVl "Aftrtrtmnt1SCRCtlystRgntTnkFllVl";
BA_ "SystemSignalLongSymbol" SG_ 2566733054 Aftrtrtmnt1SCRCtlystRgntPmpDrvPr "Aftrtrtmnt1SCRCtlystRgntPmpDrvPr";
BA_ "SystemSignalLongSymbol" SG_ 2566733054 Aftrtrtmnt1SCRCtlystRgntPmpMtrSp "Aftrtrtmnt1SCRCtlystRgntPmpMtrSp";
BA_ "GenMsgCycleTime" BO_ 2499624702 500;
BA_ "GenMsgSendType" BO_ 2499624702 0;
BA_ "VFrameFormat" BO_ 2499624702 3;
BA_ "SystemSignalLongSymbol" SG_ 2499624702 Aftrtrtmnt1SCRCtlystOtltGsTmpPrl "Aftrtrtmnt1SCRCtlystOtltGsTmpPrl";
BA_ "SystemSignalLongSymbol" SG_ 2499624702 Aftrtrtmnt1SCRCtlystIntkGsTmpPrl "Aftrtrtmnt1SCRCtlystIntkGsTmpPrl";
BA_ "GenMsgCycleTime" BO_ 2566733822 500;
BA_ "GenMsgSendType" BO_ 2566733822 0;
BA_ "VFrameFormat" BO_ 2566733822 3;
BA_ "SystemSignalLongSymbol" SG_ 2566733822 Aftrtrtmnt1SCRCtlystExhstGsDffPr "Aftrtrtmnt1SCRCtlystExhstGsDffPr";
BA_ "SystemSignalLongSymbol" SG_ 2566733822 Aftrtrtmnt1SCRCtlystExhstGs_0000 "Aftrtrtmnt1SCRCtlystExhstGs_0000";
BA_ "GenMsgCycleTime" BO_ 2566734078 500;
BA_ "GenMsgSendType" BO_ 2566734078 0;
BA_ "VFrameFormat" BO_ 2566734078 3;
BA_ "GenMsgCycleTime" BO_ 2364548350 50;
BA_ "GenMsgSendType" BO_ 2364548350 0;
BA_ "VFrameFormat" BO_ 2364548350 3;
BA_ "SystemSignalLongSymbol" SG_ 2364548350 Aftrtrtmnt1SCRRqdRgntQnttyFrIntg "Aftrtrtmnt1SCRRqdRgntQnttyFrIntg";
BA_ "GenMsgCycleTime" BO_ 2566734334 500;
BA_ "GenMsgSendType" BO_ 2566734334 0;
BA_ "VFrameFormat" BO_ 2566734334 3;
BA_ "SystemSignalLongSymbol" SG_ 2566734334 Aftrtrtmnt1SCRCtlystRgntLnHtr4Pr "Aftrtrtmnt1SCRCtlystRgntLnHtr4Pr";
BA_ "SystemSignalLongSymbol" SG_ 2566734334 Aftrtrtmnt1SCRCtlystRgntLnHtr4St "Aftrtrtmnt1SCRCtlystRgntLnHtr4St";
BA_ "SystemSignalLongSymbol" SG_ 2566734334 Aftrtrtmnt1SCRCtlystRgntLnHtr3Pr "Aftrtrtmnt1SCRCtlystRgntLnHtr3Pr";
BA_ "SystemSignalLongSymbol" SG_ 2566734334 Aftrtrtmnt1SCRCtlystRgntLnHtr3St "Aftrtrtmnt1SCRCtlystRgntLnHtr3St";
BA_ "SystemSignalLongSymbol" SG_ 2566734334 Aftrtrtmnt1SCRCtlystRgntLnHtr2Pr "Aftrtrtmnt1SCRCtlystRgntLnHtr2Pr";
BA_ "SystemSignalLongSymbol" SG_ 2566734334 Aftrtrtmnt1SCRCtlystRgntLnHtr2St "Aftrtrtmnt1SCRCtlystRgntLnHtr2St";
BA_ "SystemSignalLongSymbol" SG_ 2566734334 Aftrtrtmnt1SCRCtlystRgntLnHtr1Pr "Aftrtrtmnt1SCRCtlystRgntLnHtr1Pr";
BA_ "SystemSignalLongSymbol" SG_ 2566734334 Aftrtrtmnt1SCRCtlystRgntLnHtr1St "Aftrtrtmnt1SCRCtlystRgntLnHtr1St";
BA_ "SystemSignalLongSymbol" SG_ 2566734334 Aftrtrtmnt1SCRDsngVlvExhstTmpRdc "Aftrtrtmnt1SCRDsngVlvExhstTmpRdc";
BA_ "GenMsgCycleTime" BO_ 2364548094 50;
BA_ "GenMsgSendType" BO_ 2364548094 0;
BA_ "VFrameFormat" BO_ 2364548094 3;
BA_ "SystemSignalLongSymbol" SG_ 2364548094 Aftrtrtmnt1SCRActlRgntQnttyOfInt "Aftrtrtmnt1SCRActlRgntQnttyOfInt";
BA_ "GenMsgCycleTime" BO_ 2364548606 50;
BA_ "GenMsgSendType" BO_ 2364548606 0;
BA_ "VFrameFormat" BO_ 2364548606 3;
BA_ "SystemSignalLongSymbol" SG_ 2364548606 Aftrtrtmnt1OtltNH3GsSnsrHtrPrlmn "Aftrtrtmnt1OtltNH3GsSnsrHtrPrlmn";
BA_ "GenMsgCycleTime" BO_ 2566726398 500;
BA_ "GenMsgSendType" BO_ 2566726398 0;
BA_ "VFrameFormat" BO_ 2566726398 3;
BA_ "SystemSignalLongSymbol" SG_ 2566726398 Aftrtrtmnt1GsOxdtnCtlystDffPrssP "Aftrtrtmnt1GsOxdtnCtlystDffPrssP";
BA_ "SystemSignalLongSymbol" SG_ 2566726398 Aftrtrtmnt1GsOxdtnCtlystOtltGsTm "Aftrtrtmnt1GsOxdtnCtlystOtltGsTm";
BA_ "SystemSignalLongSymbol" SG_ 2566726398 Aftrtrtmnt1GsOxdtnCtlystIntkGsTm "Aftrtrtmnt1GsOxdtnCtlystIntkGsTm";
BA_ "SystemSignalLongSymbol" SG_ 2566726398 Aftrtrtmnt1GsOxdtnCtlystOtl_0000 "Aftrtrtmnt1GsOxdtnCtlystOtl_0000";
BA_ "SystemSignalLongSymbol" SG_ 2566726398 Aftrtrtmnt1GsOxdtnCtlystInt_0000 "Aftrtrtmnt1GsOxdtnCtlystInt_0000";
BA_ "VFrameFormat" BO_ 2566742270 3;
BA_ "VFrameFormat" BO_ 2566742526 3;
BA_ "VFrameFormat" BO_ 2566742782 3;
BA_ "VFrameFormat" BO_ 2566743038 3;
BA_ "VFrameFormat" BO_ 2566743294 3;
BA_ "VFrameFormat" BO_ 2560687870 3;
BA_ "VFrameFormat" BO_ 2292317950 3;
BA_ "GenMsgCycleTime" BO_ 2566809342 1000;
BA_ "GenMsgSendType" BO_ 2566809342 0;
BA_ "VFrameFormat" BO_ 2566809342 3;
BA_ "GenMsgCycleTime" BO_ 2365446910 100;
BA_ "GenMsgSendType" BO_ 2365446910 0;
BA_ "VFrameFormat" BO_ 2365446910 3;
BA_ "GenMsgCycleTime" BO_ 2365446398 100;
BA_ "GenMsgSendType" BO_ 2365446398 0;
BA_ "VFrameFormat" BO_ 2365446398 3;
BA_ "GenMsgCycleTime" BO_ 2365445886 100;
BA_ "GenMsgSendType" BO_ 2365445886 0;
BA_ "VFrameFormat" BO_ 2365445886 3;
BA_ "GenMsgCycleTime" BO_ 2566847230 1000;
BA_ "GenMsgSendType" BO_ 2566847230 0;
BA_ "VFrameFormat" BO_ 2566847230 3;
BA_ "GenMsgCycleTime" BO_ 2566848254 1000;
BA_ "GenMsgSendType" BO_ 2566848254 0;
BA_ "VFrameFormat" BO_ 2566848254 3;
BA_ "GenMsgCycleTime" BO_ 2566725886 500;
BA_ "GenMsgSendType" BO_ 2566725886 0;
BA_ "VFrameFormat" BO_ 2566725886 3;
BA_ "SystemSignalLongSymbol" SG_ 2566725886 Aftrtrtmnt1DslOxdtnCtlystDf_0000 "Aftrtrtmnt1DslOxdtnCtlystDf_0000";
BA_ "SystemSignalLongSymbol" SG_ 2566725886 Aftrtrtmnt1DslOxdtnCtlystOtltGsT "Aftrtrtmnt1DslOxdtnCtlystOtltGsT";
BA_ "SystemSignalLongSymbol" SG_ 2566725886 Aftrtrtmnt1DslOxdtnCtlystIntkGsT "Aftrtrtmnt1DslOxdtnCtlystIntkGsT";
BA_ "SystemSignalLongSymbol" SG_ 2566725886 Aftrtrtmnt1DslOxdtnCtlystOt_0000 "Aftrtrtmnt1DslOxdtnCtlystOt_0000";
BA_ "SystemSignalLongSymbol" SG_ 2566725886 Aftrtrtmnt1DslOxdtnCtlystIn_0000 "Aftrtrtmnt1DslOxdtnCtlystIn_0000";
BA_ "VFrameFormat" BO_ 2560884478 3;
BA_ "VFrameFormat" BO_ 2633844734 3;
BA_ "VFrameFormat" BO_ 2560360190 3;
BA_ "VFrameFormat" BO_ 2566736126 3;
BA_ "SystemSignalLongSymbol" SG_ 2566736126 EngExhstGsOxygnSnsrClsdLpOprtnBn "EngExhstGsOxygnSnsrClsdLpOprtnBn";
BA_ "VFrameFormat" BO_ 2566736382 3;
BA_ "SystemSignalLongSymbol" SG_ 2566736382 EngExhstGsOxygnSnsrClsdLpOp_0000 "EngExhstGsOxygnSnsrClsdLpOp_0000";
BA_ "VFrameFormat" BO_ 2565874174 3;
BA_ "GenMsgCycleTime" BO_ 2432520958 1000;
BA_ "VFrameFormat" BO_ 2432520958 3;
BA_ "VFrameFormat" BO_ 2560425726 3;
BA_ "VFrameFormat" BO_ 2560491262 3;
BA_ "VFrameFormat" BO_ 2349399806 3;
BA_ "GenMsgCycleTime" BO_ 2566758398 500;
BA_ "GenMsgSendType" BO_ 2566758398 0;
BA_ "VFrameFormat" BO_ 2566758398 3;
BA_ "GenMsgCycleTime" BO_ 2566745598 500;
BA_ "GenMsgSendType" BO_ 2566745598 0;
BA_ "VFrameFormat" BO_ 2566745598 3;
BA_ "GenMsgCycleTime" BO_ 2566758910 500;
BA_ "GenMsgSendType" BO_ 2566758910 0;
BA_ "VFrameFormat" BO_ 2566758910 3;
BA_ "GenMsgCycleTime" BO_ 2566743550 500;
BA_ "GenMsgSendType" BO_ 2566743550 0;
BA_ "VFrameFormat" BO_ 2566743550 3;
BA_ "GenMsgCycleTime" BO_ 2566753534 500;
BA_ "GenMsgSendType" BO_ 2566753534 0;
BA_ "VFrameFormat" BO_ 2566753534 3;
BA_ "VFrameFormat" BO_ 2566756606 3;
BA_ "SystemSignalLongSymbol" SG_ 2566756606 Aftrtrtmnt1TtlNmbrOfActvRgnrtnMn "Aftrtrtmnt1TtlNmbrOfActvRgnrtnMn";
BA_ "SystemSignalLongSymbol" SG_ 2566756606 Aftrtrtmnt1TtlNmbrOfActvRgnrtnIn "Aftrtrtmnt1TtlNmbrOfActvRgnrtnIn";
BA_ "GenMsgCycleTime" BO_ 2565869310 50;
BA_ "GenMsgSendType" BO_ 2565869310 0;
BA_ "VFrameFormat" BO_ 2565869310 3;
BA_ "SystemSignalLongSymbol" SG_ 2565869310 Aftrtrtmnt1IntkOxygnSnsrPrlmnryF "Aftrtrtmnt1IntkOxygnSnsrPrlmnryF";
BA_ "SystemSignalLongSymbol" SG_ 2565869310 Aftrtrtmnt1IntkGsSnsrHtrPrlmnryF "Aftrtrtmnt1IntkGsSnsrHtrPrlmnryF";
BA_ "GenMsgCycleTime" BO_ 2566763774 500;
BA_ "GenMsgSendType" BO_ 2566763774 0;
BA_ "VFrameFormat" BO_ 2566763774 3;
BA_ "SystemSignalLongSymbol" SG_ 2566763774 Aftrtrtmnt1DslPrtcltFltrIntkGsTm "Aftrtrtmnt1DslPrtcltFltrIntkGsTm";
BA_ "SystemSignalLongSymbol" SG_ 2566763774 Aftrtrtmnt1DslPrtcltFltrInt_0000 "Aftrtrtmnt1DslPrtcltFltrInt_0000";
BA_ "GenMsgSendType" BO_ 2631728894 8;
BA_ "VFrameFormat" BO_ 2631728894 3;
BA_ "GenMsgSendType" BO_ 2631794430 8;
BA_ "VFrameFormat" BO_ 2631794430 3;
BA_ "GenMsgCycleTime" BO_ 2633934846 1000;
BA_ "GenMsgSendType" BO_ 2633934846 0;
BA_ "VFrameFormat" BO_ 2633934846 3;
BA_ "GenMsgCycleTime" BO_ 2362572542 100;
BA_ "GenMsgSendType" BO_ 2362572542 2;
BA_ "VFrameFormat" BO_ 2362572542 3;
BA_ "GenMsgCycleTime" BO_ 2365478910 100;
BA_ "GenMsgSendType" BO_ 2365478910 0;
BA_ "VFrameFormat" BO_ 2365478910 3;
BA_ "VFrameFormat" BO_ 2560950014 3;
BA_ "GenMsgCycleTime" BO_ 2566763262 500;
BA_ "GenMsgSendType" BO_ 2566763262 0;
BA_ "VFrameFormat" BO_ 2566763262 3;
BA_ "SystemSignalLongSymbol" SG_ 2566763262 Aftrtrtmnt1DslPrtcltFltrIntrmdtG "Aftrtrtmnt1DslPrtcltFltrIntrmdtG";
BA_ "SystemSignalLongSymbol" SG_ 2566763262 Aftrtrtmnt1DslPrtcltFltrInt_0001 "Aftrtrtmnt1DslPrtcltFltrInt_0001";
BA_ "SystemSignalLongSymbol" SG_ 2566763262 Aftrtrtmnt1DslPrtcltFltrDltPrssP "Aftrtrtmnt1DslPrtcltFltrDltPrssP";
BA_ "GenMsgCycleTime" BO_ 2565869566 50;
BA_ "GenMsgSendType" BO_ 2565869566 0;
BA_ "VFrameFormat" BO_ 2565869566 3;
BA_ "SystemSignalLongSymbol" SG_ 2565869566 Aftrtrtmnt1OtltOxygnSnsrPrlmnryF "Aftrtrtmnt1OtltOxygnSnsrPrlmnryF";
BA_ "SystemSignalLongSymbol" SG_ 2565869566 Aftrtrtmnt1OtltGsSnsrHtrPrlmnryF "Aftrtrtmnt1OtltGsSnsrHtrPrlmnryF";
BA_ "GenMsgCycleTime" BO_ 2566763518 500;
BA_ "GenMsgSendType" BO_ 2566763518 0;
BA_ "VFrameFormat" BO_ 2566763518 3;
BA_ "SystemSignalLongSymbol" SG_ 2566763518 Aftrtrtmnt1DslPrtcltFltrOtltGsTm "Aftrtrtmnt1DslPrtcltFltrOtltGsTm";
BA_ "SystemSignalLongSymbol" SG_ 2566763518 Aftrtrtmnt1DslPrtcltFltrOtltExhs "Aftrtrtmnt1DslPrtcltFltrOtltExhs";
BA_ "VFrameFormat" BO_ 2566749182 3;
BA_ "SystemSignalLongSymbol" SG_ 2566749182 Aftrtrtmnt1DslPrtcltFltrStLdRgnr "Aftrtrtmnt1DslPrtcltFltrStLdRgnr";
BA_ "VFrameFormat" BO_ 2566748670 3;
BA_ "SystemSignalLongSymbol" SG_ 2566748670 Aftrtrtmnt1TrpNmbrOfActvRgnrtnMn "Aftrtrtmnt1TrpNmbrOfActvRgnrtnMn";
BA_ "SystemSignalLongSymbol" SG_ 2566748670 Aftrtrtmnt1TrpNmbrOfActvRgnrtnIn "Aftrtrtmnt1TrpNmbrOfActvRgnrtnIn";
BA_ "GenMsgCycleTime" BO_ 2566758142 500;
BA_ "GenMsgSendType" BO_ 2566758142 0;
BA_ "VFrameFormat" BO_ 2566758142 3;
BA_ "GenMsgCycleTime" BO_ 2566745342 500;
BA_ "GenMsgSendType" BO_ 2566745342 0;
BA_ "VFrameFormat" BO_ 2566745342 3;
BA_ "GenMsgCycleTime" BO_ 2566758654 500;
BA_ "GenMsgSendType" BO_ 2566758654 0;
BA_ "VFrameFormat" BO_ 2566758654 3;
BA_ "GenMsgCycleTime" BO_ 2566753278 500;
BA_ "GenMsgSendType" BO_ 2566753278 0;
BA_ "VFrameFormat" BO_ 2566753278 3;
BA_ "VFrameFormat" BO_ 2566756862 3;
BA_ "SystemSignalLongSymbol" SG_ 2566756862 Aftrtrtmnt2TtlNmbrOfActvRgnrtnMn "Aftrtrtmnt2TtlNmbrOfActvRgnrtnMn";
BA_ "SystemSignalLongSymbol" SG_ 2566756862 Aftrtrtmnt2TtlNmbrOfActvRgnrtnIn "Aftrtrtmnt2TtlNmbrOfActvRgnrtnIn";
BA_ "GenMsgCycleTime" BO_ 2565869822 50;
BA_ "GenMsgSendType" BO_ 2565869822 0;
BA_ "VFrameFormat" BO_ 2565869822 3;
BA_ "SystemSignalLongSymbol" SG_ 2565869822 Aftrtrtmnt2IntkOxygnSnsrPrlmnryF "Aftrtrtmnt2IntkOxygnSnsrPrlmnryF";
BA_ "SystemSignalLongSymbol" SG_ 2565869822 Aftrtrtmnt2IntkGsSnsrHtrPrlmnryF "Aftrtrtmnt2IntkGsSnsrHtrPrlmnryF";
BA_ "GenMsgCycleTime" BO_ 2566763006 500;
BA_ "GenMsgSendType" BO_ 2566763006 0;
BA_ "VFrameFormat" BO_ 2566763006 3;
BA_ "SystemSignalLongSymbol" SG_ 2566763006 Aftrtrtmnt2DslPrtcltFltrIntkGsTm "Aftrtrtmnt2DslPrtcltFltrIntkGsTm";
BA_ "SystemSignalLongSymbol" SG_ 2566763006 Aftrtrtmnt2DslPrtcltFltrInt_0000 "Aftrtrtmnt2DslPrtcltFltrInt_0000";
BA_ "GenMsgCycleTime" BO_ 2566762494 500;
BA_ "GenMsgSendType" BO_ 2566762494 0;
BA_ "VFrameFormat" BO_ 2566762494 3;
BA_ "SystemSignalLongSymbol" SG_ 2566762494 Aftrtrtmnt2DslPrtcltFltrIntrmdtG "Aftrtrtmnt2DslPrtcltFltrIntrmdtG";
BA_ "SystemSignalLongSymbol" SG_ 2566762494 Aftrtrtmnt2DslPrtcltFltrInt_0001 "Aftrtrtmnt2DslPrtcltFltrInt_0001";
BA_ "SystemSignalLongSymbol" SG_ 2566762494 Aftrtrtmnt2DslPrtcltFltrDltPrssP "Aftrtrtmnt2DslPrtcltFltrDltPrssP";
BA_ "GenMsgCycleTime" BO_ 2565870078 50;
BA_ "GenMsgSendType" BO_ 2565870078 0;
BA_ "VFrameFormat" BO_ 2565870078 3;
BA_ "SystemSignalLongSymbol" SG_ 2565870078 Aftrtrtmnt2OtltOxygnSnsrPrlmnryF "Aftrtrtmnt2OtltOxygnSnsrPrlmnryF";
BA_ "SystemSignalLongSymbol" SG_ 2565870078 Aftrtrtmnt2OtltGsSnsrHtrPrlmnryF "Aftrtrtmnt2OtltGsSnsrHtrPrlmnryF";
BA_ "GenMsgCycleTime" BO_ 2566762750 500;
BA_ "GenMsgSendType" BO_ 2566762750 0;
BA_ "VFrameFormat" BO_ 2566762750 3;
BA_ "SystemSignalLongSymbol" SG_ 2566762750 Aftrtrtmnt2DslPrtcltFltrOtltGsTm "Aftrtrtmnt2DslPrtcltFltrOtltGsTm";
BA_ "SystemSignalLongSymbol" SG_ 2566762750 Aftrtrtmnt2DslPrtcltFltrExhstGsT "Aftrtrtmnt2DslPrtcltFltrExhstGsT";
BA_ "VFrameFormat" BO_ 2566748926 3;
BA_ "SystemSignalLongSymbol" SG_ 2566748926 Aftrtrtmnt2DslPrtcltFltrStLdRgnr "Aftrtrtmnt2DslPrtcltFltrStLdRgnr";
BA_ "VFrameFormat" BO_ 2566748414 3;
BA_ "SystemSignalLongSymbol" SG_ 2566748414 Aftrtrtmnt2TrpNmbrOfActvRgnrtnMn "Aftrtrtmnt2TrpNmbrOfActvRgnrtnMn";
BA_ "SystemSignalLongSymbol" SG_ 2566748414 Aftrtrtmnt2TrpNmbrOfActvRgnrtnIn "Aftrtrtmnt2TrpNmbrOfActvRgnrtnIn";
BA_ "GenMsgCycleTime" BO_ 2365428478 250;
BA_ "VFrameFormat" BO_ 2365428478 3;
BA_ "GenMsgCycleTime" BO_ 2566743806 1000;
BA_ "GenMsgSendType" BO_ 2566743806 0;
BA_ "VFrameFormat" BO_ 2566743806 3;
BA_ "VFrameFormat" BO_ 2499635454 3;
BA_ "GenMsgCycleTime" BO_ 2550660862 100;
BA_ "VFrameFormat" BO_ 2550660862 3;
VAL_ 2566768382 EngStartEnableDevice2Config 15 "NotAvailable" 5 "1110Reserved" 4 "ElctricIntakeAirHeaterInstalled" 3 "EtherInjectionInstalled" 2 "FuelledStartInstalled" 1 "GlowPlugsInstalled" 0 "NoStartEnableDevice2Installed";
VAL_ 2566768382 EngStartEnableDevice1Config 15 "NotAvailable" 5 "1110Reserved" 4 "ElctricIntakeAirHeaterInstalled" 3 "EtherInjectionInstalled" 2 "FuelledStartInstalled" 1 "GlowPlugsInstalled" 0 "NoStartEnableDevice1Installed";
VAL_ 2566768382 EngStartEnableDevice2 3 "NotAvailable" 2 "Reserved" 1 "StartEnableON" 0 "StartEnableOFF";
VAL_ 2566768382 EngStartEnableDevice1 3 "NotAvailable" 2 "Reserved" 1 "StartEnableON" 0 "StartEnableOFF";
VAL_ 2566771966 TransOilLevelRq 3 "DontCare_TakeNoAction" 2 "Reserved" 1 "TransOilLevelReadingDesired" 0 "NoTransOilLevelReadingDesired";
VAL_ 2566771966 FifthWheelReleaseCtrl 3 "NotAvailable" 2 "Error" 1 "CplrUnlckdTrlrCnBUnhtchdHitched" 0 "CouplerLocked";
VAL_ 2566771966 FfthWhlRlaseCtrlSecurityLockout 3 "NotAvailable" 2 "Error" 1 "FifthWheelReleaseEnabled" 0 "FifthWheelReleaseDisabled";
VAL_ 2566771966 TransferCaseSelectorSwitch 7 "NotAvailable" 5 "ReservedForSAEAssignment" 4 "4WheelLow" 0 "2WheelHigh" 6 "ErrorIndicator" 3 "2WheelLow" 2 "Neutral" 1 "4WheelHigh";
VAL_ 2564882174 DslPrtcltFltrRgnrtonForceSwitch 3 "notAvailable" 2 "error" 1 "active" 0 "notActive";
VAL_ 2564882174 DslPrtcltFltrRgnrtnInhbitSwitch 3 "notAvailable" 2 "error" 1 "active" 0 "notActive";
VAL_ 2564882174 SelectedMaxVehicleSpeedLimit 0 "sUsdTIndctThtAMxVhclSpdIsNtSlct";
VAL_ 2564882174 RqCabZoneHeating 3 "DontCare_TakeNoAction" 2 "Reserved" 1 "HeatCabZone" 0 "DoNotCabEngZone";
VAL_ 2564882174 RqEngZoneHeating 3 "DontCare_TakeNoAction" 2 "Reserved" 1 "HeatEngZone" 0 "DoNotHeatEngZone";
VAL_ 2564882174 AuxHeaterModeRq 15 "DontCare_TakeNoAction" 14 "Reserved" 4 "1101NotDefined" 3 "NormalMode" 2 "EconomyMode" 1 "OffDTADRPrErpnRgltnsFrTrnsprtOf" 0 "DeactivateAuxHeater";
VAL_ 2564882174 EngAutomaticStartEnableSwitch 3 "NotAvailable" 2 "Error" 1 "SwitchInOnState" 0 "SwitchInOffState";
VAL_ 2564882174 AtmaticGearShiftingEnableSwitch 3 "NotAvailable" 2 "Error" 1 "AutomatedGearShiftingIsEnabled" 0 "AutomatedGearShiftingIsDisabled";
VAL_ 2564882174 VhclLmtngSpdGvernorEnableSwitch 3 "NotAvailable" 2 "Error" 1 "SwitchedEnabled" 0 "SwitchDisabled";
VAL_ 2564882174 VhclLmtngSpdGvrnrIncrmentSwitch 3 "NotAvailable" 2 "Error" 1 "SwitchInOnStateIncrease" 0 "SwitchInOffState";
VAL_ 2564882174 VhclLmtngSpdGvrnrDcrementSwitch 3 "NotAvailable" 2 "Error" 1 "SwitchInOnStateDecrease" 0 "SwitchInOffState";
VAL_ 2564882174 SeatBeltSwitch 3 "NotAvailable" 2 "ErrrSwtchStteCannotBeDetermined" 1 "OKSeatBeltIsBuckled" 0 "NOTBuckled";
VAL_ 2564882174 OperatorSeatDirectionSwitch 3 "NotAvailable" 2 "Error" 1 "OperatorSeatIsFacingForward" 0 "OperatorSeatNotFacingForward";
VAL_ 2564882174 BatteryMainSwitchHoldRq 3 "DontCare_TakeNoAction" 2 "undefined" 1 "HoldBatteryMainSwitch" 0 "ReleaseBatteryMainSwitch";
VAL_ 2564882174 AuxHeaterCoolantPumpRq 3 "DontCare_TakeNoAction" 2 "Reserved" 1 "ActivateWaterPump" 0 "DeactivateWaterPump";
VAL_ 2566844926 ParkBrakeReleaseInhibitRq 3 "Unavailable" 2 "SAEReserved" 1 "ParkBrakeReleaseInhibitRqed" 0 "ParkBrakeReleaseInhibitNotRqed";
VAL_ 2566844926 PTOGovernorState 31 "NotAvailable" 20 "11110NotDefined" 19 "PTOSetSpeedMemory2" 18 "PTOSetSpeedMemory1" 17 "PreprogrammedSetSpeed8" 16 "PreprogrammedSetSpeed7" 15 "PreprogrammedSetSpeed6" 14 "PreprogrammedSetSpeed5" 13 "PreprogrammedSetSpeed4" 12 "PreprogrammedSetSpeed3" 11 "PreprogrammedSetSpeed2" 10 "PreprogrammedSetSpeed1" 9 "AccelOverride" 8 "Accelerate" 7 "Resume" 6 "Decelerate_Coast" 5 "Set" 4 "RemoteStandby" 3 "Standby" 2 "RemoteHold" 1 "Hold" 0 "Off_Disabled";
VAL_ 2566844926 EngShutdownOverrideSwitch 3 "NotAvailable" 2 "Error" 1 "On" 0 "Off";
VAL_ 2566844926 EngTestModeSwitch 3 "NotAvailable" 2 "Error" 1 "On" 0 "Off";
VAL_ 2566844926 EngIdleDecrementSwitch 3 "NotAvailable" 2 "Error" 1 "On" 0 "Off";
VAL_ 2566844926 EngIdleIncrementSwitch 3 "NotAvailable" 2 "Error" 1 "On" 0 "Off";
VAL_ 2566844926 CruiseCtrlStates 7 "NotAvailable" 6 "AccelOverride" 5 "Set" 4 "Resume" 3 "Decelerate" 2 "Accelerate" 1 "Hold" 0 "Off_Disabled";
VAL_ 2566844926 CruiseCtrlAccelerateSwitch 3 "NotAvailable" 2 "Error" 1 "CrsCtrlActivatorInPosAccelerate" 0 "CrsCtrlActvtrNotInPosAccelerate";
VAL_ 2566844926 CruiseCtrlResumeSwitch 3 "NotAvailable" 2 "Error" 1 "CruiseCtrlActivatorInPosResume" 0 "CrseCtrlActivatorNotInPosResume";
VAL_ 2566844926 CruiseCtrlCoastSwitch 3 "NotAvailable" 2 "Error" 1 "CruiseCtrlActivatorInPosCoast" 0 "CriseCtrlActivatorNotInPosCoast";
VAL_ 2566844926 CruiseCtrlSetSwitch 3 "NotAvailable" 2 "Error" 1 "CruiseCtrlActivatorInPosSet" 0 "CruiseCtrlActivatorNotInPosSet";
VAL_ 2566844926 ClutchSwitch 3 "NotAvailable" 2 "Error" 1 "ClutchPedalDepressed" 0 "ClutchPedalReleased";
VAL_ 2566844926 BrakeSwitch 3 "NotAvailable" 2 "Error" 1 "BrakePedalDepressed" 0 "BrakePedalReleased";
VAL_ 2566844926 CruiseCtrlEnableSwitch 3 "NotAvailable" 2 "Error" 1 "CruiseCtrlEnabled" 0 "CruiseCtrlDisabled";
VAL_ 2566844926 CruiseCtrlActive 3 "NotAvailable" 2 "Error" 1 "CruiseCtrlSwitchedOn" 0 "CruiseCtrlSwitchedOff";
VAL_ 2566844926 CruiseCtrlPauseSwitch 3 "TakeNoAction" 2 "ErrorIndicator" 1 "On" 0 "Off";
VAL_ 2566844926 ParkingBrakeSwitch 3 "NotAvailable" 2 "Error" 1 "ParkingBrakeSet" 0 "ParkingBrakeNotSet";
VAL_ 2566844926 TwoSpeedAxleSwitch 3 "NotAvailable" 2 "Error" 1 "HighSpeedRange" 0 "LowSpeedRange";
VAL_ 2566719486 EngFuelFilterRestrictedLampCmd 3 "NotAvailable" 2 "Flash" 1 "LampOn" 0 "LampOff";
VAL_ 2566719486 EngAirFilterRestrictionLampCmd 3 "NotAvailable" 2 "Reserved" 1 "LampOn" 0 "LampOff";
VAL_ 2566719486 EngIdleManagementActiveLampCmd 3 "NotAvailable" 2 "Reserved" 1 "LampOn" 0 "LampOff";
VAL_ 2566719486 EngCoolantLevelLowLampCmd 3 "NotAvailable" 2 "Reserved" 1 "LampOn" 0 "LampOff";
VAL_ 2566719486 EngCoolantTempHighLampCmd 3 "NotAvailable" 2 "Reserved" 1 "LampOn" 0 "LampOff";
VAL_ 2566719486 EngOilPressLowLampCmd 3 "NotAvailable" 2 "Reserved" 1 "LampOn" 0 "LampOff";
VAL_ 2566719486 CmprssnBrkEnblSwtchIndctrLmpCmd 3 "NotAvailable" 2 "Reserved" 1 "LampON" 0 "LampOFF";
VAL_ 2566719486 EngBrakeActiveLampCmd 3 "NotAvailable" 2 "Reserved" 1 "LampOn" 0 "LampOff";
VAL_ 2566719486 OBDMalfunctionIndicatorLampCmd 3 "NotAvailable" 2 "Reserved" 1 "LampOn" 0 "LampOff";
VAL_ 2566719486 EngRedStopLampCmd 3 "NotAvailable" 2 "Reserved" 1 "LampOn" 0 "LampOff";
VAL_ 2566719486 EngAmberWarningLampCmd 3 "NotAvailable" 2 "Reserved" 1 "LampOn" 0 "LampOff";
VAL_ 2566719486 EngProtectLampCmd 3 "NotAvailable" 2 "Reserved" 1 "LampOn" 0 "LampOff";
VAL_ 2633832702 RearCollisionSensor4Type 15 "NotAvailable" 14 "ErrrTypOfSnsrCannotBeDetermined" 8 "1101Reserved" 7 "OpticalSensor" 6 "LidarSensor" 5 "RadarSensor" 4 "FiberopticSensor" 3 "SonicSensor" 2 "RollrateSensor" 1 "PressSensor" 0 "AccelerationSensor";
VAL_ 2633832702 RearCollisionSensor3Type 15 "NotAvailable" 14 "ErrrTypOfSnsrCannotBeDetermined" 8 "1101Reserved" 7 "OpticalSensor" 6 "LidarSensor" 5 "RadarSensor" 4 "FiberopticSensor" 3 "SonicSensor" 2 "RollrateSensor" 1 "PressSensor" 0 "AccelerationSensor";
VAL_ 2633832702 RearCollisionSensor2Type 15 "NotAvailable" 14 "ErrrTypOfSnsrCannotBeDetermined" 8 "1101Reserved" 7 "OpticalSensor" 6 "LidarSensor" 5 "RadarSensor" 4 "FiberopticSensor" 3 "SonicSensor" 2 "RollrateSensor" 1 "PressSensor" 0 "AccelerationSensor";
VAL_ 2633832702 RearCollisionSensor1Type 15 "NotAvailable" 14 "ErrrTypOfSnsrCannotBeDetermined" 8 "1101Reserved" 7 "OpticalSensor" 6 "LidarSensor" 5 "RadarSensor" 4 "FiberopticSensor" 3 "SonicSensor" 2 "RollrateSensor" 1 "PressSensor" 0 "AccelerationSensor";
VAL_ 2633832702 SdeCollisionSensorRearRightType 15 "NotAvailable" 14 "ErrrTypOfSnsrCannotBeDetermined" 8 "1101Reserved" 7 "OpticalSensor" 6 "LidarSensor" 5 "RadarSensor" 4 "FiberopticSensor" 3 "SonicSensor" 2 "RollrateSensor" 1 "PressSensor" 0 "AccelerationSensor";
VAL_ 2633832702 SdCllsionSensorMidRearRightType 15 "NotAvailable" 14 "ErrrTypOfSnsrCannotBeDetermined" 8 "1101Reserved" 7 "OpticalSensor" 6 "LidarSensor" 5 "RadarSensor" 4 "FiberopticSensor" 3 "SonicSensor" 2 "RollrateSensor" 1 "PressSensor" 0 "AccelerationSensor";
VAL_ 2633832702 SdCllsonSensorMidFrontRightType 15 "NotAvailable" 14 "ErrrTypOfSnsrCannotBeDetermined" 8 "1101Reserved" 7 "OpticalSensor" 6 "LidarSensor" 5 "RadarSensor" 4 "FiberopticSensor" 3 "SonicSensor" 2 "RollrateSensor" 1 "PressSensor" 0 "AccelerationSensor";
VAL_ 2633832702 SdCollisionSensorFrontRightType 15 "NotAvailable" 14 "ErrrTypOfSnsrCannotBeDetermined" 8 "1101Reserved" 7 "OpticalSensor" 6 "LidarSensor" 5 "RadarSensor" 4 "FiberopticSensor" 3 "SonicSensor" 2 "RollrateSensor" 1 "PressSensor" 0 "AccelerationSensor";
VAL_ 2633832702 SideCollisionSensorRearLeftType 15 "NotAvailable" 14 "ErrrTypOfSnsrCannotBeDetermined" 8 "1101Reserved" 7 "OpticalSensor" 6 "LidarSensor" 5 "RadarSensor" 4 "FiberopticSensor" 3 "SonicSensor" 2 "RollrateSensor" 1 "PressSensor" 0 "AccelerationSensor";
VAL_ 2633832702 SdCllisionSensorMidRearLeftType 15 "NotAvailable" 14 "ErrrTypOfSnsrCannotBeDetermined" 8 "1101Reserved" 7 "OpticalSensor" 6 "LidarSensor" 5 "RadarSensor" 4 "FiberopticSensor" 3 "SonicSensor" 2 "RollrateSensor" 1 "PressSensor" 0 "AccelerationSensor";
VAL_ 2633832702 SdCllsionSensorMidFrontLeftType 15 "NotAvailable" 14 "ErrrTypOfSnsrCannotBeDetermined" 8 "1101Reserved" 7 "OpticalSensor" 6 "LidarSensor" 5 "RadarSensor" 4 "FiberopticSensor" 3 "SonicSensor" 2 "RollrateSensor" 1 "PressSensor" 0 "AccelerationSensor";
VAL_ 2633832702 SdeCollisionSensorFrontLeftType 15 "NotAvailable" 14 "ErrrTypOfSnsrCannotBeDetermined" 8 "1101Reserved" 7 "OpticalSensor" 6 "LidarSensor" 5 "RadarSensor" 4 "FiberopticSensor" 3 "SonicSensor" 2 "RollrateSensor" 1 "PressSensor" 0 "AccelerationSensor";
VAL_ 2633832702 FrontalCollisionSensor4Type 15 "NotAvailable" 14 "ErrrTypOfSnsrCannotBeDetermined" 8 "1101Reserved" 7 "OpticalSensor" 6 "LidarSensor" 5 "RadarSensor" 4 "FiberopticSensor" 3 "SonicSensor" 2 "RollrateSensor" 1 "PressSensor" 0 "AccelerationSensor";
VAL_ 2633832702 FrontalCollisionSensor3Type 15 "NotAvailable" 14 "ErrrTypOfSnsrCannotBeDetermined" 8 "1101Reserved" 7 "OpticalSensor" 6 "LidarSensor" 5 "RadarSensor" 4 "FiberopticSensor" 3 "SonicSensor" 2 "RollrateSensor" 1 "PressSensor" 0 "AccelerationSensor";
VAL_ 2633832702 FrontalCollisionSensor2Type 15 "NotAvailable" 14 "ErrrTypOfSnsrCannotBeDetermined" 8 "1101Reserved" 7 "OpticalSensor" 6 "LidarSensor" 5 "RadarSensor" 4 "FiberopticSensor" 3 "SonicSensor" 2 "RollrateSensor" 1 "PressSensor" 0 "AccelerationSensor";
VAL_ 2633832702 FrontalCollisionSensor1Type 15 "NotAvailable" 14 "ErrrTypOfSnsrCannotBeDetermined" 8 "1101Reserved" 7 "OpticalSensor" 6 "LidarSensor" 5 "RadarSensor" 4 "FiberopticSensor" 3 "SonicSensor" 2 "RollrateSensor" 1 "PressSensor" 0 "AccelerationSensor";
VAL_ 2163223550 CrashType 16 "Rollover" 8 "SideCrash" 2 "RearCrash" 1 "FrontalCrash";
VAL_ 2365400830 Joystick9Button9PressedStatus 3 "NotAvailable" 2 "ErrorIndicator" 1 "ButtonPressed" 0 "ButtonNotPressed";
VAL_ 2365400830 Joystick9Button10PressedStatus 3 "NotAvailable" 2 "ErrorIndicator" 1 "ButtonPressed" 0 "ButtonNotPressed";
VAL_ 2365400830 Joystick9Button11PressedStatus 3 "NotAvailable" 2 "ErrorIndicator" 1 "ButtonPressed" 0 "ButtonNotPressed";
VAL_ 2365400830 Joystick9Button12PressedStatus 3 "NotAvailable" 2 "ErrorIndicator" 1 "ButtonPressed" 0 "ButtonNotPressed";
VAL_ 2365400830 Joystick9Button5PressedStatus 3 "NotAvailable" 2 "ErrorIndicator" 1 "ButtonPressed" 0 "ButtonNotPressed";
VAL_ 2365400830 Joystick9Button6PressedStatus 3 "NotAvailable" 2 "ErrorIndicator" 1 "ButtonPressed" 0 "ButtonNotPressed";
VAL_ 2365400830 Joystick9Button7PressedStatus 3 "NotAvailable" 2 "ErrorIndicator" 1 "ButtonPressed" 0 "ButtonNotPressed";
VAL_ 2365400830 Joystick9Button8PressedStatus 3 "NotAvailable" 2 "ErrorIndicator" 1 "ButtonPressed" 0 "ButtonNotPressed";
VAL_ 2365400830 Joystick9Button1PressedStatus 3 "NotAvailable" 2 "ErrorIndicator" 1 "ButtonPressed" 0 "ButtonNotPressed";
VAL_ 2365400830 Joystick9Button2PressedStatus 3 "NotAvailable" 2 "ErrorIndicator" 1 "ButtonPressed" 0 "ButtonNotPressed";
VAL_ 2365400830 Joystick9Button3PressedStatus 3 "NotAvailable" 2 "ErrorIndicator" 1 "ButtonPressed" 0 "ButtonNotPressed";
VAL_ 2365400830 Joystick9Button4PressedStatus 3 "NotAvailable" 2 "ErrorIndicator" 1 "ButtonPressed" 0 "ButtonNotPressed";
VAL_ 2365400830 Joystick9XAxisDetentPosStatus 3 "NotAvailable" 2 "ErrorIndicator" 1 "InDetentPos" 0 "NotInDetentPos";
VAL_ 2365400830 Joystick9YAxisDetentPosStatus 3 "NotAvailable" 2 "ErrorIndicator" 1 "InDetentPos" 0 "NotInDetentPos";
VAL_ 2365400830 Jystck9YAxsLvrFrwrdPstvPsStatus 3 "NotAvailable" 2 "ErrorIndicator" 1 "OnPositiveSideOfNeutral" 0 "NotOnPositiveSideOfNeutral";
VAL_ 2365400830 Jystck9YAxsLvrBckNgtvePosStatus 3 "NotAvailable" 2 "ErrorIndicator" 1 "OnNegativeSideOfNeutral" 0 "NotOnNegativeSideOfNeutral";
VAL_ 2365400830 Joystick9YAxisNeutralPosStatus 3 "NotAvailable" 2 "ErrorIndicator" 1 "InNeutralPos" 0 "NotInNeutralPos";
VAL_ 2365400830 Jystck9XAxsLvrRghtPstvPosStatus 3 "NotAvailable" 2 "ErrorIndicator" 1 "OnPositiveSideOfNeutral" 0 "NotOnPositiveSideOfNeutral";
VAL_ 2365400830 Jystck9XAxsLvrLftNgtvePosStatus 3 "NotAvailable" 2 "ErrorIndicator" 1 "OnNegativeSideOfNeutral" 0 "NotOnNegativeSideOfNeutral";
VAL_ 2365400830 Joystick9XAxisNeutralPosStatus 3 "NotAvailable" 2 "ErrorIndicator" 1 "InNeutralPos" 0 "NotInNeutralPos";
VAL_ 2365401342 Joystick8Button9PressedStatus 3 "NotAvailable" 2 "ErrorIndicator" 1 "ButtonPressed" 0 "ButtonNotPressed";
VAL_ 2365401342 Joystick8Button10PressedStatus 3 "NotAvailable" 2 "ErrorIndicator" 1 "ButtonPressed" 0 "ButtonNotPressed";
VAL_ 2365401342 Joystick8Button11PressedStatus 3 "NotAvailable" 2 "ErrorIndicator" 1 "ButtonPressed" 0 "ButtonNotPressed";
VAL_ 2365401342 Joystick8Button12PressedStatus 3 "NotAvailable" 2 "ErrorIndicator" 1 "ButtonPressed" 0 "ButtonNotPressed";
VAL_ 2365401342 Joystick8Button5PressedStatus 3 "NotAvailable" 2 "ErrorIndicator" 1 "ButtonPressed" 0 "ButtonNotPressed";
VAL_ 2365401342 Joystick8Button6PressedStatus 3 "NotAvailable" 2 "ErrorIndicator" 1 "ButtonPressed" 0 "ButtonNotPressed";
VAL_ 2365401342 Joystick8Button7PressedStatus 3 "NotAvailable" 2 "ErrorIndicator" 1 "ButtonPressed" 0 "ButtonNotPressed";
VAL_ 2365401342 Joystick8Button8PressedStatus 3 "NotAvailable" 2 "ErrorIndicator" 1 "ButtonPressed" 0 "ButtonNotPressed";
VAL_ 2365401342 Joystick8Button1PressedStatus 3 "NotAvailable" 2 "ErrorIndicator" 1 "ButtonPressed" 0 "ButtonNotPressed";
VAL_ 2365401342 Joystick8Button2PressedStatus 3 "NotAvailable" 2 "ErrorIndicator" 1 "ButtonPressed" 0 "ButtonNotPressed";
VAL_ 2365401342 Joystick8Button3PressedStatus 3 "NotAvailable" 2 "ErrorIndicator" 1 "ButtonPressed" 0 "ButtonNotPressed";
VAL_ 2365401342 Joystick8Button4PressedStatus 3 "NotAvailable" 2 "ErrorIndicator" 1 "ButtonPressed" 0 "ButtonNotPressed";
VAL_ 2365401342 Joystick8XAxisDetentPosStatus 3 "NotAvailable" 2 "ErrorIndicator" 1 "InDetentPos" 0 "NotInDetentPos";
VAL_ 2365401342 Joystick8YAxisDetentPosStatus 3 "NotAvailable" 2 "ErrorIndicator" 1 "InDetentPos" 0 "NotInDetentPos";
VAL_ 2365401342 Jystck8YAxsLvrFrwrdPstvPsStatus 3 "NotAvailable" 2 "ErrorIndicator" 1 "OnPositiveSideOfNeutral" 0 "NotOnPositiveSideOfNeutral";
VAL_ 2365401342 Jystck8YAxsLvrBckNgtvePosStatus 3 "NotAvailable" 2 "ErrorIndicator" 1 "OnNegativeSideOfNeutral" 0 "NotOnNegativeSideOfNeutral";
VAL_ 2365401342 Joystick8YAxisNeutralPosStatus 3 "NotAvailable" 2 "ErrorIndicator" 1 "InNeutralPos" 0 "NotInNeutralPos";
VAL_ 2365401342 Jystck8XAxsLvrRghtPstvPosStatus 3 "NotAvailable" 2 "ErrorIndicator" 1 "OnPositiveSideOfNeutral" 0 "NotOnPositiveSideOfNeutral";
VAL_ 2365401342 Jystck8XAxsLvrLftNgtvePosStatus 3 "NotAvailable" 2 "ErrorIndicator" 1 "OnNegativeSideOfNeutral" 0 "NotOnNegativeSideOfNeutral";
VAL_ 2365401342 Joystick8XAxisNeutralPosStatus 3 "NotAvailable" 2 "ErrorIndicator" 1 "InNeutralPos" 0 "NotInNeutralPos";
VAL_ 2365401854 Joystick7Button9PressedStatus 3 "NotAvailable" 2 "ErrorIndicator" 1 "ButtonPressed" 0 "ButtonNotPressed";
VAL_ 2365401854 Joystick7Button10PressedStatus 3 "NotAvailable" 2 "ErrorIndicator" 1 "ButtonPressed" 0 "ButtonNotPressed";
VAL_ 2365401854 Joystick7Button11PressedStatus 3 "NotAvailable" 2 "ErrorIndicator" 1 "ButtonPressed" 0 "ButtonNotPressed";
VAL_ 2365401854 Joystick7Button12PressedStatus 3 "NotAvailable" 2 "ErrorIndicator" 1 "ButtonPressed" 0 "ButtonNotPressed";
VAL_ 2365401854 Joystick7Button5PressedStatus 3 "NotAvailable" 2 "ErrorIndicator" 1 "ButtonPressed" 0 "ButtonNotPressed";
VAL_ 2365401854 Joystick7Button6PressedStatus 3 "NotAvailable" 2 "ErrorIndicator" 1 "ButtonPressed" 0 "ButtonNotPressed";
VAL_ 2365401854 Joystick7Button7PressedStatus 3 "NotAvailable" 2 "ErrorIndicator" 1 "ButtonPressed" 0 "ButtonNotPressed";
VAL_ 2365401854 Joystick7Button8PressedStatus 3 "NotAvailable" 2 "ErrorIndicator" 1 "ButtonPressed" 0 "ButtonNotPressed";
VAL_ 2365401854 Joystick7Button1PressedStatus 3 "NotAvailable" 2 "ErrorIndicator" 1 "ButtonPressed" 0 "ButtonNotPressed";
VAL_ 2365401854 Joystick7Button2PressedStatus 3 "NotAvailable" 2 "ErrorIndicator" 1 "ButtonPressed" 0 "ButtonNotPressed";
VAL_ 2365401854 Joystick7Button3PressedStatus 3 "NotAvailable" 2 "ErrorIndicator" 1 "ButtonPressed" 0 "ButtonNotPressed";
VAL_ 2365401854 Joystick7Button4PressedStatus 3 "NotAvailable" 2 "ErrorIndicator" 1 "ButtonPressed" 0 "ButtonNotPressed";
VAL_ 2365401854 Joystick7XAxisDetentPosStatus 3 "NotAvailable" 2 "ErrorIndicator" 1 "InDetentPos" 0 "NotInDetentPos";
VAL_ 2365401854 Joystick7YAxisDetentPosStatus 3 "NotAvailable" 2 "ErrorIndicator" 1 "InDetentPos" 0 "NotInDetentPos";
VAL_ 2365401854 Jystck7YAxsLvrFrwrdPstvPsStatus 3 "NotAvailable" 2 "ErrorIndicator" 1 "OnPositiveSideOfNeutral" 0 "NotOnPositiveSideOfNeutral";
VAL_ 2365401854 Jystck7YAxsLvrBckNgtvePosStatus 3 "NotAvailable" 2 "ErrorIndicator" 1 "OnNegativeSideOfNeutral" 0 "NotOnNegativeSideOfNeutral";
VAL_ 2365401854 Joystick7YAxisNeutralPosStatus 3 "NotAvailable" 2 "ErrorIndicator" 1 "InNeutralPos" 0 "NotInNeutralPos";
VAL_ 2365401854 Jystck7XAxsLvrRghtPstvPosStatus 3 "NotAvailable" 2 "ErrorIndicator" 1 "OnPositiveSideOfNeutral" 0 "NotOnPositiveSideOfNeutral";
VAL_ 2365401854 Jystck7XAxsLvrLftNgtvePosStatus 3 "NotAvailable" 2 "ErrorIndicator" 1 "OnNegativeSideOfNeutral" 0 "NotOnNegativeSideOfNeutral";
VAL_ 2365401854 Joystick7XAxisNeutralPosStatus 3 "NotAvailable" 2 "ErrorIndicator" 1 "InNeutralPos" 0 "NotInNeutralPos";
VAL_ 2365402366 Joystick6Button9PressedStatus 3 "NotAvailable" 2 "ErrorIndicator" 1 "ButtonPressed" 0 "ButtonNotPressed";
VAL_ 2365402366 Joystick6Button10PressedStatus 3 "NotAvailable" 2 "ErrorIndicator" 1 "ButtonPressed" 0 "ButtonNotPressed";
VAL_ 2365402366 Joystick6Button11PressedStatus 3 "NotAvailable" 2 "ErrorIndicator" 1 "ButtonPressed" 0 "ButtonNotPressed";
VAL_ 2365402366 Joystick6Button12PressedStatus 3 "NotAvailable" 2 "ErrorIndicator" 1 "ButtonPressed" 0 "ButtonNotPressed";
VAL_ 2365402366 Joystick6Button5PressedStatus 3 "NotAvailable" 2 "ErrorIndicator" 1 "ButtonPressed" 0 "ButtonNotPressed";
VAL_ 2365402366 Joystick6Button6PressedStatus 3 "NotAvailable" 2 "ErrorIndicator" 1 "ButtonPressed" 0 "ButtonNotPressed";
VAL_ 2365402366 Joystick6Button7PressedStatus 3 "NotAvailable" 2 "ErrorIndicator" 1 "ButtonPressed" 0 "ButtonNotPressed";
VAL_ 2365402366 Joystick6Button8PressedStatus 3 "NotAvailable" 2 "ErrorIndicator" 1 "ButtonPressed" 0 "ButtonNotPressed";
VAL_ 2365402366 Joystick6Button1PressedStatus 3 "NotAvailable" 2 "ErrorIndicator" 1 "ButtonPressed" 0 "ButtonNotPressed";
VAL_ 2365402366 Joystick6Button2PressedStatus 3 "NotAvailable" 2 "ErrorIndicator" 1 "ButtonPressed" 0 "ButtonNotPressed";
VAL_ 2365402366 Joystick6Button3PressedStatus 3 "NotAvailable" 2 "ErrorIndicator" 1 "ButtonPressed" 0 "ButtonNotPressed";
VAL_ 2365402366 Joystick6Button4PressedStatus 3 "NotAvailable" 2 "ErrorIndicator" 1 "ButtonPressed" 0 "ButtonNotPressed";
VAL_ 2365402366 Joystick6XAxisDetentPosStatus 3 "NotAvailable" 2 "ErrorIndicator" 1 "InDetentPos" 0 "NotInDetentPos";
VAL_ 2365402366 Joystick6YAxisDetentPosStatus 3 "NotAvailable" 2 "ErrorIndicator" 1 "InDetentPos" 0 "NotInDetentPos";
VAL_ 2365402366 Jystck6YAxsLvrFrwrdPstvPsStatus 3 "NotAvailable" 2 "ErrorIndicator" 1 "OnPositiveSideOfNeutral" 0 "NotOnPositiveSideOfNeutral";
VAL_ 2365402366 Jystck6YAxsLvrBckNgtvePosStatus 3 "NotAvailable" 2 "ErrorIndicator" 1 "OnNegativeSideOfNeutral" 0 "NotOnNegativeSideOfNeutral";
VAL_ 2365402366 Joystick6YAxisNeutralPosStatus 3 "NotAvailable" 2 "ErrorIndicator" 1 "InNeutralPos" 0 "NotInNeutralPos";
VAL_ 2365402366 Jystck6XAxsLvrRghtPstvPosStatus 3 "NotAvailable" 2 "ErrorIndicator" 1 "OnPositiveSideOfNeutral" 0 "NotOnPositiveSideOfNeutral";
VAL_ 2365402366 Jystck6XAxsLvrLftNgtvePosStatus 3 "NotAvailable" 2 "ErrorIndicator" 1 "OnNegativeSideOfNeutral" 0 "NotOnNegativeSideOfNeutral";
VAL_ 2365402366 Joystick6XAxisNeutralPosStatus 3 "NotAvailable" 2 "ErrorIndicator" 1 "InNeutralPos" 0 "NotInNeutralPos";
VAL_ 2365402878 Joystick5Button9PressedStatus 3 "NotAvailable" 2 "ErrorIndicator" 1 "ButtonPressed" 0 "ButtonNotPressed";
VAL_ 2365402878 Joystick5Button10PressedStatus 3 "NotAvailable" 2 "ErrorIndicator" 1 "ButtonPressed" 0 "ButtonNotPressed";
VAL_ 2365402878 Joystick5Button11PressedStatus 3 "NotAvailable" 2 "ErrorIndicator" 1 "ButtonPressed" 0 "ButtonNotPressed";
VAL_ 2365402878 Joystick5Button12PressedStatus 3 "NotAvailable" 2 "ErrorIndicator" 1 "ButtonPressed" 0 "ButtonNotPressed";
VAL_ 2365402878 Joystick5Button5PressedStatus 3 "NotAvailable" 2 "ErrorIndicator" 1 "ButtonPressed" 0 "ButtonNotPressed";
VAL_ 2365402878 Joystick5Button6PressedStatus 3 "NotAvailable" 2 "ErrorIndicator" 1 "ButtonPressed" 0 "ButtonNotPressed";
VAL_ 2365402878 Joystick5Button7PressedStatus 3 "NotAvailable" 2 "ErrorIndicator" 1 "ButtonPressed" 0 "ButtonNotPressed";
VAL_ 2365402878 Joystick5Button8PressedStatus 3 "NotAvailable" 2 "ErrorIndicator" 1 "ButtonPressed" 0 "ButtonNotPressed";
VAL_ 2365402878 Joystick5Button1PressedStatus 3 "NotAvailable" 2 "ErrorIndicator" 1 "ButtonPressed" 0 "ButtonNotPressed";
VAL_ 2365402878 Joystick5Button2PressedStatus 3 "NotAvailable" 2 "ErrorIndicator" 1 "ButtonPressed" 0 "ButtonNotPressed";
VAL_ 2365402878 Joystick5Button3PressedStatus 3 "NotAvailable" 2 "ErrorIndicator" 1 "ButtonPressed" 0 "ButtonNotPressed";
VAL_ 2365402878 Joystick5Button4PressedStatus 3 "NotAvailable" 2 "ErrorIndicator" 1 "ButtonPressed" 0 "ButtonNotPressed";
VAL_ 2365402878 Joystick5XAxisDetentPosStatus 3 "NotAvailable" 2 "ErrorIndicator" 1 "InDetentPos" 0 "NotInDetentPos";
VAL_ 2365402878 Joystick5YAxisDetentPosStatus 3 "NotAvailable" 2 "ErrorIndicator" 1 "InDetentPos" 0 "NotInDetentPos";
VAL_ 2365402878 Jystck5YAxsLvrFrwrdPstvPsStatus 3 "NotAvailable" 2 "ErrorIndicator" 1 "OnPositiveSideOfNeutral" 0 "NotOnPositiveSideOfNeutral";
VAL_ 2365402878 Jystck5YAxsLvrBckNgtvePosStatus 3 "NotAvailable" 2 "ErrorIndicator" 1 "OnNegativeSideOfNeutral" 0 "NotOnNegativeSideOfNeutral";
VAL_ 2365402878 Joystick5YAxisNeutralPosStatus 3 "NotAvailable" 2 "ErrorIndicator" 1 "InNeutralPos" 0 "NotInNeutralPos";
VAL_ 2365402878 Jystck5XAxsLvrRghtPstvPosStatus 3 "NotAvailable" 2 "ErrorIndicator" 1 "OnPositiveSideOfNeutral" 0 "NotOnPositiveSideOfNeutral";
VAL_ 2365402878 Jystck5XAxsLvrLftNgtvePosStatus 3 "NotAvailable" 2 "ErrorIndicator" 1 "OnNegativeSideOfNeutral" 0 "NotOnNegativeSideOfNeutral";
VAL_ 2365402878 Joystick5XAxisNeutralPosStatus 3 "NotAvailable" 2 "ErrorIndicator" 1 "InNeutralPos" 0 "NotInNeutralPos";
VAL_ 2365403390 Joystick4Button9PressedStatus 3 "NotAvailable" 2 "ErrorIndicator" 1 "ButtonPressed" 0 "ButtonNotPressed";
VAL_ 2365403390 Joystick4Button10PressedStatus 3 "NotAvailable" 2 "ErrorIndicator" 1 "ButtonPressed" 0 "ButtonNotPressed";
VAL_ 2365403390 Joystick4Button11PressedStatus 3 "NotAvailable" 2 "ErrorIndicator" 1 "ButtonPressed" 0 "ButtonNotPressed";
VAL_ 2365403390 Joystick4Button12PressedStatus 3 "NotAvailable" 2 "ErrorIndicator" 1 "ButtonPressed" 0 "ButtonNotPressed";
VAL_ 2365403390 Joystick4Button5PressedStatus 3 "NotAvailable" 2 "ErrorIndicator" 1 "ButtonPressed" 0 "ButtonNotPressed";
VAL_ 2365403390 Joystick4Button6PressedStatus 3 "NotAvailable" 2 "ErrorIndicator" 1 "ButtonPressed" 0 "ButtonNotPressed";
VAL_ 2365403390 Joystick4Button7PressedStatus 3 "NotAvailable" 2 "ErrorIndicator" 1 "ButtonPressed" 0 "ButtonNotPressed";
VAL_ 2365403390 Joystick4Button8PressedStatus 3 "NotAvailable" 2 "ErrorIndicator" 1 "ButtonPressed" 0 "ButtonNotPressed";
VAL_ 2365403390 Joystick4Button1PressedStatus 3 "NotAvailable" 2 "ErrorIndicator" 1 "ButtonPressed" 0 "ButtonNotPressed";
VAL_ 2365403390 Joystick4Button2PressedStatus 3 "NotAvailable" 2 "ErrorIndicator" 1 "ButtonPressed" 0 "ButtonNotPressed";
VAL_ 2365403390 Joystick4Button3PressedStatus 3 "NotAvailable" 2 "ErrorIndicator" 1 "ButtonPressed" 0 "ButtonNotPressed";
VAL_ 2365403390 Joystick4Button4PressedStatus 3 "NotAvailable" 2 "ErrorIndicator" 1 "ButtonPressed" 0 "ButtonNotPressed";
VAL_ 2365403390 Joystick4XAxisDetentPosStatus 3 "NotAvailable" 2 "ErrorIndicator" 1 "InDetentPos" 0 "NotInDetentPos";
VAL_ 2365403390 Joystick4YAxisDetentPosStatus 3 "NotAvailable" 2 "ErrorIndicator" 1 "InDetentPos" 0 "NotInDetentPos";
VAL_ 2365403390 Jystck4YAxsLvrFrwrdPstvPsStatus 3 "NotAvailable" 2 "ErrorIndicator" 1 "OnPositiveSideOfNeutral" 0 "NotOnPositiveSideOfNeutral";
VAL_ 2365403390 Jystck4YAxsLvrBckNgtvePosStatus 3 "NotAvailable" 2 "ErrorIndicator" 1 "OnNegativeSideOfNeutral" 0 "NotOnNegativeSideOfNeutral";
VAL_ 2365403390 Joystick4YAxisNeutralPosStatus 3 "NotAvailable" 2 "ErrorIndicator" 1 "InNeutralPos" 0 "NotInNeutralPos";
VAL_ 2365403390 Jystck4XAxsLvrRghtPstvPosStatus 3 "NotAvailable" 2 "ErrorIndicator" 1 "OnPositiveSideOfNeutral" 0 "NotOnPositiveSideOfNeutral";
VAL_ 2365403390 Jystck4XAxsLvrLftNgtvePosStatus 3 "NotAvailable" 2 "ErrorIndicator" 1 "OnNegativeSideOfNeutral" 0 "NotOnNegativeSideOfNeutral";
VAL_ 2365403390 Joystick4XAxisNeutralPosStatus 3 "NotAvailable" 2 "ErrorIndicator" 1 "InNeutralPos" 0 "NotInNeutralPos";
VAL_ 2365400318 Joystick10Button9PressedStatus 3 "NotAvailable" 2 "ErrorIndicator" 1 "ButtonPressed" 0 "ButtonNotPressed";
VAL_ 2365400318 Joystick10Button10PressedStatus 3 "NotAvailable" 2 "ErrorIndicator" 1 "ButtonPressed" 0 "ButtonNotPressed";
VAL_ 2365400318 Joystick10Button11PressedStatus 3 "NotAvailable" 2 "ErrorIndicator" 1 "ButtonPressed" 0 "ButtonNotPressed";
VAL_ 2365400318 Joystick10Button12PressedStatus 3 "NotAvailable" 2 "ErrorIndicator" 1 "ButtonPressed" 0 "ButtonNotPressed";
VAL_ 2365400318 Joystick10Button5PressedStatus 3 "NotAvailable" 2 "ErrorIndicator" 1 "ButtonPressed" 0 "ButtonNotPressed";
VAL_ 2365400318 Joystick10Button6PressedStatus 3 "NotAvailable" 2 "ErrorIndicator" 1 "ButtonPressed" 0 "ButtonNotPressed";
VAL_ 2365400318 Joystick10Button7PressedStatus 3 "NotAvailable" 2 "ErrorIndicator" 1 "ButtonPressed" 0 "ButtonNotPressed";
VAL_ 2365400318 Joystick10Button8PressedStatus 3 "NotAvailable" 2 "ErrorIndicator" 1 "ButtonPressed" 0 "ButtonNotPressed";
VAL_ 2365400318 Joystick10Button1PressedStatus 3 "NotAvailable" 2 "ErrorIndicator" 1 "ButtonPressed" 0 "ButtonNotPressed";
VAL_ 2365400318 Joystick10Button2PressedStatus 3 "NotAvailable" 2 "ErrorIndicator" 1 "ButtonPressed" 0 "ButtonNotPressed";
VAL_ 2365400318 Joystick10Button3PressedStatus 3 "NotAvailable" 2 "ErrorIndicator" 1 "ButtonPressed" 0 "ButtonNotPressed";
VAL_ 2365400318 Joystick10Button4PressedStatus 3 "NotAvailable" 2 "ErrorIndicator" 1 "ButtonPressed" 0 "ButtonNotPressed";
VAL_ 2365400318 Joystick10XAxisDetentPosStatus 3 "NotAvailable" 2 "ErrorIndicator" 1 "InDetentPos" 0 "NotInDetentPos";
VAL_ 2365400318 Joystick10YAxisDetentPosStatus 3 "NotAvailable" 2 "ErrorIndicator" 1 "InDetentPos" 0 "NotInDetentPos";
VAL_ 2365400318 Jystck10YAxsLvrFrwrdPstvPsSttus 3 "NotAvailable" 2 "ErrorIndicator" 1 "OnPositiveSideOfNeutral" 0 "NotOnPositiveSideOfNeutral";
VAL_ 2365400318 Jystck10YAxsLvrBckNgtvPosStatus 3 "NotAvailable" 2 "ErrorIndicator" 1 "OnNegativeSideOfNeutral" 0 "NotOnNegativeSideOfNeutral";
VAL_ 2365400318 Joystick10YAxisNeutralPosStatus 3 "NotAvailable" 2 "ErrorIndicator" 1 "InNeutralPos" 0 "NotInNeutralPos";
VAL_ 2365400318 Jystck10XAxsLvrRghtPstvPsStatus 3 "NotAvailable" 2 "ErrorIndicator" 1 "OnPositiveSideOfNeutral" 0 "NotOnPositiveSideOfNeutral";
VAL_ 2365400318 Jystck10XAxsLvrLftNgtvPosStatus 3 "NotAvailable" 2 "ErrorIndicator" 1 "OnNegativeSideOfNeutral" 0 "NotOnNegativeSideOfNeutral";
VAL_ 2365400318 Joystick10XAxisNeutralPosStatus 3 "NotAvailable" 2 "ErrorIndicator" 1 "InNeutralPos" 0 "NotInNeutralPos";
VAL_ 2499614718 PssngrArbgDctvationSwitchStatus 3 "NotAvailable" 2 "ErrrSttOfDctvtnSwtchCnntBDtrmnd" 1 "PassengerAirbagDeactivated" 0 "PassengerAirbagActivated";
VAL_ 2499614718 Beltlock10Status 3 "NotAvailable" 2 "ErrrBltlckSttCannotBeDetermined" 1 "Locked" 0 "Unlocked";
VAL_ 2499614718 Beltlock9Status 3 "NotAvailable" 2 "ErrrBltlckSttCannotBeDetermined" 1 "Locked" 0 "Unlocked";
VAL_ 2499614718 Beltlock8Status 3 "NotAvailable" 2 "ErrrBltlckSttCannotBeDetermined" 1 "Locked" 0 "Unlocked";
VAL_ 2499614718 Beltlock7Status 3 "NotAvailable" 2 "ErrrBltlckSttCannotBeDetermined" 1 "Locked" 0 "Unlocked";
VAL_ 2499614718 Beltlock6Status 3 "NotAvailable" 2 "ErrrBltlckSttCannotBeDetermined" 1 "Locked" 0 "Unlocked";
VAL_ 2499614718 Beltlock5Status 3 "NotAvailable" 2 "ErrrBltlckSttCannotBeDetermined" 1 "Locked" 0 "Unlocked";
VAL_ 2499614718 Beltlock4Status 3 "NotAvailable" 2 "ErrrBltlckSttCannotBeDetermined" 1 "Locked" 0 "Unlocked";
VAL_ 2499614718 Beltlock3Status 3 "NotAvailable" 2 "ErrrBltlckSttCannotBeDetermined" 1 "Locked" 0 "Unlocked";
VAL_ 2499614718 PassengerBeltlockStatus 3 "NotAvailable" 2 "ErrrBltlckSttCannotBeDetermined" 1 "Locked" 0 "Unlocked";
VAL_ 2499614718 DriverBeltlockStatus 3 "NotAvailable" 2 "ErrrBltlckSttCannotBeDetermined" 1 "Locked" 0 "Unlocked";
VAL_ 2566722814 BatteryCharger2PowerLineState 1 "CnnctdPwrLnIsCnnctdToTheCharger" 0 "DscnnctdPwrLnIsDscnnctdFrmThChr";
VAL_ 2566722814 BatteryCharger2State 1 "ChargingBattery" 0 "IdlngPwrLnThBttryIsDscnnctdFrmT";
VAL_ 2566723070 BatteryCharger1PowerLineState 1 "CnnctdPwrLnIsCnnctdToTheCharger" 0 "DscnnctdPwrLnIsDscnnctdFrmThChr";
VAL_ 2566723070 BatteryCharger1State 1 "ChargingBattery" 0 "IdlngPwrLnThBttryIsDscnnctdFrmT";
VAL_ 2566735102 Aftertreatment2FuelPress2Ctrl 4 "fullyOpen";
VAL_ 2566735102 Aftrtrtmnt2FlFlwDvrterValveCtrl 3 "notAvailable" 2 "reservedForSAEAssignment" 1 "on" 0 "off";
VAL_ 2566735102 Aftrtreatment2FuelPumpRelayCtrl 3 "notAvailable" 2 "reservedForSAEAssignment" 1 "on" 0 "off";
VAL_ 2566805246 AftrtrtmntSCROprtrIndcmntSvrity 7 "NotAvailable_NotSupported" 6 "Reserved" 5 "InducementLevel5" 4 "InducementLevel4" 3 "InducementLevel3" 2 "InducementLevel2" 1 "InducementLevel1" 0 "NoInducementActive";
VAL_ 2566805246 Aftrtrtmnt1DEFTnkLwLvlIndicator 7 "notAvailable" 4 "OnFastBlink" 6 "reservedForSAEAssignment" 1 "OnSolid" 0 "Off";
VAL_ 2566805246 Aftrtrtmnt1SCRCatalystTankLevel 4 "Full" 0 "Empty";
VAL_ 2566711806 ArmrestSwitchMatrix2Switch2 3 "DontCare_TakeNoAction" 2 "Reserved" 1 "On" 0 "Off";
VAL_ 2566711806 ArmrestSwitchMatrix2Switch1 3 "DontCare_TakeNoAction" 2 "Reserved" 1 "On" 0 "Off";
VAL_ 2566711806 ArmrestSwitchMatrixSwitch2 3 "DontCare_TakeNoAction" 2 "Reserved" 1 "On" 0 "Off";
VAL_ 2566711806 ArmrestSwitchMatrixSwitch1 3 "DontCare_TakeNoAction" 2 "Reserved" 1 "On" 0 "Off";
VAL_ 2364549886 YawRateExRangeFigureOfMerit 3 "NotAvailable" 2 "Error" 1 "YwRtDgrddDtIsSspctDTEnvrnmntlCn" 0 "YwRtFllyFnctnlDtIsWthnSnsrSpcfc";
VAL_ 2364549886 RollRateExRangeFigureOfMerit 3 "NotAvailable" 2 "Error" 1 "RllRtDgrddDtIsSspctDTEnvrnmntlC" 0 "RllRtFllyFnctnlDtIsWthnSnsrSpcf";
VAL_ 2364549886 PitchRateExRangeFigureOfMerit 3 "NotAvailable" 2 "Error" 1 "PtchRtDgrddDtIsSspctDTEnvrnmntl" 0 "PtchRtFllyFnctnlDtIsWthnSnsrSpc";
VAL_ 2566712318 Aftrtrtmnt2NOxAdsrbrDSOxRgnrtnSt 3 "NotAvailable" 2 "ErrorIndicator" 1 "Active" 0 "Inactive";
VAL_ 2566712318 Aftrtrtmnt2NOxAdsrbrDNOxRgnrtnSt 3 "NotAvailable" 2 "ErrorIndicator" 1 "Active" 0 "Inactive";
VAL_ 2566712574 Aftrtrtmnt1NOxAdsrbrDSOxRgnrtnSt 3 "NotAvailable" 2 "ErrorIndicator" 1 "Active" 0 "Inactive";
VAL_ 2566712574 Aftrtrtmnt1NOxAdsrbrDNOxRgnrtnSt 3 "NotAvailable" 2 "ErrorIndicator" 1 "Active" 0 "Inactive";
VAL_ 2566731262 Aftrtrtmnt2SCRCatalystTankLevel 4 "Full" 0 "Empty";
VAL_ 2566730750 Aftrtrtmnt2SCRCtlystRgntPmpStte 3 "notAvailable" 2 "reservedForSAEAssignment" 1 "pumpError" 0 "pumpOperational";
VAL_ 2566731518 Aftrtrtmnt2SCRCtlystReagentType 15 "NotAvailable" 14 "ErrrDtctdWthUrRgntTypeDetection" 13 "NtAblTDtrmneCatalystReagentType" 5 "to1100ReservedForSAEAssignment" 3 "CatalystReagentIsProperMixture" 2 "CatalystReagentIsDiesel" 1 "CtlystRgntIsUrCncntrationTooLow" 0 "CtlystRgntIsUrCncntrtionTooHigh";
VAL_ 2164079358 Aftrtrtmnt2SCRCtlystRgntLnHter4 3 "notAvailable" 2 "rservedForFutureAssignmentBySAE" 1 "RqForHeaterToBeActive" 0 "RqForHeaterToBeInactive";
VAL_ 2164079358 Aftrtrtmnt2SCRCtlystRgntLnHter3 3 "notAvailable" 2 "rservedForFutureAssignmentBySAE" 1 "RqForHeaterToBeActive" 0 "RqForHeaterToBeInactive";
VAL_ 2164079358 Aftrtrtmnt2SCRCtlystRgntLnHter2 3 "notAvailable" 2 "rservedForFutureAssignmentBySAE" 1 "RqForHeaterToBeActive" 0 "RqForHeaterToBeInactive";
VAL_ 2164079358 Aftrtrtmnt2SCRCtlystRgntLnHter1 3 "notAvailable" 2 "rservedForFutureAssignmentBySAE" 1 "RqForHeaterToBeActive" 0 "RqForHeaterToBeInactive";
VAL_ 2164079358 Aftrtrtmnt2SCRDserHeatingModeRq 7 "NotAvailable" 4 "110Reserved" 3 "HeaterOn" 2 "HeaterAutomaticMode" 1 "HeaterEconomyMode" 0 "HeaterOff";
VAL_ 2164079358 Aftrtrtmnt2SCRDsrFltSpprssionRq 3 "NotAvailable" 2 "Reserved" 1 "ErrorSuppressionOn" 0 "ErrorSuppressionOff";
VAL_ 2364549118 Aftrtratment2SCRSystemRqedState 15 "NotAvailable" 14 "Error" 11 "1101RsrvdFrFtureAssignmentBySAE" 10 "ServiceTestModeDosingNotAllowed" 9 "ServiceTestModeDosingAllowed" 8 "Diagnosis" 7 "Shutoff" 6 "ProtectModeAgainstCold" 5 "ProtectModeAgainstHeat" 4 "RservedForFutureAssignmentBySAE" 3 "SystemErrorPending" 2 "NormalDosingOperation" 1 "PreparingDosingReadiness" 0 "Dormant";
VAL_ 2566732798 Aftrtrtmnt2SCRCtlystRgntLnHtr4St 3 "notAvailable" 2 "error" 1 "heaterActive" 0 "heaterInactive";
VAL_ 2566732798 Aftrtrtmnt2SCRCtlystRgntLnHtr3St 3 "notAvailable" 2 "error" 1 "heaterActive" 0 "heaterInactive";
VAL_ 2566732798 Aftrtrtmnt2SCRCtlystRgntLnHtr2St 3 "notAvailable" 2 "error" 1 "heaterActive" 0 "heaterInactive";
VAL_ 2566732798 Aftrtrtmnt2SCRCtlystRgntLnHtr1St 3 "notAvailable" 2 "error" 1 "heaterActive" 0 "heaterInactive";
VAL_ 2566732798 Aftrtrtmnt2SCRFedbackCtrlStatus 7 "notAvailable" 6 "error" 5 "rservedForFutureAssignmentBySAE" 1 "closedLoopCtrlActive" 0 "openLoopCtrlActive";
VAL_ 2566732798 Aftrtrtmnt2SCRDsngVlvExhstTmpRdc 7 "NotAvailable" 6 "Error" 5 "RservedForFutureAssignmentBySAE" 2 "ReductionRqStage2" 1 "ReductionRqStage1" 0 "NoRq";
VAL_ 2364548862 Aftertreatment2SCRSystemState 15 "NotAvailable" 14 "Error" 11 "1101RsrvdFrFtureAssignmentBySAE" 10 "ServiceTestModeDosingNotAllowed" 9 "ServiceTestModeDosingAllowed" 8 "Diagnosis" 7 "Shutoff" 6 "ProtectModeAgainstCold" 5 "ProtectModeAgainstHeat" 4 "RservedForFutureAssignmentBySAE" 3 "SystemErrorPending" 2 "NormalDosingOperation" 1 "PreparingDosingReadiness" 0 "Dormant";
VAL_ 2364549374 Aftrtrtmnt2OtltNH3GsSnsrHtrCtrl 3 "HeaterOffNotAvailable" 2 "Preheat1" 1 "Preheat2" 0 "Automatic";
VAL_ 2566733054 Aftrtrtmnt1SCRCtlystRgntPmpStte 3 "notAvailable" 2 "reservedForSAEAssignment" 1 "pumpError" 0 "pumpOperational";
VAL_ 2566734078 Aftrtrtmnt1SCRCtlystRgntLnHter4 3 "notAvailable" 2 "rservedForFutureAssignmentBySAE" 1 "RqForHeaterToBeActive" 0 "RqForHeaterToBeInactive";
VAL_ 2566734078 Aftrtrtmnt1SCRCtlystRgntLnHter3 3 "notAvailable" 2 "rservedForFutureAssignmentBySAE" 1 "RqForHeaterToBeActive" 0 "RqForHeaterToBeInactive";
VAL_ 2566734078 Aftrtrtmnt1SCRCtlystRgntLnHter2 3 "notAvailable" 2 "rservedForFutureAssignmentBySAE" 1 "RqForHeaterToBeActive" 0 "RqForHeaterToBeInactive";
VAL_ 2566734078 Aftrtrtmnt1SCRCtlystRgntLnHter1 3 "notAvailable" 2 "rservedForFutureAssignmentBySAE" 1 "RqForHeaterToBeActive" 0 "RqForHeaterToBeInactive";
VAL_ 2566734078 Aftrtrtmnt1SCRDserHeatingModeRq 7 "NotAvailable" 4 "110Reserved" 3 "HeaterOn" 2 "HeaterAutomaticMode" 1 "HeaterEconomyMode" 0 "HeaterOff";
VAL_ 2566734078 Aftrtrtmnt1SCRDsrFltSpprssionRq 3 "NotAvailable" 2 "Reserved" 1 "ErrorSuppressionOn" 0 "ErrorSuppressionOff";
VAL_ 2364548350 Aftrtratment1SCRSystemRqedState 15 "NotAvailable" 14 "Error" 11 "1101RsrvdFrFtureAssignmentBySAE" 10 "ServiceTestModeDosingNotAllowed" 9 "ServiceTestModeDosingAllowed" 8 "Diagnosis" 7 "Shutoff" 6 "ProtectModeAgainstCold" 5 "ProtectModeAgainstHeat" 4 "RservedForFutureAssignmentBySAE" 3 "SystemErrorPending" 2 "NormalDosingOperation" 1 "PreparingDosingReadiness" 0 "Dormant";
VAL_ 2566734334 Aftrtrtmnt1SCRCtlystRgntLnHtr4St 3 "notAvailable" 2 "error" 1 "heaterActive" 0 "heaterInactive";
VAL_ 2566734334 Aftrtrtmnt1SCRCtlystRgntLnHtr3St 3 "notAvailable" 2 "error" 1 "heaterActive" 0 "heaterInactive";
VAL_ 2566734334 Aftrtrtmnt1SCRCtlystRgntLnHtr2St 3 "notAvailable" 2 "error" 1 "heaterActive" 0 "heaterInactive";
VAL_ 2566734334 Aftrtrtmnt1SCRCtlystRgntLnHtr1St 3 "notAvailable" 2 "error" 1 "heaterActive" 0 "heaterInactive";
VAL_ 2566734334 Aftrtrtmnt1SCRFedbackCtrlStatus 7 "notAvailable" 6 "error" 5 "rservedForFutureAssignmentBySAE" 1 "closedLoopCtrlActive" 0 "openLoopCtrlActive";
VAL_ 2566734334 Aftrtrtmnt1SCRDsngVlvExhstTmpRdc 7 "NotAvailable" 6 "Error" 5 "RservedForFutureAssignmentBySAE" 2 "ReductionRqStage2" 1 "ReductionRqStage1" 0 "NoRq";
VAL_ 2364548094 Aftertreatment1SCRSystemState 15 "NotAvailable" 14 "Error" 11 "1101RsrvdFrFtureAssignmentBySAE" 10 "ServiceTestModeDosingNotAllowed" 9 "ServiceTestModeDosingAllowed" 8 "Diagnosis" 7 "Shutoff" 6 "ProtectModeAgainstCold" 5 "ProtectModeAgainstHeat" 4 "RservedForFutureAssignmentBySAE" 3 "SystemErrorPending" 2 "NormalDosingOperation" 1 "PreparingDosingReadiness" 0 "Dormant";
VAL_ 2364548606 Aftrtrtmnt1OtltNH3GsSnsrHtrCtrl 3 "HeaterOffNotAvailable" 2 "Preheat1" 1 "Preheat2" 0 "Automatic";
VAL_ 2566742270 FailureModeIdentifier1 31 "Not available" 19 "Received network data in error" 18 "Below normal (moderately severe)" 17 "Below normal (least severe)" 16 "Above normal (moderately severe)" 15 "Above normal (least severe)" 14 "Special intstructions" 13 "Out of calibration" 12 "Bad intelligent device" 11 "Root cause not known" 10 "Abnormal rate of change" 9 "Abnormal update rate" 8 "Abnormal frequency" 7 "Mechanical system not responding" 6 "Current above normal" 5 "Current below normal" 4 "Voltage below normal" 3 "Voltage above normal" 2 "Data erratic" 1 "Below normal (most severe)" 0 "Above normal (most severe)";
VAL_ 2560687870 PMNTEDeficiencyAreaStatus 3 "NotAvailable" 2 "Reserved" 1 "InsideControlArea" 0 "OutsideControlArea";
VAL_ 2560687870 MnfcPMNTECarveOutAreaStatus 3 "NotAvailable" 2 "Reserved" 1 "InsideControlArea" 0 "OutsideControlArea";
VAL_ 2560687870 PMNTEControlAreaStatus 3 "NotAvailable" 2 "Reserved" 1 "InsideControlArea" 0 "OutsideControlArea";
VAL_ 2560687870 NOxNTEDeficiencyAreaStatus 3 "NotAvailable" 2 "Reserved" 1 "InsideControlArea" 0 "OutsideControlArea";
VAL_ 2560687870 MnfcNOxNTECarveOutAreaStatus 3 "NotAvailable" 2 "Reserved" 1 "InsideControlArea" 0 "OutsideControlArea";
VAL_ 2560687870 NOxNTEControlAreaStatus 3 "NotAvailable" 2 "Reserved" 1 "InsideControlArea" 0 "OutsideControlArea";
VAL_ 2566809342 BatteryMainSwitchHoldState 3 "DontCare_TakeNoAction" 2 "Reserved" 1 "BatteryMainSwitchHeld" 0 "BatteryMainSwitchNotHeld";
VAL_ 2365446910 Joystick3XAxisDetentPosStatus 3 "NotAvailable" 2 "ErrorIndicator" 1 "InDetentPos" 0 "NotInDetentPos";
VAL_ 2365446910 Joystick3Button9PressedStatus 3 "NotAvailable" 2 "ErrorIndicator" 1 "ButtonPressed" 0 "ButtonNotPressed";
VAL_ 2365446910 Joystick3Button10PressedStatus 3 "NotAvailable" 2 "ErrorIndicator" 1 "ButtonPressed" 0 "ButtonNotPressed";
VAL_ 2365446910 Joystick3Button11PressedStatus 3 "NotAvailable" 2 "ErrorIndicator" 1 "ButtonPressed" 0 "ButtonNotPressed";
VAL_ 2365446910 Joystick3Button12PressedStatus 3 "NotAvailable" 2 "ErrorIndicator" 1 "ButtonPressed" 0 "ButtonNotPressed";
VAL_ 2365446910 Joystick3YAxisDetentPosStatus 3 "NotAvailable" 2 "ErrorIndicator" 1 "InDetentPos" 0 "NotInDetentPos";
VAL_ 2365446910 Jystck3YAxsLvrFrwrdPstvPsStatus 3 "NotAvailable" 2 "ErrorIndicator" 1 "OnPositiveSideOfNeutral" 0 "NotOnPositiveSideOfNeutral";
VAL_ 2365446910 Jystck3YAxsLvrBckNgtvePosStatus 3 "NotAvailable" 2 "ErrorIndicator" 1 "OnNegativeSideOfNeutral" 0 "NotOnNegativeSideOfNeutral";
VAL_ 2365446910 Joystick3YAxisNeutralPosStatus 3 "NotAvailable" 2 "ErrorIndicator" 1 "InNeutralPos" 0 "NotInNeutralPos";
VAL_ 2365446910 Jystck3XAxsLvrRghtPstvPosStatus 3 "NotAvailable" 2 "ErrorIndicator" 1 "OnPositiveSideOfNeutral" 0 "NotOnPositiveSideOfNeutral";
VAL_ 2365446910 Jystck3XAxsLvrLftNgtvePosStatus 3 "NotAvailable" 2 "ErrorIndicator" 1 "OnNegativeSideOfNeutral" 0 "NotOnNegativeSideOfNeutral";
VAL_ 2365446910 Joystick3XAxisNeutralPosStatus 3 "NotAvailable" 2 "ErrorIndicator" 1 "InNeutralPos" 0 "NotInNeutralPos";
VAL_ 2365446910 Joystick3Button5PressedStatus 3 "NotAvailable" 2 "ErrorIndicator" 1 "ButtonPressed" 0 "ButtonNotPressed";
VAL_ 2365446910 Joystick3Button6PressedStatus 3 "NotAvailable" 2 "ErrorIndicator" 1 "ButtonPressed" 0 "ButtonNotPressed";
VAL_ 2365446910 Joystick3Button7PressedStatus 3 "NotAvailable" 2 "ErrorIndicator" 1 "ButtonPressed" 0 "ButtonNotPressed";
VAL_ 2365446910 Joystick3Button8PressedStatus 3 "NotAvailable" 2 "ErrorIndicator" 1 "ButtonPressed" 0 "ButtonNotPressed";
VAL_ 2365446910 Joystick3Button1PressedStatus 3 "NotAvailable" 2 "ErrorIndicator" 1 "ButtonPressed" 0 "ButtonNotPressed";
VAL_ 2365446910 Joystick3Button2PressedStatus 3 "NotAvailable" 2 "ErrorIndicator" 1 "ButtonPressed" 0 "ButtonNotPressed";
VAL_ 2365446910 Joystick3Button3PressedStatus 3 "NotAvailable" 2 "ErrorIndicator" 1 "ButtonPressed" 0 "ButtonNotPressed";
VAL_ 2365446910 Joystick3Button4PressedStatus 3 "NotAvailable" 2 "ErrorIndicator" 1 "ButtonPressed" 0 "ButtonNotPressed";
VAL_ 2365446398 Joystick2XAxisDetentPosStatus 3 "NotAvailable" 2 "ErrorIndicator" 1 "InDetentPos" 0 "NotInDetentPos";
VAL_ 2365446398 Joystick2YAxisDetentPosStatus 3 "NotAvailable" 2 "ErrorIndicator" 1 "InDetentPos" 0 "NotInDetentPos";
VAL_ 2365446398 Jystck2YAxsLvrFrwrdPstvPsStatus 3 "NotAvailable" 2 "ErrorIndicator" 1 "OnPositiveSideOfNeutral" 0 "NotOnPositiveSideOfNeutral";
VAL_ 2365446398 Jystck2YAxsLvrBckNgtvePosStatus 3 "NotAvailable" 2 "ErrorIndicator" 1 "OnNegativeSideOfNeutral" 0 "NotOnNegativeSideOfNeutral";
VAL_ 2365446398 Joystick2YAxisNeutralPosStatus 3 "NotAvailable" 2 "ErrorIndicator" 1 "InNeutralPos" 0 "NotInNeutralPos";
VAL_ 2365446398 Jystck2XAxsLvrRghtPstvPosStatus 3 "NotAvailable" 2 "ErrorIndicator" 1 "OnPositiveSideOfNeutral" 0 "NotOnPositiveSideOfNeutral";
VAL_ 2365446398 Jystck2XAxsLvrLftNgtvePosStatus 3 "NotAvailable" 2 "ErrorIndicator" 1 "OnNegativeSideOfNeutral" 0 "NotOnNegativeSideOfNeutral";
VAL_ 2365446398 Joystick2XAxisNeutralPosStatus 3 "NotAvailable" 2 "ErrorIndicator" 1 "InNeutralPos" 0 "NotInNeutralPos";
VAL_ 2365446398 Joystick2Button9PressedStatus 3 "NotAvailable" 2 "ErrorIndicator" 1 "ButtonPressed" 0 "ButtonNotPressed";
VAL_ 2365446398 Joystick2Button10PressedStatus 3 "NotAvailable" 2 "ErrorIndicator" 1 "ButtonPressed" 0 "ButtonNotPressed";
VAL_ 2365446398 Joystick2Button11PressedStatus 3 "NotAvailable" 2 "ErrorIndicator" 1 "ButtonPressed" 0 "ButtonNotPressed";
VAL_ 2365446398 Joystick2Button12PressedStatus 3 "NotAvailable" 2 "ErrorIndicator" 1 "ButtonPressed" 0 "ButtonNotPressed";
VAL_ 2365446398 Joystick2Button5PressedStatus 3 "NotAvailable" 2 "ErrorIndicator" 1 "ButtonPressed" 0 "ButtonNotPressed";
VAL_ 2365446398 Joystick2Button6PressedStatus 3 "NotAvailable" 2 "ErrorIndicator" 1 "ButtonPressed" 0 "ButtonNotPressed";
VAL_ 2365446398 Joystick2Button7PressedStatus 3 "NotAvailable" 2 "ErrorIndicator" 1 "ButtonPressed" 0 "ButtonNotPressed";
VAL_ 2365446398 Joystick2Button8PressedStatus 3 "NotAvailable" 2 "ErrorIndicator" 1 "ButtonPressed" 0 "ButtonNotPressed";
VAL_ 2365446398 Joystick2Button1PressedStatus 3 "NotAvailable" 2 "ErrorIndicator" 1 "ButtonPressed" 0 "ButtonNotPressed";
VAL_ 2365446398 Joystick2Button2PressedStatus 3 "NotAvailable" 2 "ErrorIndicator" 1 "ButtonPressed" 0 "ButtonNotPressed";
VAL_ 2365446398 Joystick2Button3PressedStatus 3 "NotAvailable" 2 "ErrorIndicator" 1 "ButtonPressed" 0 "ButtonNotPressed";
VAL_ 2365446398 Joystick2Button4PressedStatus 3 "NotAvailable" 2 "ErrorIndicator" 1 "ButtonPressed" 0 "ButtonNotPressed";
VAL_ 2365445886 Joystick1XAxisDetentPosStatus 3 "NotAvailable" 2 "ErrorIndicator" 1 "InDetentPos" 0 "NotInDetentPos";
VAL_ 2365445886 Joystick1YAxisDetentPosStatus 3 "NotAvailable" 2 "ErrorIndicator" 1 "InDetentPos" 0 "NotInDetentPos";
VAL_ 2365445886 Jystck1YAxsLvrFrwrdPstvPsStatus 3 "NotAvailable" 2 "ErrorIndicator" 1 "OnPositiveSideOfNeutral" 0 "NotOnPositiveSideOfNeutral";
VAL_ 2365445886 Jystck1YAxsLvrBckNgtvePosStatus 3 "NotAvailable" 2 "ErrorIndicator" 1 "OnNegativeSideOfNeutral" 0 "NotOnNegativeSideOfNeutral";
VAL_ 2365445886 Joystick1YAxisNeutralPosStatus 3 "NotAvailable" 2 "ErrorIndicator" 1 "InNeutralPos" 0 "NotInNeutralPos";
VAL_ 2365445886 Joystick1Button9PressedStatus 3 "NotAvailable" 2 "ErrorIndicator" 1 "ButtonPressed" 0 "ButtonNotPressed";
VAL_ 2365445886 Joystick1Button10PressedStatus 3 "NotAvailable" 2 "ErrorIndicator" 1 "ButtonPressed" 0 "ButtonNotPressed";
VAL_ 2365445886 Joystick1Button11PressedStatus 3 "NotAvailable" 2 "ErrorIndicator" 1 "ButtonPressed" 0 "ButtonNotPressed";
VAL_ 2365445886 Joystick1Button12PressedStatus 3 "NotAvailable" 2 "ErrorIndicator" 1 "ButtonPressed" 0 "ButtonNotPressed";
VAL_ 2365445886 Joystick1Button5PressedStatus 3 "NotAvailable" 2 "ErrorIndicator" 1 "ButtonPressed" 0 "ButtonNotPressed";
VAL_ 2365445886 Joystick1Button6PressedStatus 3 "NotAvailable" 2 "ErrorIndicator" 1 "ButtonPressed" 0 "ButtonNotPressed";
VAL_ 2365445886 Joystick1Button7PressedStatus 3 "NotAvailable" 2 "ErrorIndicator" 1 "ButtonPressed" 0 "ButtonNotPressed";
VAL_ 2365445886 Joystick1Button8PressedStatus 3 "NotAvailable" 2 "ErrorIndicator" 1 "ButtonPressed" 0 "ButtonNotPressed";
VAL_ 2365445886 Joystick1Button1PressedStatus 3 "NotAvailable" 2 "ErrorIndicator" 1 "ButtonPressed" 0 "ButtonNotPressed";
VAL_ 2365445886 Joystick1Button2PressedStatus 3 "NotAvailable" 2 "ErrorIndicator" 1 "ButtonPressed" 0 "ButtonNotPressed";
VAL_ 2365445886 Joystick1Button3PressedStatus 3 "NotAvailable" 2 "ErrorIndicator" 1 "ButtonPressed" 0 "ButtonNotPressed";
VAL_ 2365445886 Joystick1Button4PressedStatus 3 "NotAvailable" 2 "ErrorIndicator" 1 "ButtonPressed" 0 "ButtonNotPressed";
VAL_ 2365445886 Jystck1XAxsLvrRghtPstvPosStatus 3 "NotAvailable" 2 "ErrorIndicator" 1 "OnPositiveSideOfNeutral" 0 "NotOnPositiveSideOfNeutral";
VAL_ 2365445886 Jystck1XAxsLvrLftNgtvePosStatus 3 "NotAvailable" 2 "ErrorIndicator" 1 "OnNegativeSideOfNeutral" 0 "NotOnNegativeSideOfNeutral";
VAL_ 2365445886 Joystick1XAxisNeutralPosStatus 3 "NotAvailable" 2 "ErrorIndicator" 1 "InNeutralPos" 0 "NotInNeutralPos";
VAL_ 2566847230 ParkingBrakeRedWarningSignal 3 "TakeNoAction" 2 "Reserved" 1 "On" 0 "Off";
VAL_ 2566847230 ParkBrakeReleaseInhibitStatus 3 "Unavailable" 2 "Error" 1 "ParkBrakeReleaseIsInhibited" 0 "ParkBrakeReleaseIsNotInhibited";
VAL_ 2566847230 ParkingBrakeActuator 3 "NotAvailable" 2 "Error" 1 "ParkingBrakeActuatorActive" 0 "ParkingBrakeActuatorInactive";
VAL_ 2560884478 DTCWarnLampSupportStatus 3 "Unavailable" 2 "Reserved" 1 "LampOn" 0 "LampOff";
VAL_ 2560884478 DTCWarnLampSupportFlash 3 "Unavailable" 2 "Reserved" 1 "FastFlash" 0 "SlowFlash";
VAL_ 2560884478 DTCStopLampSupportStatus 3 "Unavailable" 2 "Reserved" 1 "LampOn" 0 "LampOff";
VAL_ 2560884478 DTCStopLampSupportFlash 3 "Unavailable" 2 "Reserved" 1 "FastFlash" 0 "SlowFlash";
VAL_ 2560884478 DTCProtectLampSupportStatus 3 "Unavailable" 2 "Reserved" 1 "LampOn" 0 "LampOff";
VAL_ 2560884478 DTCProtectLampSupportFlash 3 "Unavailable" 2 "Reserved" 1 "FastFlash" 0 "SlowFlash";
VAL_ 2560884478 DTCMilSupportStatus 3 "Unavailable" 2 "ShortMI" 1 "LampOn" 0 "LampOff";
VAL_ 2560884478 DTCMilSupportFlash 3 "Unavailable" 2 "Class_C_DTC" 1 "FastFlash" 0 "SlowFlash";
VAL_ 2566736126 EngExhstGsOxygnSnsrClsdLpOprtnBn 15 "NotSupported" 5 "1110Reserved" 4 "ClsdLpBtFltWthAtLstOnOxygnSnsrM" 3 "OpnLoopDueToDetectedSystemFault" 2 "OpenLoopDueToDrivingConditions" 1 "ClsdLpUsngOxygnSnsrAsFdbckFrFlC" 0 "OpnLpHsNtYtStsfdCndtnsTGClsdLop";
VAL_ 2566736382 EngExhstGsOxygnSnsrClsdLpOp_0000 15 "NotSupported" 5 "1110Reserved" 4 "ClsdLpBtFltWthAtLstOnOxygnSnsrM" 3 "OpnLoopDueToDetectedSystemFault" 2 "OpenLoopDueToDrivingConditions" 1 "ClsdLpUsngOxygnSnsrAsFdbckFrFlC" 0 "OpnLpHsNtYtStsfdCndtnsTGClsdLop";
VAL_ 2565874174 EngSpdSnsor1TimingPatternStatus 3 "NotAvailable" 2 "Error" 1 "OK" 0 "NotOK";
VAL_ 2565874174 EngSpdSnsor2TimingPatternStatus 3 "NotAvailable" 2 "Error" 1 "OK" 0 "NotOK";
VAL_ 2565874174 EngSpdSnsor3TimingPatternStatus 3 "NotAvailable" 2 "Error" 1 "OK" 0 "NotOK";
VAL_ 2432520958 EngCoolantThermostatMode 3 "DontCare_Reserved" 2 "Reserved" 1 "PosCtrlMode" 0 "TempCtrlMode";
VAL_ 2566758398 Aftrtreatment1AirEnableActuator 3 "notAvailable" 2 "reservedForSAEAssignment" 1 "active" 0 "notActive";
VAL_ 2566758398 Aftertreatment1PurgeAirActuator 3 "notAvailable" 2 "reservedForSAEAssignment" 1 "active" 0 "notActive";
VAL_ 2566758398 Aftrtrtmnt1AtmzationAirActuator 3 "notAvailable" 2 "reservedForSAEAssignment" 1 "active" 0 "notActive";
VAL_ 2566758398 Aftertreatment1AirSystemRelay 3 "notAvailable" 2 "reservedForSAEAssignment" 1 "active" 0 "notActive";
VAL_ 2566758910 Aftrtrtmnt1FlInjctor1HeaterCtrl 4 "Max";
VAL_ 2566758910 Aftrtratment1FuelEnableActuator 3 "notAvailable" 2 "reservedForSAEAssignment" 1 "active" 0 "notActive";
VAL_ 2566758910 Aftrtratment1RegenerationStatus 3 "notAvailable" 2 "reservedForSAEAssignment" 1 "active" 0 "notActive";
VAL_ 2566758910 Aftertreatment1Ignt 3 "notAvailable" 2 "reservedForSAEAssignment" 1 "active" 0 "notActive";
VAL_ 2566758910 Aftrtreatment1FuelDrainActuator 3 "notAvailable" 2 "reservedForSAEAssignment" 1 "active" 0 "notActive";
VAL_ 2566743550 Aftrtrtmnt1FlPress2ActuatorCtrl 4 "fullyOpen";
VAL_ 2566743550 Aftrtrtmnt1FlFlwDvrterValveCtrl 3 "notAvailable" 2 "reservedForSAEAssignment" 1 "on" 0 "off";
VAL_ 2566743550 Aftrtreatment1FuelPumpRelayCtrl 3 "notAvailable" 2 "reservedForSAEAssignment" 1 "on" 0 "off";
VAL_ 2565869310 Aftrtrtmnt1IntkGsSnsrPwerStatus 3 "NotAvailable" 2 "Error" 1 "InRange" 0 "NotInRange";
VAL_ 2565869310 Aftrtrtmnt1IntkGsSnsrHeaterCtrl 3 "HeaterOff" 2 "Preheat1" 1 "Preheat2" 0 "Automatic";
VAL_ 2565869310 Aftrtrtmnt1IntkWdRngO2RdngStble 3 "NotAvailable" 2 "Error" 1 "Stable" 0 "NotStable";
VAL_ 2565869310 Aftrtrtmnt1IntkNOxReadingStable 3 "NotAvailable" 2 "Error" 1 "Stable" 0 "NotStable";
VAL_ 2631728894 AntitheftComponentStatusStates 3 "NotDefined" 2 "BlckdThsSttIndctsThtALckUnlckCm" 1 "LckdThsSttIndctsThtCmpnntCnNOTB" 0 "UnlckdThsSttIndctsThtCmpnntCnBS";
VAL_ 2631728894 AntthftEncryptnSdPrsntIndicator 3 "NotAvailable" 2 "Error" 1 "RandomNumberIsPresent" 0 "RandomNumberIsNotPresent";
VAL_ 2631728894 AntitheftModifyPwdStates 3 "Notvalid" 2 "EmptyOfPwdsThsSttIndctsThtCmpnn" 1 "FullofPwds" 0 "OkThsSttIndctsThtRqWsSccssfllyP";
VAL_ 2631728894 AntitheftPwdValidIndicator 3 "NotAvailable" 2 "Error" 1 "PwdIsAValidatedPassword" 0 "PwdIsNotAValidatedPassword";
VAL_ 2631794430 AntitheftCmdStates 6 "111NotDefined" 5 "Login" 4 "ChckSttsThsSttRprsntsARqTChckTS" 3 "LockorUnlock" 2 "ChngPwdThsSttRprsntsARqTCmpnntT" 1 "DeletePwd" 0 "AddPwdThsSttRprsntsARqTCmpnntTA";
VAL_ 2631794430 AntitheftDesiredExitModeStates 3 "NtAvlblThsSttIsIndctsThtOptnIsN" 2 "NotDefined" 1 "LckWhnKyffThsSttIsUsdTIndctThtC" 0 "LckUpnOprtrRqThsSttIsUsdTIndctT";
VAL_ 2631794430 AntthftEncryptonIndicatorStates 3 "NtAvlblThsSttIsUsdTIndctThtARnd" 2 "NotDefined" 1 "EncryptdCdPrsntThsSttIsUsdTIndc" 0 "EncryptnSdRqThsSttRprsntsARqstT";
VAL_ 2365478910 ElctrncShckAbsrbrCtrlMdLft_TgAxl 3 "NotAvailable" 2 "Error" 1 "NormalOperationDampersActive" 0 "NormalOperationDampersPassive";
VAL_ 2365478910 ElctrncShckAbsrbrCtrlMdRearAxle 3 "NotAvailable" 2 "Error" 1 "NormalOperationDampersActive" 0 "NormalOperationDampersPassive";
VAL_ 2365478910 ElctrncShckAbsrbrCtrlMdFrntAxle 3 "NotAvailable" 2 "Error" 1 "NormalOperationDampersActive" 0 "NormalOperationDampersPassive";
VAL_ 2560950014 FailureModeIdentifier1 31 "Not available" 19 "Received network data in error" 18 "Below normal (moderately severe)" 17 "Below normal (least severe)" 16 "Above normal (moderately severe)" 15 "Above normal (least severe)" 14 "Special intstructions" 13 "Out of calibration" 12 "Bad intelligent device" 11 "Root cause not known" 10 "Abnormal rate of change" 9 "Abnormal update rate" 8 "Abnormal frequency" 7 "Mechanical system not responding" 6 "Current above normal" 5 "Current below normal" 4 "Voltage below normal" 3 "Voltage above normal" 2 "Data erratic" 1 "Below normal (most severe)" 0 "Above normal (most severe)";
VAL_ 2565869566 Aftrtrtmnt1OtltGsSnsrPwerStatus 3 "NotAvailable" 2 "Error" 1 "InRange" 0 "NotInRange";
VAL_ 2565869566 Aftrtrtmnt1OtltGsSnsrHeaterCtrl 3 "HeaterOff" 2 "Preheat1" 1 "Preheat2" 0 "Automatic";
VAL_ 2565869566 Aftrtrtmnt1OtltWdRngO2RdngStble 3 "NotAvailable" 2 "Error" 1 "Stable" 0 "NotStable";
VAL_ 2565869566 Aftrtrtmnt1OtltNOxReadingStable 3 "NotAvailable" 2 "Error" 1 "Stable" 0 "NotStable";
VAL_ 2565869566 Aftrtrtmnt1OtletGasSensorAtTemp 3 "NotAvailable" 2 "Error" 1 "InRange" 0 "NotInRange";
VAL_ 2566749182 DslPrtclteFilter1AshLoadPercent 4 "LevelIsTargetAshServiceInterval";
VAL_ 2566749182 DslPrtcltFilter1SootLoadPercent 4 "LvlIsActvRgnerationTriggerLevel";
VAL_ 2566749182 Aftrtrtmnt1DslPrtcltFltrStLdRgnr 4 "IsLvlAtWhchActvDslPrtcltFltrRgn";
VAL_ 2566758142 Aftrtreatment2AirEnableActuator 3 "notAvailable" 2 "reservedForSAEAssignment" 1 "active" 0 "notActive";
VAL_ 2566758142 Aftertreatment2PurgeAirActuator 3 "notAvailable" 2 "reservedForSAEAssignment" 1 "active" 0 "notActive";
VAL_ 2566758142 Aftrtrtmnt2AtmzationAirActuator 3 "notAvailable" 2 "reservedForSAEAssignment" 1 "active" 0 "notActive";
VAL_ 2566758142 Aftertreatment2AirSystemRelay 3 "notAvailable" 2 "reservedForSAEAssignment" 1 "active" 0 "notActive";
VAL_ 2566758654 Aftrtrtmnt2FlInjctor1HeaterCtrl 4 "Max";
VAL_ 2566758654 Aftrtratment2FuelEnableActuator 3 "notAvailable" 2 "reservedForSAEAssignment" 1 "active" 0 "notActive";
VAL_ 2566758654 Aftrtratment2RegenerationStatus 3 "notAvailable" 2 "reservedForSAEAssignment" 1 "active" 0 "notActive";
VAL_ 2566758654 Aftertreatment2Ignt 3 "notAvailable" 2 "reservedForSAEAssignment" 1 "active" 0 "notActive";
VAL_ 2566758654 Aftrtreatment2FuelDrainActuator 3 "notAvailable" 2 "reservedForSAEAssignment" 1 "active" 0 "notActive";
VAL_ 2565869822 Aftrtrtmnt2IntkGsSnsrPwerStatus 3 "NotAvailable" 2 "Error" 1 "InRange" 0 "NotInRange";
VAL_ 2565869822 Aftrtrtmnt2IntkGsSnsrHeaterCtrl 3 "HeaterOff" 2 "Preheat1" 1 "Preheat2" 0 "Automatic";
VAL_ 2565869822 Aftrtrtmnt2IntkWdRngO2RdngStble 3 "NotAvailable" 2 "Error" 1 "Stable" 0 "NotStable";
VAL_ 2565869822 Aftrtrtmnt2IntkNOxReadingStable 3 "NotAvailable" 2 "Error" 1 "Stable" 0 "NotStable";
VAL_ 2565869822 Aftrtrtmnt2IntkeGasSensorAtTemp 3 "NotAvailable" 2 "Error" 1 "InRange" 0 "NotInRange";
VAL_ 2565870078 Aftrtrtmnt2OtltGsSnsrPwerStatus 3 "NotAvailable" 2 "Error" 1 "InRange" 0 "NotInRange";
VAL_ 2565870078 Aftrtrtmnt2OtltGsSnsrHeaterCtrl 3 "HeaterOff" 2 "Preheat1" 1 "Preheat2" 0 "Automatic";
VAL_ 2565870078 Aftrtrtmnt2OtltWdRngO2RdngStble 3 "NotAvailable" 2 "Error" 1 "Stable" 0 "NotStable";
VAL_ 2565870078 Aftrtrtmnt2OtltNOxReadingStable 3 "NotAvailable" 2 "Error" 1 "Stable" 0 "NotStable";
VAL_ 2565870078 Aftrtrtmnt2OtletGasSensorAtTemp 3 "NotAvailable" 2 "Error" 1 "InRange" 0 "NotInRange";
VAL_ 2566748926 DslPrtclteFilter2AshLoadPercent 4 "LevelIsTargetAshServiceInterval";
VAL_ 2566748926 DslPrtcltFilter2SootLoadPercent 4 "LvlIsActvRgnerationTriggerLevel";
VAL_ 2566748926 Aftrtrtmnt2DslPrtcltFltrStLdRgnr 4 "IsLvlAtWhchActvDslPrtcltFltrRgn";
VAL_ 2365428478 EngEmergencyShutdownIndication 3 "DontCare_TakeNoAction" 2 "Reserved" 1 "On" 0 "Off";
VAL_ 2365428478 EngCtrlledShutdownRq 3 "DontCare_TakeNoAction" 2 "Reserved" 1 "On" 0 "Off";
VAL_ 2365428478 EngCoolantCirculatingPumpCtrl 3 "DontCare_TakeNoAction" 2 "Reserved" 1 "On" 0 "Off";
VAL_ 2365428478 EngBlock_CoolantPreheaterCtrl 3 "Unavailable" 2 "Reserved" 1 "On" 0 "Off";
VAL_ 2365428478 EngElctrclSystmPwrCnsrvtionCtrl 3 "Unavailable" 2 "Reserved" 1 "On" 0 "Off";
VAL_ 2365428478 EngOilPreheaterCtrl 3 "DontCare_TakeNoAction" 2 "Reserved" 1 "On" 0 "Off";
VAL_ 2365428478 EngOilPrimingPumpCtrl 3 "Unavailable" 2 "Reserved" 1 "On" 0 "Off";
VAL_ 2365428478 EngFuelShutoffValveLeakTestCtrl 3 "DontCare_TakeNoAction" 2 "Reserved" 1 "On" 0 "Off";
VAL_ 2365428478 EngFuelShutoff2Ctrl 3 "DontCare_TakeNoAction" 2 "Reserved" 1 "Closed" 0 "Open";
VAL_ 2365428478 EngFuelShutoff1Ctrl 3 "DontCare_TakeNoAction" 2 "Reserved" 1 "Closed" 0 "Open";
VAL_ 2365428478 EngFuelShutoffVentCtrl 3 "DontCare_TakeNoAction" 2 "Reserved" 1 "Open" 0 "Closed";
VAL_ 2365428478 FuelPumpPrimerCtrl 3 "Unavailable" 2 "Reserved" 1 "Activate" 0 "Deactivate";
